VERSION ""

NS_ :

BS_:

BU_: HU

BO_ 642 HU_ADASSwch: 8 HU
 SG_ HU_ACCSet : 1|2@0+ (1,0) [0|3] "" CGW
 SG_ HU_FRMMsgErr : 11|1@0+ (1,0) [0|1] "" CGW
 SG_ HU_TJASet : 13|2@0+ (1,0) [0|3] "" CGW
 SG_ HU_PedestrianProtcSwch : 15|2@0+ (1,0) [0|3] "" CGW
 SG_ HU_HBASet : 17|2@0+ (1,0) [0|3] "" CGW
 SG_ HU_LKASet : 19|2@0+ (1,0) [0|3] "" CGW
 SG_ HU_ADASSnvtyReq : 21|2@0+ (1,0) [0|3] "" CGW
 SG_ HU_LDWSet : 23|2@0+ (1,0) [0|3] "" TBox,CGW
 SG_ HU_FCWRgReq : 3|2@0+ (1,0) [0|3] "" CGW
 SG_ HU_DispdVhclSpd : 30|13@0+ (0.05625,0) [0|300] "" CGW
 SG_ HU_UnitOfDispdVhclSpd : 31|1@0+ (1,0) [0|1] "" CGW
 SG_ HU_DispFltSts : 33|1@0+ (1,0) [0|1] "" CGW
 SG_ HU_BSD_LCASet : 41|2@0+ (1,0) [0|3] "" CGW
 SG_ HU_UPASet : 43|2@0+ (1,0) [0|3] "" PAS,CGW
 SG_ HU_APASlotTypSelt : 45|2@0+ (1,0) [0|3] "" CGW
 SG_ HU_APAEnable : 47|2@0+ (1,0) [0|3] "" CGW
 SG_ HU_FCWSet : 5|2@0+ (1,0) [0|3] "" CGW
 SG_ HU_RCTASet : 53|2@0+ (1,0) [0|3] "" CGW
 SG_ HU_DOWSet : 55|2@0+ (1,0) [0|3] "" CGW
 SG_ ALM_RRDoorLEDFltFb : 60|1@0+ (1,0) [0|1] "" CGW
 SG_ ALM_FRDoorLEDFltFb : 61|1@0+ (1,0) [0|1] "" CGW
 SG_ ALM_RLDoorLEDFltFb : 62|1@0+ (1,0) [0|1] "" CGW
 SG_ ALM_FLDoorLEDFltFb : 63|1@0+ (1,0) [0|1] "" CGW
 SG_ HU_AEBSet : 7|2@0+ (1,0) [0|3] "" CGW

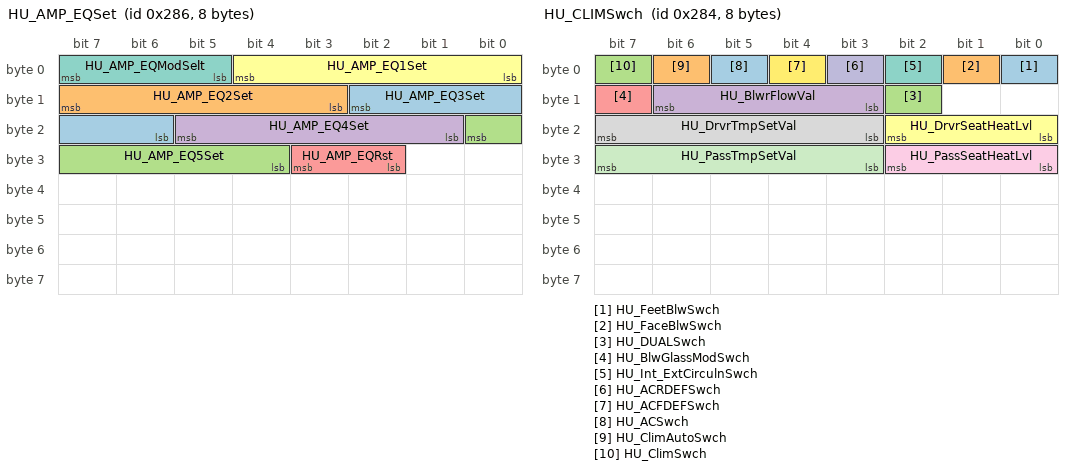
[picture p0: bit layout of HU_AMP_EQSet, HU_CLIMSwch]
BO_ 646 HU_AMP_EQSet: 8 HU
 SG_ HU_AMP_EQ3Set : 10|5@0+ (1,0) [0|31] "" AMP
 SG_ HU_AMP_EQ2Set : 15|5@0+ (1,0) [0|31] "" AMP
 SG_ HU_AMP_EQ5Set : 16|5@0+ (1,0) [0|31] "" AMP
 SG_ HU_AMP_EQ4Set : 21|5@0+ (1,0) [0|31] "" AMP
 SG_ HU_AMP_EQRst : 27|2@0+ (1,0) [0|3] "" AMP
 SG_ HU_AMP_EQ1Set : 4|5@0+ (1,0) [0|31] "" AMP
 SG_ HU_AMP_EQModSelt : 7|3@0+ (1,0) [0|7] "" AMP

BO_ 645 HU_AMP_Set: 8 HU
 SG_ HU_AMP_MuteSet : 1|2@0+ (1,0) [0|3] "" AMP
 SG_ HU_AMP_VhclAlrmVolStepSet : 11|3@0+ (1,0) [0|7] "" AMP
 SG_ HU_AMP_VSCModSeln : 13|2@0+ (1,0) [0|3] "" AMP
 SG_ HU_AMP_LondnessSwch : 15|2@0+ (1,0) [0|3] "" AMP
 SG_ HU_AMP_MainVolStepSet : 19|4@0+ (1,0) [0|15] "" AMP
 SG_ HU_AMP_AudSrcInform : 23|4@0+ (1,0) [0|15] "" AMP
 SG_ HU_AMP_NaviVolStepSet : 29|4@0+ (1,0) [0|15] "" AMP
 SG_ HU_AMP_ESSModSelt : 3|2@0+ (1,0) [0|3] "" AMP
 SG_ HU_AMP_Navi_VRModSet : 31|2@0+ (1,0) [0|3] "" AMP
 SG_ HU_AMP_IntConctVolStepSet : 35|4@0+ (1,0) [0|15] "" AMP
 SG_ HU_AMP_CallVolStepSet : 39|4@0+ (1,0) [0|15] "" AMP
 SG_ HU_AMP_OutputCH_RR : 41|2@0+ (1,0) [0|3] "" AMP
 SG_ HU_AMP_OutputCH_LR : 43|2@0+ (1,0) [0|3] "" AMP
 SG_ HU_AMP_OutputCH_RF : 45|2@0+ (1,0) [0|3] "" AMP
 SG_ HU_AMP_OutputCH_LF : 47|2@0+ (1,0) [0|3] "" AMP
 SG_ HU_AMP_ESSSwch : 5|2@0+ (1,0) [0|3] "" AMP
 SG_ HU_AMP_LeRiAudBalnSet : 55|5@0+ (1,0) [0|31] "" AMP
 SG_ HU_AMP_FrntReAudBalnSet : 63|5@0+ (1,0) [0|31] "" AMP

BO_ 644 HU_CLIMSwch: 8 HU
 SG_ HU_FeetBlwSwch : 0|1@0+ (1,0) [0|1] "" CGW
 SG_ HU_FaceBlwSwch : 1|1@0+ (1,0) [0|1] "" CGW
 SG_ HU_DUALSwch : 10|1@0+ (1,0) [0|1] "" CGW
 SG_ HU_BlwrFlowVal : 14|4@0+ (1,0) [0|15] "" CGW
 SG_ HU_BlwGlassModSwch : 15|1@0+ (1,0) [0|1] "" CGW
 SG_ HU_DrvrSeatHeatLvl : 18|3@0+ (1,0) [0|7] "" CGW
 SG_ HU_Int_ExtCirculnSwch : 2|1@0+ (1,0) [0|1] "" CGW
 SG_ HU_DrvrTmpSetVal : 23|5@0+ (1,0) [0|31] "" CGW
 SG_ HU_PassSeatHeatLvl : 26|3@0+ (1,0) [0|7] "" CGW
 SG_ HU_ACRDEFSwch : 3|1@0+ (1,0) [0|1] "" CGW
 SG_ HU_PassTmpSetVal : 31|5@0+ (1,0) [0|31] "" CGW
 SG_ HU_ACFDEFSwch : 4|1@0+ (1,0) [0|1] "" CGW
 SG_ HU_ACSwch : 5|1@0+ (1,0) [0|1] "" CGW
 SG_ HU_ClimAutoSwch : 6|1@0+ (1,0) [0|1] "" CGW
 SG_ HU_ClimSwch : 7|1@0+ (1,0) [0|1] "" CGW

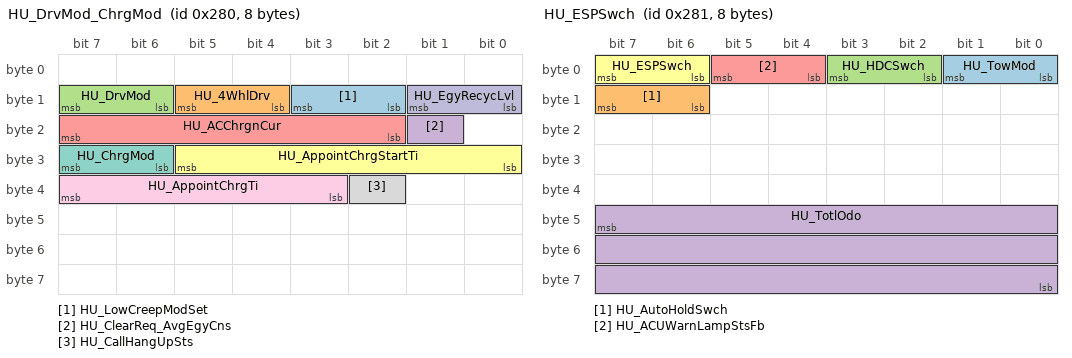
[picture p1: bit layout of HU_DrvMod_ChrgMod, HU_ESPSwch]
BO_ 640 HU_DrvMod_ChrgMod: 8 HU
 SG_ HU_LowCreepModSet : 11|2@0+ (1,0) [0|3] "" CGW
 SG_ HU_4WhlDrv : 13|2@0+ (1,0) [0|3] "" CGW
 SG_ HU_DrvMod : 15|2@0+ (1,0) [0|3] "" CGW
 SG_ HU_ClearReq_AvgEgyCns : 17|1@0+ (1,0) [0|1] "" CGW
 SG_ HU_ACChrgnCur : 23|6@0+ (1,0) [0|40] "A" CGW
 SG_ HU_AppointChrgStartTi : 29|6@0+ (1,0) [0|47] "" TBox
 SG_ HU_ChrgMod : 31|2@0+ (1,0) [0|3] "" TBox
 SG_ HU_CallHangUpSts : 34|1@0+ (1,0) [0|1] "" TBox
 SG_ HU_AppointChrgTi : 39|5@0+ (1,0) [0|23] "" TBox
 SG_ HU_EgyRecycLvl : 9|2@0+ (1,0) [0|3] "" CGW

BO_ 641 HU_ESPSwch: 8 HU
 SG_ HU_TowMod : 1|2@0+ (1,0) [0|3] "" CGW
 SG_ HU_AutoHoldSwch : 15|2@0+ (1,0) [0|3] "" CGW
 SG_ HU_HDCSwch : 3|2@0+ (1,0) [0|3] "" CGW
 SG_ HU_TotlOdo : 47|24@0+ (0.1,0) [0|999999.9] "km" TBox,CGW
 SG_ HU_ACUWarnLampStsFb : 5|2@0+ (1,0) [0|3] "" CGW
 SG_ HU_ESPSwch : 7|2@0+ (1,0) [0|3] "" CGW

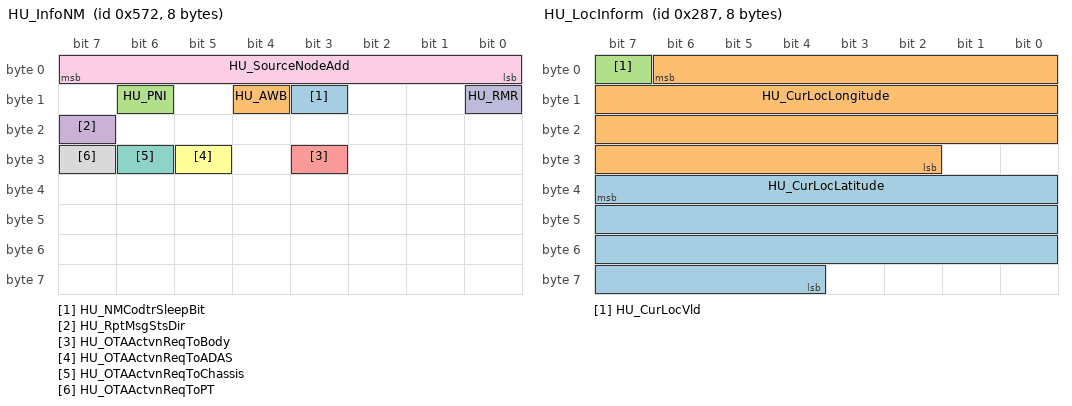
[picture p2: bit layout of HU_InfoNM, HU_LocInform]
BO_ 1394 HU_InfoNM: 8 HU
 SG_ HU_NMCodtrSleepBit : 11|1@0+ (1,0) [0|1] "" TBox,AMP,CGW
 SG_ HU_AWB : 12|1@0+ (1,0) [0|1] "" TBox,AMP,CGW
 SG_ HU_PNI : 14|1@0+ (1,0) [0|1] "" TBox,AMP,CGW
 SG_ HU_RptMsgStsDir : 23|1@0+ (1,0) [0|1] "" Vector__XXX
 SG_ HU_OTAActvnReqToBody : 27|1@0+ (1,0) [0|1] "" CGW
 SG_ HU_OTAActvnReqToADAS : 29|1@0+ (1,0) [0|1] "" CGW
 SG_ HU_OTAActvnReqToChassis : 30|1@0+ (1,0) [0|1] "" CGW
 SG_ HU_OTAActvnReqToPT : 31|1@0+ (1,0) [0|1] "" CGW
 SG_ HU_SourceNodeAdd : 7|8@0+ (1,0) [114|114] "" TBox,AMP,CGW
 SG_ HU_RMR : 8|1@0+ (1,0) [0|1] "" TBox,AMP,CGW

BO_ 647 HU_LocInform: 8 HU
 SG_ HU_CurLocLatitude : 39|28@0+ (0.000001,-90) [-90|90] "degree" TBox
 SG_ HU_CurLocLongitude : 6|29@0+ (0.000001,-180) [-180|180] "degree" TBox
 SG_ HU_CurLocVld : 7|1@0+ (1,0) [0|1] "" TBox

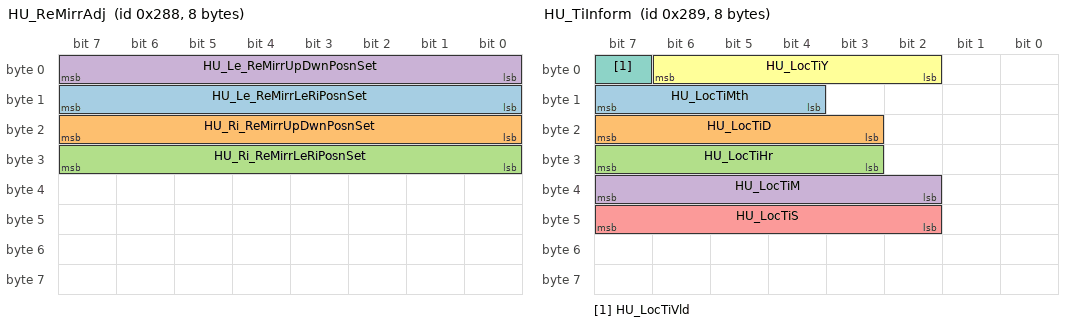
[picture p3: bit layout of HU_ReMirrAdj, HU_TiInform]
BO_ 648 HU_ReMirrAdj: 8 HU
 SG_ HU_Le_ReMirrLeRiPosnSet : 15|8@0+ (1,0) [0|255] "" CGW
 SG_ HU_Ri_ReMirrUpDwnPosnSet : 23|8@0+ (1,0) [0|255] "" CGW
 SG_ HU_Ri_ReMirrLeRiPosnSet : 31|8@0+ (1,0) [0|255] "" CGW
 SG_ HU_Le_ReMirrUpDwnPosnSet : 7|8@0+ (1,0) [0|255] "" CGW

BO_ 649 HU_TiInform: 8 HU
 SG_ HU_LocTiMth : 15|4@0+ (1,0) [1|12] "month" TBox,CGW
 SG_ HU_LocTiD : 23|5@0+ (1,0) [1|31] "day" TBox,CGW
 SG_ HU_LocTiHr : 31|5@0+ (1,0) [0|23] "hour" TBox,CGW
 SG_ HU_LocTiM : 39|6@0+ (1,0) [0|59] "minute" TBox,CGW
 SG_ HU_LocTiS : 47|6@0+ (1,0) [0|59] "second" TBox,CGW
 SG_ HU_LocTiY : 6|5@0+ (1,2019) [2019|2050] "year" TBox,CGW
 SG_ HU_LocTiVld : 7|1@0+ (1,0) [0|1] "" TBox,CGW

BO_ 643 HU_iBCMSwch: 8 HU
 SG_ HU_SwchBkGndLiAdj : 15|4@0+ (1,0) [0|15] "" CGW
 SG_ HU_ForcingPwrON : 16|1@0+ (1,0) [0|1] "" CGW
 SG_ HU_FolwHomeTiAdj : 19|3@0+ (1,0) [0|7] "" CGW
 SG_ HU_FolwHomeReq : 21|2@0+ (1,0) [0|3] "" CGW
 SG_ HU_MirrAutoFoldSet : 23|2@0+ (1,0) [0|3] "" CGW
 SG_ HU_PBDReq : 25|2@0+ (1,0) [0|3] "" CGW
 SG_ HU_LokgCarSet : 27|2@0+ (1,0) [0|3] "" AMP,CGW
 SG_ HU_VSG_PWSSwch : 29|2@0+ (1,0) [0|3] "" AMP,CGW
 SG_ HU_HeadlampHeiAdj : 3|3@0+ (1,0) [0|7] "" CGW
 SG_ HU_AutoSpdLockSet : 31|2@0+ (1,0) [0|3] "" CGW
 SG_ HU_SrSwchReq : 37|2@0+ (1,0) [0|3] "" CGW
 SG_ HU_WprMaintMod : 39|2@0+ (1,0) [0|3] "" CGW
 SG_ HU_SeatVertAdjMotTarPosn : 47|7@0+ (1,0) [0|100] "%" CGW
 SG_ HU_SeatHznAdjMotTarPosn : 55|7@0+ (1,0) [0|100] "%" CGW
 SG_ HU_LiReq : 6|3@0+ (1,0) [0|7] "" CGW
 SG_ HU_SeatTltgAdjMotTarPosn : 63|7@0+ (1,0) [0|100] "%" CGW
 SG_ HU_DeActvSt : 7|1@0+ (1,0) [0|1] "" CGW

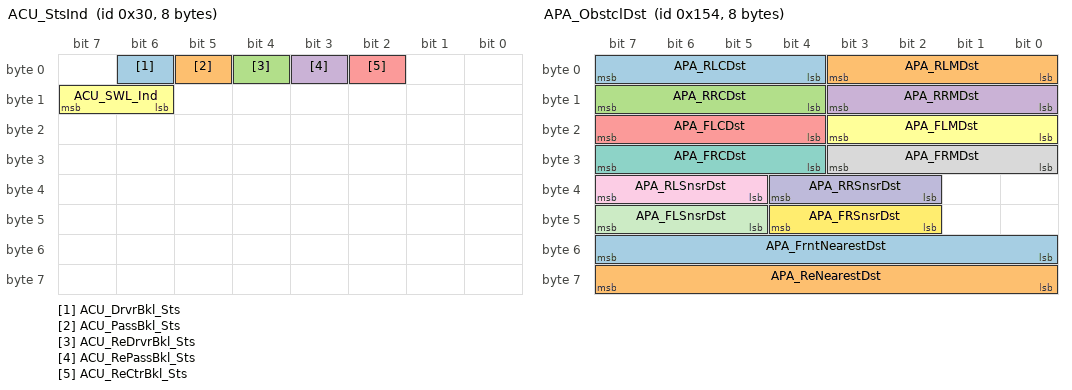
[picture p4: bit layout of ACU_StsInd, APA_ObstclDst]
BO_ 48 ACU_StsInd: 8 CGW
 SG_ ACU_DrvrBkl_Sts : 6|1@0+ (1,0) [0|1] "" TBox,HU
 SG_ ACU_PassBkl_Sts : 5|1@0+ (1,0) [0|1] "" HU
 SG_ ACU_ReDrvrBkl_Sts : 4|1@0+ (1,0) [0|1] "" HU
 SG_ ACU_RePassBkl_Sts : 3|1@0+ (1,0) [0|1] "" HU
 SG_ ACU_ReCtrBkl_Sts : 2|1@0+ (1,0) [0|1] "" HU
 SG_ ACU_SWL_Ind : 15|2@0+ (1,0) [0|3] "" HU

BO_ 896 AMP_Sts: 1 AMP
 SG_ AMP_HU_PwrSt : 7|2@0+ (1,0) [0|3] "" HU

BO_ 340 APA_ObstclDst: 8 CGW
 SG_ APA_RLCDst : 7|4@0+ (1,0) [0|2] "" HU
 SG_ APA_RLMDst : 3|4@0+ (1,0) [0|15] "" HU
 SG_ APA_RRCDst : 15|4@0+ (1,0) [0|2] "" HU
 SG_ APA_RRMDst : 11|4@0+ (1,0) [0|15] "" HU
 SG_ APA_FLCDst : 23|4@0+ (1,0) [0|2] "" HU
 SG_ APA_FLMDst : 19|4@0+ (1,0) [0|15] "" HU
 SG_ APA_FRCDst : 31|4@0+ (1,0) [0|2] "" HU
 SG_ APA_FRMDst : 27|4@0+ (1,0) [0|15] "" HU
 SG_ APA_RLSnsrDst : 39|3@0+ (1,0) [0|2] "" HU
 SG_ APA_RRSnsrDst : 36|3@0+ (1,0) [0|2] "" HU
 SG_ APA_FLSnsrDst : 47|3@0+ (1,0) [0|2] "" HU
 SG_ APA_FRSnsrDst : 44|3@0+ (1,0) [0|2] "" HU
 SG_ APA_FrntNearestDst : 55|8@0+ (1,0) [0|250] "cm" HU
 SG_ APA_ReNearestDst : 63|8@0+ (1,0) [0|250] "cm" HU

BO_ 535 BCU_ModlTmp: 8 CGW
 SG_ BCU_RemChrgTi : 33|10@0+ (1,0) [0|1023] "min" TBox,HU

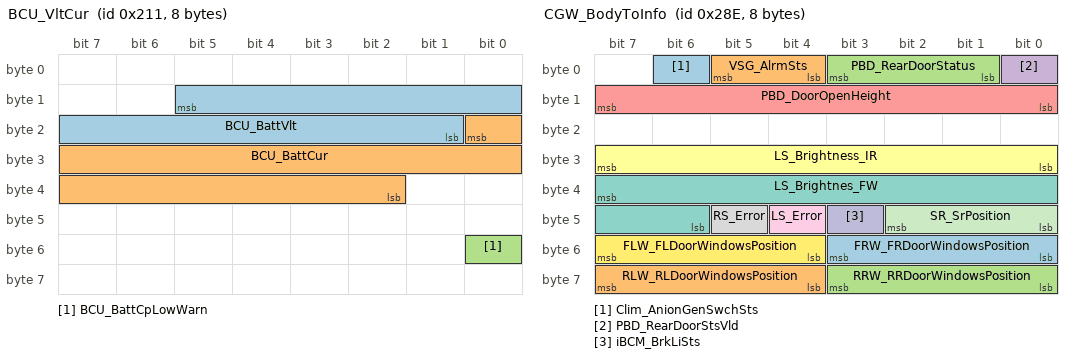
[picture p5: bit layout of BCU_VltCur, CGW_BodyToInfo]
BO_ 529 BCU_VltCur: 8 CGW
 SG_ BCU_BattVlt : 13|13@0+ (0.1,0) [0|500] "V" TBox,HU
 SG_ BCU_BattCur : 16|15@0+ (0.1,-1200) [-1200|1200] "A" TBox,HU
 SG_ BCU_BattCpLowWarn : 48|1@0+ (1,0) [0|1] "" TBox,HU

BO_ 536 BCU_WarnInfo: 8 CGW
 SG_ BCU_BattOverTmp : 15|1@0+ (1,0) [0|1] "" TBox,HU

BO_ 653 CGW_ADASToInfo: 8 CGW
 SG_ APA_SysFltFlg : 7|2@0+ (1,0) [0|3] "" HU
 SG_ APA_WarnIdn : 5|2@0+ (1,0) [0|3] "" HU
 SG_ APA_WarnTyp : 3|4@0+ (1,0) [0|15] "" HU
 SG_ APA_RecoverINTIndcn : 15|3@0+ (1,0) [0|7] "" HU
 SG_ APA_QuitIndcn : 12|5@0+ (1,0) [0|31] "" HU
 SG_ APA_FctIndcn : 23|3@0+ (1,0) [0|7] "" HU
 SG_ APA_St : 20|3@0+ (1,0) [0|7] "" HU
 SG_ APA_PrkSlotSt : 17|2@0+ (1,0) [0|3] "" HU
 SG_ APA_SeltSide : 31|2@0+ (1,0) [0|2] "" HU
 SG_ APA_PrkNotice : 28|5@0+ (1,0) [0|31] "" HU
 SG_ APA_Mod : 39|3@0+ (1,0) [0|7] "" HU
 SG_ APA_PAS_BtnPrs : 36|1@0+ (1,0) [0|1] "" HU
 SG_ APA_PrkgPerc : 47|7@0+ (1,0) [0|100] "%" HU
 SG_ RMR_L_RCTA_WarnReq : 55|2@0+ (1,0) [0|3] "" HU
 SG_ RMR_R_RCTA_WarnReq : 53|2@0+ (1,0) [0|3] "" HU
 SG_ RMR_RSDS_BliSts : 51|1@0+ (1,0) [0|1] "" HU
 SG_ RMR_RCTAResp : 50|1@0+ (1,0) [0|1] "" HU
 SG_ RMR_LCAResp : 49|1@0+ (1,0) [0|1] "" HU
 SG_ RMR_DOWResp : 48|1@0+ (1,0) [0|1] "" HU
 SG_ RMR_RSDS_LCA_RCTA_ErrSts : 40|1@0+ (1,0) [0|1] "" HU
 SG_ RMR_RSDS_DOW_ErrSts : 63|2@0+ (1,0) [0|3] "" HU
 SG_ RMR_L_DOW_WarnReq : 61|3@0+ (1,0) [0|7] "" HU
 SG_ RMR_R_DOW_WarnReq : 58|3@0+ (1,0) [0|7] "" HU
 SG_ RMR_L_BSD_LCA_WarnReq : 35|2@0+ (1,0) [0|3] "" HU
 SG_ RMR_R_BSD_LCA_WarnReq : 33|2@0+ (1,0) [0|3] "" HU

BO_ 654 CGW_BodyToInfo: 8 CGW
 SG_ Clim_AnionGenSwchSts : 6|1@0+ (1,0) [0|1] "" TBox,HU
 SG_ VSG_AlrmSts : 5|2@0+ (1,0) [0|3] "" HU
 SG_ PBD_RearDoorStatus : 3|3@0+ (1,0) [0|7] "" HU
 SG_ PBD_RearDoorStsVld : 0|1@0+ (1,0) [0|1] "" HU
 SG_ PBD_DoorOpenHeight : 15|8@0+ (1,0) [0|100] "%" HU
 SG_ LS_Brightness_IR : 31|8@0+ (400,0) [0|101200] "Lux" HU
 SG_ LS_Brightnes_FW : 39|10@0+ (6,0) [0|6126] "Lux" HU
 SG_ RS_Error : 45|1@0+ (1,0) [0|1] "" HU
 SG_ LS_Error : 44|1@0+ (1,0) [0|1] "" HU
 SG_ iBCM_BrkLiSts : 43|1@0+ (1,0) [0|1] "" HU
 SG_ SR_SrPosition : 42|3@0+ (1,0) [0|7] "" TBox,HU
 SG_ FLW_FLDoorWindowsPosition : 55|4@0+ (1,0) [0|15] "" TBox,HU
 SG_ FRW_FRDoorWindowsPosition : 51|4@0+ (1,0) [0|15] "" TBox,HU
 SG_ RLW_RLDoorWindowsPosition : 63|4@0+ (1,0) [0|15] "" TBox,HU
 SG_ RRW_RRDoorWindowsPosition : 59|4@0+ (1,0) [0|15] "" TBox,HU

BO_ 371 CGW_PTToInfo_2: 8 CGW
 SG_ CDU_OBCACVlt : 40|9@0+ (1,0) [0|500] "V" HU
 SG_ CDU_OBCACCur : 63|8@0+ (0.5,-63) [-63|63] "A" HU

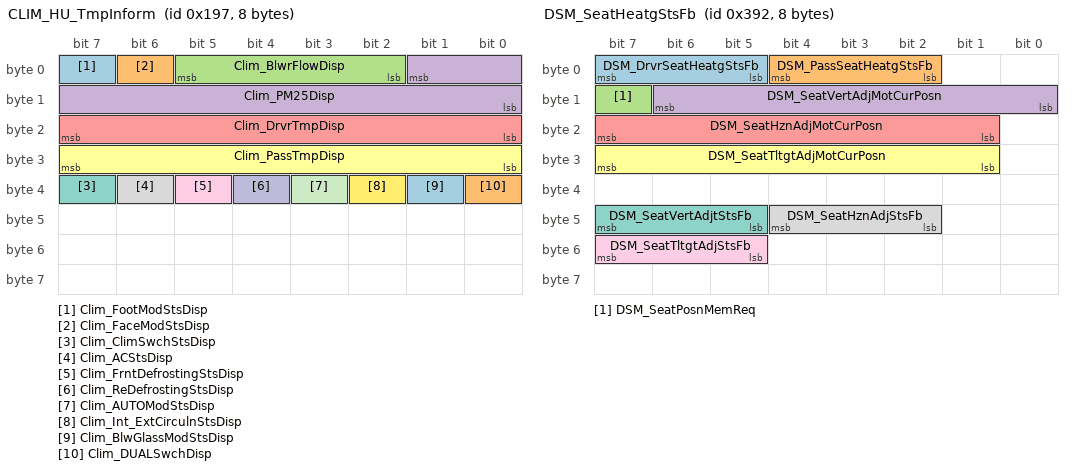
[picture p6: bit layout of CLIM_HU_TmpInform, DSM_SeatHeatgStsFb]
BO_ 407 CLIM_HU_TmpInform: 8 CGW
 SG_ Clim_FootModStsDisp : 7|1@0+ (1,0) [0|1] "" HU
 SG_ Clim_FaceModStsDisp : 6|1@0+ (1,0) [0|1] "" HU
 SG_ Clim_BlwrFlowDisp : 5|4@0+ (1,0) [0|15] "" TBox,HU
 SG_ Clim_PM25Disp : 1|10@0+ (1,0) [0|999] "ug/m3" TBox,HU
 SG_ Clim_DrvrTmpDisp : 23|8@0+ (1,0) [0|255] "" HU
 SG_ Clim_PassTmpDisp : 31|8@0+ (1,0) [0|255] "" HU
 SG_ Clim_ClimSwchStsDisp : 39|1@0+ (1,0) [0|1] "" HU
 SG_ Clim_ACStsDisp : 38|1@0+ (1,0) [0|1] "" HU
 SG_ Clim_FrntDefrostingStsDisp : 37|1@0+ (1,0) [0|1] "" HU
 SG_ Clim_ReDefrostingStsDisp : 36|1@0+ (1,0) [0|1] "" HU
 SG_ Clim_AUTOModStsDisp : 35|1@0+ (1,0) [0|1] "" HU
 SG_ Clim_Int_ExtCirculnStsDisp : 34|1@0+ (1,0) [0|1] "" HU
 SG_ Clim_BlwGlassModStsDisp : 33|1@0+ (1,0) [0|1] "" HU
 SG_ Clim_DUALSwchDisp : 32|1@0+ (1,0) [0|1] "" HU

BO_ 914 DSM_SeatHeatgStsFb: 8 CGW
 SG_ DSM_DrvrSeatHeatgStsFb : 7|3@0+ (1,0) [0|7] "" HU
 SG_ DSM_PassSeatHeatgStsFb : 4|3@0+ (1,0) [0|7] "" HU
 SG_ DSM_SeatPosnMemReq : 15|1@0+ (1,0) [0|1] "" HU
 SG_ DSM_SeatVertAdjMotCurPosn : 14|7@0+ (1,0) [0|100] "%" HU
 SG_ DSM_SeatHznAdjMotCurPosn : 23|7@0+ (1,0) [0|100] "%" HU
 SG_ DSM_SeatTltgtAdjMotCurPosn : 31|7@0+ (1,0) [0|100] "%" HU
 SG_ DSM_SeatVertAdjtStsFb : 47|3@0+ (1,0) [0|7] "" HU
 SG_ DSM_SeatHznAdjStsFb : 44|3@0+ (1,0) [0|7] "" HU
 SG_ DSM_SeatTltgtAdjStsFb : 55|3@0+ (1,0) [0|7] "" HU

BO_ 576 FRM_PEBSToESP: 8 CGW
 SG_ FRM_PEBS_AEBReq : 15|1@0+ (1,0) [0|1] "" HU
 SG_ FRM_ACCMod : 44|3@0+ (1,0) [0|7] "" HU
 SG_ FRM_DispVelocitySet : 16|9@0+ (0.5,0) [0|255.5] "km/h" HU
 SG_ FRM_TiGapSet : 39|2@0+ (1,0) [0|3] "" HU
 SG_ FRM_TextInform : 37|3@0+ (1,0) [0|7] "" HU
 SG_ FRM_FCWSetFb : 34|1@0+ (1,0) [0|1] "" HU
 SG_ FRM_AEBSetFb : 33|1@0+ (1,0) [0|1] "" HU
 SG_ FRM_PedestrianProtcSwchFb : 32|1@0+ (1,0) [0|1] "" HU
 SG_ FRM_DxTarObj : 47|2@0+ (1,0) [0|3] "" HU
 SG_ FRM_ObjVld : 45|1@0+ (1,0) [0|1] "" HU
 SG_ FRM_AEB_Flt : 20|1@0+ (1,0) [0|1] "" HU
 SG_ FRM_FCW_LatentWarn : 19|1@0+ (1,0) [0|1] "" HU
 SG_ FRM_FCW_Flt : 18|1@0+ (1,0) [0|1] "" HU
 SG_ FRM_FCW_PreWarn : 17|1@0+ (1,0) [0|1] "" HU
 SG_ FRM_TakeOverReq : 52|1@0+ (1,0) [0|1] "" HU
 SG_ FRM_TJATextInform : 41|2@0+ (1,0) [0|3] "" HU
 SG_ FRM_TJAMod : 55|3@0+ (1,0) [0|7] "" HU
 SG_ FRM_3_MsgRolgCntr : 51|4@0+ (1,0) [0|15] "" HU
 SG_ FRM_3_CRCChks : 63|8@0+ (1,0) [0|255] "" HU

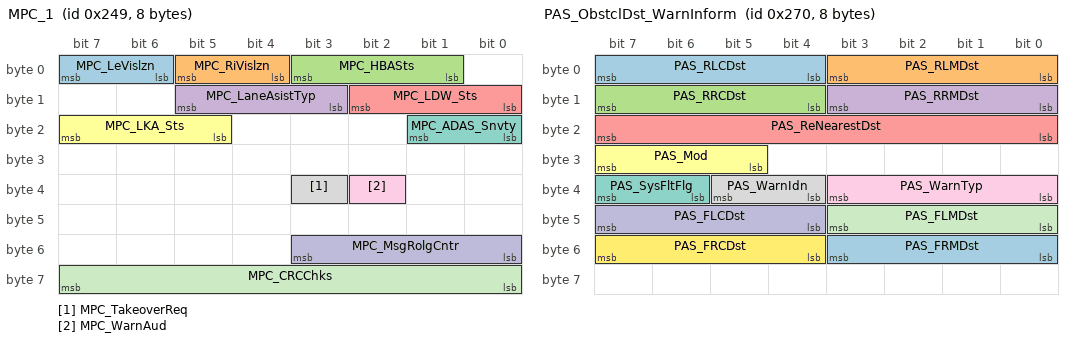
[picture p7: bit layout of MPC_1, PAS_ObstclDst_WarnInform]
BO_ 585 MPC_1: 8 CGW
 SG_ MPC_LeVislzn : 7|2@0+ (1,0) [0|3] "" TBox,HU
 SG_ MPC_RiVislzn : 5|2@0+ (1,0) [0|3] "" TBox,HU
 SG_ MPC_HBASts : 3|3@0+ (1,0) [0|7] "" HU
 SG_ MPC_LaneAsistTyp : 13|3@0+ (1,0) [0|7] "" HU
 SG_ MPC_LDW_Sts : 10|3@0+ (1,0) [0|7] "" TBox,HU
 SG_ MPC_LKA_Sts : 23|3@0+ (1,0) [0|7] "" HU
 SG_ MPC_ADAS_Snvty : 17|2@0+ (1,0) [0|3] "" HU
 SG_ MPC_TakeoverReq : 35|1@0+ (1,0) [0|1] "" HU
 SG_ MPC_WarnAud : 34|1@0+ (1,0) [0|1] "" HU
 SG_ MPC_MsgRolgCntr : 51|4@0+ (1,0) [0|15] "" HU
 SG_ MPC_CRCChks : 63|8@0+ (1,0) [0|255] "" HU

BO_ 624 PAS_ObstclDst_WarnInform: 8 PAS
 SG_ PAS_RLCDst : 7|4@0+ (1,0) [0|2] "" HU
 SG_ PAS_RLMDst : 3|4@0+ (1,0) [0|15] "" HU
 SG_ PAS_RRCDst : 15|4@0+ (1,0) [0|2] "" HU
 SG_ PAS_RRMDst : 11|4@0+ (1,0) [0|15] "" HU
 SG_ PAS_ReNearestDst : 23|8@0+ (1,0) [0|250] "cm" HU
 SG_ PAS_Mod : 31|3@0+ (1,0) [0|7] "" HU
 SG_ PAS_SysFltFlg : 39|2@0+ (1,0) [0|3] "" HU
 SG_ PAS_WarnIdn : 37|2@0+ (1,0) [0|3] "" HU
 SG_ PAS_WarnTyp : 35|4@0+ (1,0) [0|15] "" HU
 SG_ PAS_FLCDst : 47|4@0+ (1,0) [0|2] "" HU
 SG_ PAS_FLMDst : 43|4@0+ (1,0) [0|15] "" HU
 SG_ PAS_FRCDst : 55|4@0+ (1,0) [0|2] "" HU
 SG_ PAS_FRMDst : 51|4@0+ (1,0) [0|15] "" HU

BO_ 196 SAS_SteerAg: 8 CGW
 SG_ SAS_SteerAg : 7|16@0+ (0.0625,-2048) [-720|720] "Deg" TBox,HU
 SG_ SAS_SteerAgVld : 25|1@0+ (1,0) [0|1] "" TBox,HU

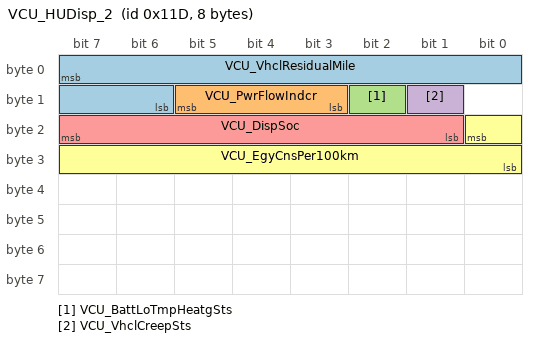
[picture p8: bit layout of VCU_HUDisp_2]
BO_ 285 VCU_HUDisp_2: 8 CGW
 SG_ VCU_VhclResidualMile : 7|10@0+ (1,0) [0|800] "km" TBox,HU
 SG_ VCU_PwrFlowIndcr : 13|3@0+ (1,0) [0|7] "" HU
 SG_ VCU_BattLoTmpHeatgSts : 10|1@0+ (1,0) [0|1] "" HU
 SG_ VCU_VhclCreepSts : 9|1@0+ (1,0) [0|1] "" HU
 SG_ VCU_DispSoc : 23|7@0+ (1,0) [0|100] "%" TBox,HU
 SG_ VCU_EgyCnsPer100km : 16|9@0+ (0.1,0) [0|30] "kwh/100km" TBox,HU

CM_ " ";

CM_ SG_ 640 HU_LowCreepModSet "HU_LowCreepModeSet
低速蠕动模式开关";
CM_ SG_ 640 HU_4WhlDrv "HU_4WheelDrive
4WD驱动模式";
CM_ SG_ 640 HU_DrvMod "HU_DriveMode
驾驶模式";
CM_ SG_ 640 HU_ClearReq_AvgEgyCns "HU_Average Energy Consum Clear Request
平均能耗清零请求信号";
CM_ SG_ 640 HU_ACChrgnCur "HU_ACChargingCurrent
交流充电电流";
CM_ SG_ 640 HU_AppointChrgStartTi "HU_AppointChargeStartTime
充电预约开始时间";
CM_ SG_ 640 HU_ChrgMod "HU_ChargeMode
充电模式";
CM_ SG_ 640 HU_CallHangUpSts "HU_CallHangUpStatus
电话挂断状态";
CM_ SG_ 640 HU_AppointChrgTi "HU_AppointChargeTime
预约充电时长";
CM_ SG_ 640 HU_EgyRecycLvl "HU_EnergyRecycleLevel
能量回收等级";
CM_ SG_ 643 HU_SwchBkGndLiAdj "HU_SwitchBackgroundLightAdjust
车内开关背景光亮度调节";
CM_ SG_ 643 HU_ForcingPwrON "Forcing Power ON
强制上电请求";
CM_ SG_ 643 HU_FolwHomeTiAdj "HU_FollowHomeTimeAdjust
跟随回家功能时间调节";
CM_ SG_ 643 HU_FolwHomeReq "HU_FollowHomeReq
跟随回家功能开关请求";
CM_ SG_ 643 HU_MirrAutoFoldSet "HU_MirrorAutoFoldSet
后视镜自动折叠";
CM_ SG_ 643 HU_PBDReq "HU_PBDRequest
电动尾门请求信号";
CM_ SG_ 643 HU_LokgCarSet "HU_LookingCarSet
寻车HORN鸣叫设置";
CM_ SG_ 643 HU_VSG_PWSSwch "PWS(PedestrianWarningSystem) Switch
行人警示系统开关（上电默认开）";
CM_ SG_ 643 HU_HeadlampHeiAdj "HU_HeadlampHeightAdjust
大灯高度调节";
CM_ SG_ 643 HU_AutoSpdLockSet "HU_AutoSpeedLockSet
自动落锁设置";
CM_ SG_ 643 HU_SrSwchReq "Sunroof Switch Request
天窗开关请求";
CM_ SG_ 643 HU_WprMaintMod "Wiper Maintenance Mode
雨刮维修模式";
CM_ SG_ 643 HU_SeatVertAdjMotTarPosn "Seat Vertical Adjust Motor Target Position
座椅垂直调节电机目标位置";
CM_ SG_ 643 HU_SeatHznAdjMotTarPosn "Seat Herizontal Adjust Motor Target Position
座椅上下调节电机目标位置";
CM_ SG_ 643 HU_LiReq "HU_LightRequest
灯光点亮请求";
CM_ SG_ 643 HU_SeatTltgAdjMotTarPosn "Seat Tiltling Adjust Motor Target Position
座椅靠背角度调节电机目标位置";
CM_ SG_ 643 HU_DeActvSt "HU_DeActiveState
主机非活跃状态";
CM_ SG_ 644 HU_FeetBlwSwch "HU_FeetBlowSwitch
吹脚按钮开关";
CM_ SG_ 644 HU_FaceBlwSwch "HU_FaceBlowSwitch
吹面按钮开关";
CM_ SG_ 644 HU_DUALSwch "HU_DUALSwitch
DUAL开关";
CM_ SG_ 644 HU_BlwrFlowVal "Blower Air volume value
鼓风机风量值";
CM_ SG_ 644 HU_BlwGlassModSwch "Glass Blowing Mode Switch
吹玻璃模式开关";
CM_ SG_ 644 HU_DrvrSeatHeatLvl "Driver Seat Heating Level
主驾座椅加热等级";
CM_ SG_ 644 HU_Int_ExtCirculnSwch "HU_Internal/externalCirculationSwitch
内外循环开关";
CM_ SG_ 644 HU_DrvrTmpSetVal "Driver Setting Temperature Value 
主驾设定温度值";
CM_ SG_ 644 HU_PassSeatHeatLvl "Passenger Seat Heating Level
副驾座椅加热等级";
CM_ SG_ 644 HU_ACRDEFSwch "HU_ACRDEFSwitch
后除霜开关";
CM_ SG_ 644 HU_PassTmpSetVal "Passenge Setting Temperature Value 
副驾设定温度值";
CM_ SG_ 644 HU_ACFDEFSwch "HU_ACFDEFSwitch
前除霜开关";
CM_ SG_ 644 HU_ACSwch "HU_ACSwitch
AC开关";
CM_ SG_ 644 HU_ClimAutoSwch "HU_ClimateAutoSwitch
Auto按键开关";
CM_ SG_ 644 HU_ClimSwch "HU_ClimateSwitch
Climate开关（电源开关）";
CM_ SG_ 641 HU_TowMod "HU_TowMode
拖车模式";
CM_ SG_ 641 HU_AutoHoldSwch "HU_AutoHoldSwitch
AutoHold开关";
CM_ SG_ 641 HU_HDCSwch "HU_HDCSwitch
HDC开关信号";
CM_ SG_ 641 HU_TotlOdo "HU_TotalOdometer
累计里程";
CM_ SG_ 641 HU_ACUWarnLampStsFb "HU_AirbagWarningLampStatusFeedback
ACU故障指示灯状态反馈";
CM_ SG_ 641 HU_ESPSwch "HU_ESPSwitch
ESP开关";
CM_ SG_ 647 HU_CurLocLatitude "HU_CurrentLocationLatitude
当前位置纬度";
CM_ SG_ 647 HU_CurLocLongitude "HU_CurrentLocationLongitude
当前位置经度";
CM_ SG_ 647 HU_CurLocVld "HU_CurrentLocationValid
当前位置信息有效";
CM_ SG_ 642 HU_ACCSet "HU_ACCSet
ACC开关";
CM_ SG_ 642 HU_FRMMsgErr "HU_FRMMessageError.
Error in the FRM message detected by the HMI, like timeout, checksum error or alivecounter error.";
CM_ SG_ 642 HU_TJASet "HU_TJASet
TJA/ICA开关";
CM_ SG_ 642 HU_PedestrianProtcSwch "HU_PedestrianProtectSwitch
行人保护开关";
CM_ SG_ 642 HU_HBASet "HU_HBASet
自动远光灯开关";
CM_ SG_ 642 HU_LKASet "HU_LKASet
LKA开关状态";
CM_ SG_ 642 HU_ADASSnvtyReq "HU_ADASSensitivityReq
ADAS车道偏离预警灵敏度";
CM_ SG_ 642 HU_LDWSet "HU_LDWSet
LDW车道偏离预警开关";
CM_ SG_ 642 HU_FCWRgReq "HU_FCWRangeReq
FCW距离信号";
CM_ SG_ 642 HU_DispdVhclSpd "Vehicle Speed displayed in HU
HU显示车速";
CM_ SG_ 642 HU_UnitOfDispdVhclSpd "The unit of Vehicle Speed displayed in HU
HU显示车速的单位";
CM_ SG_ 642 HU_DispFltSts "HU_DisplayFailureStatus
Error in the display or display control unit.
HU故障状态";
CM_ SG_ 642 HU_BSD_LCASet "HU_BSD_LCASet
BSD_LCA开关";
CM_ SG_ 642 HU_UPASet "HU_UPASet
UPA开关设置";
CM_ SG_ 642 HU_APASlotTypSelt "HU_APASlotTypeSelect 
水平垂直选择";
CM_ SG_ 642 HU_APAEnable "HU_APAEnable
APA使能信号";
CM_ SG_ 642 HU_FCWSet "HU_FCWSet
FCW前方碰撞预警开关";
CM_ SG_ 642 HU_RCTASet "HU_RCTASet
RCTA横向穿越报警开关";
CM_ SG_ 642 HU_DOWSet "HU_DOWSet
DOW门开警报开关";
CM_ SG_ 642 ALM_RRDoorLEDFltFb "右后门氛围灯LED故障反馈
ALM Fault Feedback for LED";
CM_ SG_ 642 ALM_FRDoorLEDFltFb "右前门氛围灯LED故障反馈
ALM Fault Feedback for LED";
CM_ SG_ 642 ALM_RLDoorLEDFltFb "左后门氛围灯LED故障反馈
ALM Fault Feedback for LED";
CM_ SG_ 642 ALM_FLDoorLEDFltFb "左前门氛围灯LED故障反馈
ALM Fault Feedback for LED";
CM_ SG_ 642 HU_AEBSet "HU_AEBSet
AEB自动紧急制动开关";
CM_ SG_ 645 HU_AMP_MuteSet "Mute/Unmute Set
静音设置";
CM_ SG_ 645 HU_AMP_VhclAlrmVolStepSet "VehicleAlarmVolumeStepSet 
车辆报警提示音量设置（车辆提示报警音）";
CM_ SG_ 645 HU_AMP_VSCModSeln "Vehicle Speed Compensation mode selection
声音车速补偿模式选择（上电默认Middle mode）";
CM_ SG_ 645 HU_AMP_LondnessSwch "Londness Switch
响度补偿开关（上电默认开）";
CM_ SG_ 645 HU_AMP_MainVolStepSet "Main Volume Step Set
多媒体音量设置(0~15step)";
CM_ SG_ 645 HU_AMP_AudSrcInform "Audio Source Information
音源模式设置";
CM_ SG_ 645 HU_AMP_NaviVolStepSet " Navigation volume step set
导航音量设置";
CM_ SG_ 645 HU_AMP_ESSModSelt "HU_AMP_ESSModSelect
车内发动机模拟声选择";
CM_ SG_ 645 HU_AMP_Navi_VRModSet "Navigation/VoiceRecognition(VR) mode set
导航/语音模式设置";
CM_ SG_ 645 HU_AMP_IntConctVolStepSet "Interconnection volume step
语音交互音量设置";
CM_ SG_ 645 HU_AMP_CallVolStepSet "Call volume step set
通话音量设置";
CM_ SG_ 645 HU_AMP_OutputCH_RR "Output Channel_RightRear
右后输出通道(车辆提示报警音）";
CM_ SG_ 645 HU_AMP_OutputCH_LR "Output Channel_LeftRear
左后输出通道(车辆提示报警音）";
CM_ SG_ 645 HU_AMP_OutputCH_RF "Output Channel_RigntFront
右前输出通道(车辆提示报警音）";
CM_ SG_ 645 HU_AMP_OutputCH_LF "Output Channel_LeftFront
左前输出通道(车辆提示报警音）";
CM_ SG_ 645 HU_AMP_ESSSwch "HU_AMP_ESSSwitch
车内发动机模拟声开关";
CM_ SG_ 645 HU_AMP_LeRiAudBalnSet "Left/Right Audio Balance setting(-9,+9)
左/右平衡设置";
CM_ SG_ 645 HU_AMP_FrntReAudBalnSet "Front/Rear audio Balance setting(-9,+9)
前/后平衡设置";
CM_ SG_ 646 HU_AMP_EQ3Set "EQ3设置EQ3 setting";
CM_ SG_ 646 HU_AMP_EQ2Set "EQ2设置EQ2 setting";
CM_ SG_ 646 HU_AMP_EQ5Set "EQ5设置EQ5 setting";
CM_ SG_ 646 HU_AMP_EQ4Set "EQ4 设置EQ4 setting";
CM_ SG_ 646 HU_AMP_EQRst "EQ复位 EQReset";
CM_ SG_ 646 HU_AMP_EQ1Set "EQ1 设置EQ1 setting";
CM_ SG_ 646 HU_AMP_EQModSelt "HU_AMP_EQ模式选择";
CM_ SG_ 649 HU_LocTiMth "HU_LocalTimeMonth
本地时间月";
CM_ SG_ 649 HU_LocTiD "HU_LocalTimeDay
本地时间日";
CM_ SG_ 649 HU_LocTiHr "HU_LocalTimeHour
本地时间时";
CM_ SG_ 649 HU_LocTiM "HU_LocalTimeMinute
本地时间分";
CM_ SG_ 649 HU_LocTiS "HU_LocalTimeSecond
本地时间秒";
CM_ SG_ 649 HU_LocTiY "HU_LocalTimeYear
本地时间年";
CM_ SG_ 649 HU_LocTiVld "HU_LocalTimeValid
本地时间有效位";
CM_ SG_ 1394 HU_NMCodtrSleepBit "NM Coordinator Sleep Bit
网络管理协调睡眠指示位";
CM_ SG_ 1394 HU_AWB "Active wakeup bit
主动唤醒指示位";
CM_ SG_ 1394 HU_PNI "Partial netwark information bit 
局部网络指示位";
CM_ SG_ 1394 HU_RptMsgStsDir "Repeat message State Direction
重复报文状态指示位";
CM_ SG_ 1394 HU_OTAActvnReqToBody "Body Subnet OTA Activation Request
Body网段OTA激活请求";
CM_ SG_ 1394 HU_OTAActvnReqToADAS "ADAS Subnet OTA Activation Request
ADAS网段OTA激活请求";
CM_ SG_ 1394 HU_OTAActvnReqToChassis "Chassis Subnet OTA Activation Request
Chassis网段OTA激活请求";
CM_ SG_ 1394 HU_OTAActvnReqToPT "PT Subnet OTA Activation Request
PT网段OTA激活请求";
CM_ SG_ 1394 HU_SourceNodeAdd "Source Node Address
原节点地址";
CM_ SG_ 1394 HU_RMR "Repeat message request
重复报文请求";
CM_ SG_ 648 HU_Le_ReMirrLeRiPosnSet "Left Rear Mirror Left Right Position Set
左后视镜左右位置调节指令
(0x0: Rightmost  0xFE: Leftmost  0xFF:Location detection failure or temporary unavailability of location information )";
CM_ SG_ 648 HU_Ri_ReMirrUpDwnPosnSet "Right Rear Mirror Up Down Position Set
右后视镜上下位置调节指令
(0x0: Bottommost  0xFE: Topmost  0xFF:Location detection failure or temporary unavailability of location information)";
CM_ SG_ 648 HU_Ri_ReMirrLeRiPosnSet "Right Rear Mirror Left Right Position Set
右后视镜左右位置调节指令
(0x0: Rightmost  0xFE: Leftmost  0xFF:Location detection failure or temporary unavailability of location information )";
CM_ SG_ 648 HU_Le_ReMirrUpDwnPosnSet "Left Rear Mirror Up Down Position Set
左后视镜上下位置调节指令
(0x0: Bottommost  0xFE: Topmost  0xFF:Location detection failure or temporary unavailability of location information)";
CM_ SG_ 896 AMP_HU_PwrSt "State of Power Feedback to HU
AMP向主机反馈Power的状态";
CM_ SG_ 624 PAS_RLCDst "RLCDistance
左后角sensor障碍物距离";
CM_ SG_ 624 PAS_RLMDst "RLMDistance
左后中sensor障碍物距离";
CM_ SG_ 624 PAS_RRCDst "RLMDistance
右后角sensor障碍物距离";
CM_ SG_ 624 PAS_RRMDst "RLMDistance
右后中sensor障碍物距离";
CM_ SG_ 624 PAS_ReNearestDst "RearNearestDistance
后系统最近障碍物距离";
CM_ SG_ 624 PAS_Mod "PAS_Radar Work MODE
倒车雷达的工作模式";
CM_ SG_ 624 PAS_SysFltFlg "PAS_SystemFailureFlag
系统故障";
CM_ SG_ 624 PAS_WarnIdn "PAS_WarningIdentification
报警（前后角位置）识别";
CM_ SG_ 624 PAS_WarnTyp "PAS_WarningType
报警方式识别";
CM_ SG_ 624 PAS_FLCDst "RLMDistance
左前角sensor障碍物距离";
CM_ SG_ 624 PAS_FLMDst "RLMDistance
左前中sensor障碍物距离";
CM_ SG_ 624 PAS_FRCDst "RLMDistance
右前角sensor障碍物距离";
CM_ SG_ 624 PAS_FRMDst "RLMDistance
右前中sensor障碍物距离";
CM_ SG_ 285 VCU_VhclResidualMile "Vehicle residual mileage
剩余续驶里程";
CM_ SG_ 285 VCU_PwrFlowIndcr "Power flow indicator
能量流";
CM_ SG_ 285 VCU_BattLoTmpHeatgSts "Battery low temperature heating status
电池低温加热状态";
CM_ SG_ 285 VCU_VhclCreepSts "Vehicle Creep Status
车辆低速蠕行状态";
CM_ SG_ 285 VCU_DispSoc "SOC used for display
动力电池剩余SOC";
CM_ SG_ 285 VCU_EgyCnsPer100km "Energy consume per 100km
平均百公里能耗";
CM_ SG_ 371 CDU_OBCACVlt "OBC input AC Voltage
OBC当前交流端电压";
CM_ SG_ 371 CDU_OBCACCur "OBC input AC Current
OBC当前交流端电流";
CM_ SG_ 529 BCU_BattVlt "Battery Voltage
电池总电压";
CM_ SG_ 529 BCU_BattCur "Battery current
电池总电流";
CM_ SG_ 529 BCU_BattCpLowWarn "Battery Capacity Low Warning
动力电池荷电量低报警";
CM_ SG_ 535 BCU_RemChrgTi "Remain Charging Time
剩余充电时间";
CM_ SG_ 536 BCU_BattOverTmp "Battery Over Tempeture Waring
动力电池过温报警";
CM_ SG_ 196 SAS_SteerAg "Steering Angle value
方向盘转向角";
CM_ SG_ 196 SAS_SteerAgVld "Steering Angle Valid Check
方向盘转向角有效位";
CM_ SG_ 48 ACU_DrvrBkl_Sts "Driver Buckle Status Information";
CM_ SG_ 48 ACU_PassBkl_Sts "Passenger Buckle Status Information";
CM_ SG_ 48 ACU_ReDrvrBkl_Sts "Rear Driver Buckle Status Information";
CM_ SG_ 48 ACU_RePassBkl_Sts "Rear Passenger Buckle Status Information";
CM_ SG_ 48 ACU_ReCtrBkl_Sts "Rear Center Buckle Status Information";
CM_ SG_ 48 ACU_SWL_Ind "System Warning Lamp(SWL) Indication";
CM_ SG_ 576 FRM_PEBS_AEBReq "Request of the AEB/EBA/AEB-VRU deceleration control.";
CM_ SG_ 576 FRM_ACCMod "The status of the ACC control unit.
The ACC mode should be contained in every message sent by ACC.";
CM_ SG_ 576 FRM_DispVelocitySet "The set speed from driver, should be available as long as ACC is active";
CM_ SG_ 576 FRM_TiGapSet "The set timeGap from driver, should be displayed to driver and if the set value changes";
CM_ SG_ 576 FRM_TextInform "Text Information for Driver which is displayed in Dashboard";
CM_ SG_ 576 FRM_FCWSetFb "Feedback of FCW Set status";
CM_ SG_ 576 FRM_AEBSetFb "Feedback of AEB Set status";
CM_ SG_ 576 FRM_PedestrianProtcSwchFb "Feedback of PedestrianProtectSwitch";
CM_ SG_ 576 FRM_DxTarObj "Distance to the ahead target object in case of Mid-end HMI.";
CM_ SG_ 576 FRM_ObjVld "An ahead target object detected by ACC, to inform the driver.";
CM_ SG_ 576 FRM_AEB_Flt "AEB/EBA fail";
CM_ SG_ 576 FRM_FCW_LatentWarn "FCW_Latet Warning(视觉报警)";
CM_ SG_ 576 FRM_FCW_Flt "FCW fail";
CM_ SG_ 576 FRM_FCW_PreWarn "Acoustic pre warning(声音报警)";
CM_ SG_ 576 FRM_TakeOverReq "The limits of the ACC control reaches, driver should take over.";
CM_ SG_ 576 FRM_TJATextInform "Text Information of TJA which is displayed in Dashboard";
CM_ SG_ 576 FRM_TJAMod "TJA Status";
CM_ SG_ 576 FRM_3_MsgRolgCntr "Alivecounter will be increased one by one from 0 to 15
aliveCounter for monitoring the actuality of the corresponding message
The alive counter should be contained in every message";
CM_ SG_ 576 FRM_3_CRCChks "Checksum for monitoring the actuality of the corresponding message.
The Checksum should be contained in every message sent by ACC.
采用SAE J1850  CRC8校验算法";
CM_ SG_ 585 MPC_LeVislzn "ADAS_LeftVisualization
Left line tracking status";
CM_ SG_ 585 MPC_RiVislzn "ADAS_RightVisualization
Right line tracking status";
CM_ SG_ 585 MPC_HBASts "HBA status";
CM_ SG_ 585 MPC_LaneAsistTyp "ADAS_LaneAssitType";
CM_ SG_ 585 MPC_LDW_Sts "LDW status";
CM_ SG_ 585 MPC_LKA_Sts "LKA status";
CM_ SG_ 585 MPC_ADAS_Snvty "ADAS sensitivity";
CM_ SG_ 585 MPC_TakeoverReq "Take over request to driver";
CM_ SG_ 585 MPC_WarnAud "Audio warning request";
CM_ SG_ 585 MPC_MsgRolgCntr "Alivecounter should be increased one by one from 0 to 15
AliveCounter for monitoring the actuality of the corresponding message. 
The alive counter should be contained in every message sent by ACC.";
CM_ SG_ 585 MPC_CRCChks "Checksum for monitoring the actuality of the corresponding message.
The Checksum should be contained in every message sent by ACC.
采用SAE J1850  CRC8校验算法";
CM_ SG_ 340 APA_RLCDst "RLCDistance
左后角sensor障碍物距离";
CM_ SG_ 340 APA_RLMDst "RLMDistance
左后中sensor障碍物距离";
CM_ SG_ 340 APA_RRCDst "RLMDistance
右后角sensor障碍物距离";
CM_ SG_ 340 APA_RRMDst "RLMDistance
右后中sensor障碍物距离";
CM_ SG_ 340 APA_FLCDst "RLMDistance
左前角sensor障碍物距离";
CM_ SG_ 340 APA_FLMDst "RLMDistance
左前中sensor障碍物距离";
CM_ SG_ 340 APA_FRCDst "RLMDistance
右前角sensor障碍物距离";
CM_ SG_ 340 APA_FRMDst "RLMDistance
右前中sensor障碍物距离";
CM_ SG_ 340 APA_RLSnsrDst "APA_RLSensorDistance
左后侧sensor障碍物距离";
CM_ SG_ 340 APA_RRSnsrDst "APA_RRSensorDistance
右后侧sensor障碍物距离";
CM_ SG_ 340 APA_FLSnsrDst "APA_FLSensorDistance
左前侧sensor障碍物距离";
CM_ SG_ 340 APA_FRSnsrDst "APA_FRSensorDistance
右前侧sensor障碍物距离";
CM_ SG_ 340 APA_FrntNearestDst "FrontNearestDistance
前系统最近障碍物距离";
CM_ SG_ 340 APA_ReNearestDst "RearNearestDistance
后系统最近障碍物距离";
CM_ SG_ 653 APA_SysFltFlg "APA_SystemFailureFlag
系统故障";
CM_ SG_ 653 APA_WarnIdn "APA_WarningIdentification
报警（前后角位置）识别";
CM_ SG_ 653 APA_WarnTyp "APA_WarningType
报警方式识别";
CM_ SG_ 653 APA_RecoverINTIndcn "APA recover interrupt indication
APA可恢复中断提示";
CM_ SG_ 653 APA_QuitIndcn "APA quit reason indication
APA完全退出提示（退出原因）";
CM_ SG_ 653 APA_FctIndcn "APA_FunctionIndication
APA功能指示";
CM_ SG_ 653 APA_St "APA_State 
APA的状态";
CM_ SG_ 653 APA_PrkSlotSt "APA_Park Slot State
停车位置查找状况";
CM_ SG_ 653 APA_SeltSide "APA_SelectedSide
指示当前选中的位置";
CM_ SG_ 653 APA_PrkNotice "APA_ParkNotice
自动泊车过程提示信号";
CM_ SG_ 653 APA_Mod "APA_MODE
倒车雷达的工作模式";
CM_ SG_ 653 APA_PAS_BtnPrs "APA_PAS_ButtonPress
倒车雷达开关状态";
CM_ SG_ 653 APA_PrkgPerc "APA_ParkingPercentage
泊车进度条显示";
CM_ SG_ 653 RMR_L_RCTA_WarnReq "Request RCTA left side warning element";
CM_ SG_ 653 RMR_R_RCTA_WarnReq "Request RCTA right side warning element";
CM_ SG_ 653 RMR_RSDS_BliSts "RSDS Blindness States";
CM_ SG_ 653 RMR_RCTAResp "Indicate RCTA  (Cross Traffic Assist ) ON/OFF status";
CM_ SG_ 653 RMR_LCAResp "Indicate LCA(Lane Change Assist?) ON/OFF status";
CM_ SG_ 653 RMR_DOWResp "Indicate DOW(door open warning) ON/OFF status";
CM_ SG_ 653 RMR_RSDS_LCA_RCTA_ErrSts "Show the LCA/CTA status of  failure";
CM_ SG_ 653 RMR_RSDS_DOW_ErrSts "Show the DOW status of  failure";
CM_ SG_ 653 RMR_L_DOW_WarnReq "Request DOW left side warning element";
CM_ SG_ 653 RMR_R_DOW_WarnReq "Request DOW Right side warning element";
CM_ SG_ 653 RMR_L_BSD_LCA_WarnReq "Request BSD/LCA left side warning element";
CM_ SG_ 653 RMR_R_BSD_LCA_WarnReq "Request BSD/LCA right side warning element";
CM_ SG_ 407 Clim_FootModStsDisp "Blow foot mode status display 
吹脚模式状态显示";
CM_ SG_ 407 Clim_FaceModStsDisp "Blow face mode status display 
吹面模式状态显示";
CM_ SG_ 407 Clim_BlwrFlowDisp "Blower Air Flow display
鼓风机风量显示";
CM_ SG_ 407 Clim_PM25Disp "PM2.5 display
PM2.5显示";
CM_ SG_ 407 Clim_DrvrTmpDisp "Driver Temputer display
主驾驶温度显示";
CM_ SG_ 407 Clim_PassTmpDisp "Passenger Temputer display
副驾驶温度显示";
CM_ SG_ 407 Clim_ClimSwchStsDisp "Climate switch status display
空调开关状态显示（CLIM ON/OFF开关）";
CM_ SG_ 407 Clim_ACStsDisp "AC status display
AC状态显示";
CM_ SG_ 407 Clim_FrntDefrostingStsDisp "Front Defrosting Status display
前除霜模式显示";
CM_ SG_ 407 Clim_ReDefrostingStsDisp "Rear Defrosting Status display
后除霜模式显示";
CM_ SG_ 407 Clim_AUTOModStsDisp "AUTO mode display 
AUTO模式显示";
CM_ SG_ 407 Clim_Int_ExtCirculnStsDisp "Internal/external circulation status display 

内外循环状态显示";
CM_ SG_ 407 Clim_BlwGlassModStsDisp "Blow glass mode status display 
吹玻璃状态显示";
CM_ SG_ 407 Clim_DUALSwchDisp "Clim_DUALSwitch Display
DUAL开关显示";
CM_ SG_ 654 Clim_AnionGenSwchSts "Negative Ion Generator Switch State Signal 
负离子发生器开关状态信号";
CM_ SG_ 654 VSG_AlrmSts "Pedestrian Alarm Status
行人报警器状态";
CM_ SG_ 654 PBD_RearDoorStatus "PBD_RearDoorStatus
电动尾门状态";
CM_ SG_ 654 PBD_RearDoorStsVld "PBD_RearDoorStatusValidity
电动尾门状态有效性";
CM_ SG_ 654 PBD_DoorOpenHeight "PBD_DoorOpenHeight
尾门开启高度";
CM_ SG_ 654 LS_Brightness_IR "上方光亮度值";
CM_ SG_ 654 LS_Brightnes_FW "前方光亮度值";
CM_ SG_ 654 RS_Error "雨量传感器故障标志位";
CM_ SG_ 654 LS_Error "光线传感器故障标志位";
CM_ SG_ 654 iBCM_BrkLiSts "Brake Light Status
刹车灯状态";
CM_ SG_ 654 SR_SrPosition "Sunroof position
天窗位置";
CM_ SG_ 654 FLW_FLDoorWindowsPosition "Left front window position 
左前车窗位置";
CM_ SG_ 654 FRW_FRDoorWindowsPosition "Right front window position 
右前车窗位置";
CM_ SG_ 654 RLW_RLDoorWindowsPosition "Left rear window position
左后车窗位置";
CM_ SG_ 654 RRW_RRDoorWindowsPosition "Rignt rear window position
右后车窗位置";
CM_ SG_ 914 DSM_DrvrSeatHeatgStsFb "Driver Seat Heating Status Feedback
主驾座椅加热状态反馈
";
CM_ SG_ 914 DSM_PassSeatHeatgStsFb "Passenger Seat Heating Status Feedback
副驾座椅加热状态反馈
";
CM_ SG_ 914 DSM_SeatPosnMemReq "Seat Position Memory Request
座椅位置记忆请求";
CM_ SG_ 914 DSM_SeatVertAdjMotCurPosn "Seat Vertical Adjust Motor Current Position
座椅垂直调节电机当前位置";
CM_ SG_ 914 DSM_SeatHznAdjMotCurPosn "Seat Herizontal Adjust Motor Current Position
座椅水平调节电机当前位置";
CM_ SG_ 914 DSM_SeatTltgtAdjMotCurPosn "Seat Tiltling Adjust Motor Current Position
座椅靠背角度调节电机当前位置";
CM_ SG_ 914 DSM_SeatVertAdjtStsFb "Seat Vertical Adjust Status Feedback
座椅垂直调节指令状态反馈";
CM_ SG_ 914 DSM_SeatHznAdjStsFb "Seat Herizontal Adjust Status Feedback
座椅水平调节指令状态反馈";
CM_ SG_ 914 DSM_SeatTltgtAdjStsFb "Seat Tiltling Adjust  Status Feedback
座椅靠背调节指令状态反馈";

BA_DEF_ BO_  "NmMessage" ENUM "No","Yes";
BA_DEF_ BO_  "GenMsgSendType" ENUM  "Cycle","CA","CE","Event","NotUsed","NotUsed","NotUsed","IfActive","NoMsgSendType","NotUsed";
BA_DEF_ BO_  "GenMsgCycleTime" INT 0 0;
BA_DEF_ SG_  "GenSigSendType" ENUM  "Cycle","OnChange","OnWrite","IfActive","OnChangeWithRepetition","OnWriteWithRepetition","IfActiveWithRepetition";
BA_DEF_ SG_  "GenSigStartValue" INT 0 0;
BA_DEF_ BO_  "GenMsgCycleTimeFast" INT 0 0;
BA_DEF_ BO_  "GenMsgNrOfRepetition" INT 0 0;
BA_DEF_  "DBName" STRING ;
BA_DEF_ BO_  "VFrameFormat" ENUM  "StandardCAN","ExtendedCAN","reserved","reserved","reserved","reserved","reserved","reserved","reserved","reserved","reserved","reserved","reserved","reserved","StandardCAN_FD","ExtendedCAN_FD";
BA_DEF_ BU_  "NodeLayerModules" STRING ;
BA_DEF_ BO_  "GenMsgCycleTimeActive" INT 0 500;
BA_DEF_ BU_  "NmNode" ENUM  "Not","Yes";
BA_DEF_  "NmBaseAddress" HEX 1280 1535;
BA_DEF_ BO_  "GenMsgStartDelayTime" INT 0 500;
BA_DEF_  "BusType" STRING ;

BA_DEF_DEF_  "NmMessage" "No";
BA_DEF_DEF_  "GenMsgSendType" "Cycle";
BA_DEF_DEF_  "GenMsgCycleTime" 0;
BA_DEF_DEF_  "GenSigSendType" "Cycle";
BA_DEF_DEF_  "GenSigStartValue" 0;
BA_DEF_DEF_  "GenMsgCycleTimeFast" 0;
BA_DEF_DEF_  "GenMsgNrOfRepetition" 0;
BA_DEF_DEF_  "DBName" "";
BA_DEF_DEF_  "VFrameFormat" "StandardCAN";
BA_DEF_DEF_  "NodeLayerModules" "oseknm01.dll,osek_tp.dll,CANoeILNLVector.dll";
BA_DEF_DEF_  "GenMsgCycleTimeActive" 100;
BA_DEF_DEF_  "NmNode" "Not";
BA_DEF_DEF_  "NmBaseAddress" 1280;
BA_DEF_DEF_  "GenMsgStartDelayTime" 200;
BA_DEF_DEF_  "BusType" "CAN";
BA_ "DBName" "Info";
BA_ "GenMsgCycleTime" BO_ 642 50;
BA_ "GenSigStartValue" SG_ 642 HU_ADASSnvtyReq 1;
BA_ "GenSigStartValue" SG_ 642 HU_FCWRgReq 1;
BA_ "GenMsgCycleTime" BO_ 646 100;
BA_ "GenSigStartValue" SG_ 646 HU_AMP_EQ3Set 9;
BA_ "GenSigStartValue" SG_ 646 HU_AMP_EQ2Set 9;
BA_ "GenSigStartValue" SG_ 646 HU_AMP_EQ5Set 9;
BA_ "GenSigStartValue" SG_ 646 HU_AMP_EQ4Set 9;
BA_ "GenSigStartValue" SG_ 646 HU_AMP_EQ1Set 9;
BA_ "GenMsgCycleTime" BO_ 645 100;
BA_ "GenSigStartValue" SG_ 645 HU_AMP_VhclAlrmVolStepSet 4;
BA_ "GenSigStartValue" SG_ 645 HU_AMP_VSCModSeln 2;
BA_ "GenSigStartValue" SG_ 645 HU_AMP_LondnessSwch 1;
BA_ "GenSigStartValue" SG_ 645 HU_AMP_MainVolStepSet 10;
BA_ "GenSigStartValue" SG_ 645 HU_AMP_AudSrcInform 1;
BA_ "GenSigStartValue" SG_ 645 HU_AMP_NaviVolStepSet 10;
BA_ "GenSigStartValue" SG_ 645 HU_AMP_IntConctVolStepSet 10;
BA_ "GenSigStartValue" SG_ 645 HU_AMP_CallVolStepSet 10;
BA_ "GenSigStartValue" SG_ 645 HU_AMP_LeRiAudBalnSet 9;
BA_ "GenSigStartValue" SG_ 645 HU_AMP_FrntReAudBalnSet 9;
BA_ "GenMsgCycleTime" BO_ 644 50;
BA_ "GenMsgCycleTime" BO_ 640 100;
BA_ "GenSigStartValue" SG_ 640 HU_ACChrgnCur 5;
BA_ "GenSigStartValue" SG_ 640 HU_EgyRecycLvl 1;
BA_ "GenMsgCycleTime" BO_ 641 50;
BA_ "NmMessage" BO_ 1394 1;
BA_ "GenMsgSendType" BO_ 1394 2;
BA_ "GenMsgCycleTime" BO_ 1394 500;
BA_ "GenMsgCycleTimeFast" BO_ 1394 10;
BA_ "GenMsgNrOfRepetition" BO_ 1394 5;
BA_ "GenSigSendType" SG_ 1394 HU_AWB 5;
BA_ "GenSigSendType" SG_ 1394 HU_OTAActvnReqToBody 5;
BA_ "GenSigSendType" SG_ 1394 HU_OTAActvnReqToADAS 5;
BA_ "GenSigSendType" SG_ 1394 HU_OTAActvnReqToChassis 5;
BA_ "GenSigSendType" SG_ 1394 HU_OTAActvnReqToPT 5;
BA_ "GenSigStartValue" SG_ 1394 HU_SourceNodeAdd 114;
BA_ "GenSigSendType" SG_ 1394 HU_RMR 5;
BA_ "GenMsgCycleTime" BO_ 647 1000;
BA_ "GenSigStartValue" SG_ 647 HU_CurLocVld 1;
BA_ "GenMsgCycleTime" BO_ 648 200;
BA_ "GenSigStartValue" SG_ 648 HU_Le_ReMirrLeRiPosnSet 255;
BA_ "GenSigStartValue" SG_ 648 HU_Ri_ReMirrUpDwnPosnSet 255;
BA_ "GenSigStartValue" SG_ 648 HU_Ri_ReMirrLeRiPosnSet 255;
BA_ "GenSigStartValue" SG_ 648 HU_Le_ReMirrUpDwnPosnSet 255;
BA_ "GenMsgCycleTime" BO_ 649 1000;
BA_ "GenSigStartValue" SG_ 649 HU_LocTiVld 1;
BA_ "GenMsgCycleTime" BO_ 643 100;
BA_ "GenSigStartValue" SG_ 643 HU_FolwHomeTiAdj 1;
BA_ "GenSigStartValue" SG_ 643 HU_SeatVertAdjMotTarPosn 127;
BA_ "GenSigStartValue" SG_ 643 HU_SeatHznAdjMotTarPosn 127;
BA_ "GenSigStartValue" SG_ 643 HU_LiReq 1;
BA_ "GenSigStartValue" SG_ 643 HU_SeatTltgAdjMotTarPosn 127;
BA_ "GenMsgCycleTime" BO_ 48 50;
BA_ "GenMsgCycleTime" BO_ 896 1000;
BA_ "GenMsgCycleTime" BO_ 340 100;
BA_ "GenSigStartValue" SG_ 340 APA_FrntNearestDst 255;
BA_ "GenSigStartValue" SG_ 340 APA_ReNearestDst 255;
BA_ "GenMsgCycleTime" BO_ 535 1000;
BA_ "GenMsgCycleTime" BO_ 529 10;
BA_ "GenSigStartValue" SG_ 529 BCU_BattCur 12000;
BA_ "GenMsgCycleTime" BO_ 536 1000;
BA_ "GenMsgCycleTime" BO_ 653 100;
BA_ "GenMsgCycleTime" BO_ 654 100;
BA_ "GenSigStartValue" SG_ 654 LS_Brightness_IR 254;
BA_ "GenSigStartValue" SG_ 654 LS_Brightnes_FW 1022;
BA_ "GenMsgCycleTime" BO_ 371 50;
BA_ "GenSigStartValue" SG_ 371 CDU_OBCACCur 126;
BA_ "GenMsgCycleTime" BO_ 407 50;
BA_ "GenSigStartValue" SG_ 407 Clim_PM25Disp 1000;
BA_ "GenMsgCycleTime" BO_ 914 100;
BA_ "GenMsgCycleTime" BO_ 576 20;
BA_ "GenMsgCycleTime" BO_ 585 20;
BA_ "GenMsgCycleTime" BO_ 624 100;
BA_ "GenSigStartValue" SG_ 624 PAS_ReNearestDst 255;
BA_ "GenMsgCycleTime" BO_ 196 10;
BA_ "GenSigStartValue" SG_ 196 SAS_SteerAg 65535;
BA_ "GenSigStartValue" SG_ 196 SAS_SteerAgVld 1;
BA_ "GenMsgCycleTime" BO_ 285 100;
VAL_ 640 HU_LowCreepModSet 3 "Not used" 2 "Reserved" 1 "Off" 0 "On" ;
VAL_ 640 HU_4WhlDrv 3 "Reserved" 2 "Reserved" 1 "4WheelDrive" 0 "2WheelDrive" ;
VAL_ 640 HU_DrvMod 3 "Invalid" 2 "Sport Mode" 1 "ECO Mode" 0 "Normal Mode" ;
VAL_ 640 HU_ClearReq_AvgEgyCns 1 "Request" 0 "No request" ;
VAL_ 640 HU_ACChrgnCur 63 "Invalid" 62 "Invalid" 61 "Invalid" 60 "Invalid" 59 "Invalid" 58 "Invalid" 57 "Invalid" 56 "Invalid" 55 "Invalid" 54 "Invalid" 53 "Invalid" 52 "Invalid" 51 "Invalid" 50 "Invalid" 49 "Invalid" 48 "Invalid" 47 "Invalid" 46 "Invalid" 45 "Invalid" 44 "Invalid" 43 "Invalid" 42 "Invalid" 41 "Invalid" ;
VAL_ 640 HU_AppointChrgStartTi 63 "Invalid" 62 "Invalid" 61 "Invalid" 60 "Invalid" 59 "Invalid" 58 "Invalid" 57 "Invalid" 56 "Invalid" 55 "Invalid" 54 "Invalid" 53 "Invalid" 52 "Invalid" 51 "Invalid" 50 "Invalid" 49 "Invalid" 48 "Invalid" 47 "23:30" 46 "23:00" 45 "22:30" 44 "22:00" 43 "21:30" 42 "21:00" 41 "20:30" 40 "20:00" 39 "19:30" 38 "19:00" 37 "18:30" 36 "18:00" 35 "17:30" 34 "17:00" 33 "16:30" 32 "16:00" 31 "15:30" 30 "15:00" 29 "14:30" 28 "14:00" 27 "13:30" 26 "13:00" 25 "12:30" 24 "12:00" 23 "11:30" 22 "11:00" 21 "10:30" 20 "10:00" 19 "09:30" 18 "09:00" 17 "08:30" 16 "08:00" 15 "07:30" 14 "07:00" 13 "06:30" 12 "06:00" 11 "05:30" 10 "05:00" 9 "04:30" 8 "04:00" 7 "03:30" 6 "03:00" 5 "02:30" 4 "02:00" 3 "01:30" 2 "01:00" 1 "00:30" 0 "00:00" ;
VAL_ 640 HU_ChrgMod 3 "Reserved" 2 "Reserved" 1 "Appoint Charging Mode" 0 "Normal Charging Mode" ;
VAL_ 640 HU_CallHangUpSts 1 "Hang up" 0 "Call connection" ;
VAL_ 640 HU_AppointChrgTi 31 "Invalid" 30 "Invalid" 29 "Invalid" 28 "Invalid" 27 "Invalid" 26 "Invalid" 25 "Invalid" 24 "Invalid" 23 "12 hour" 22 "11.5 hour" 21 "11 hour" 20 "10.5 hour" 19 "10 hour" 18 "9.5 hour" 17 "9 hour" 16 "8.5 hour" 15 "8 hour" 14 "7.5 hour" 13 "7 hour" 12 "6.5 hour" 11 "6 hour" 10 "5.5hour" 9 "5hour" 8 "4.5hour" 7 "4hour" 6 "3.5hour" 5 "3hour" 4 "2.5hour" 3 "2hour" 2 "1.5hour" 1 "1hour" 0 "0.5hour" ;
VAL_ 640 HU_EgyRecycLvl 3 "Reserved" 2 "High" 1 "Mid" 0 "Low" ;
VAL_ 643 HU_SwchBkGndLiAdj 15 "Reserved" 14 "Reserved" 13 "Reserved" 12 "Reserved" 11 "Reserved" 10 "Reserved" 9 "Reserved" 8 "Reserved" 7 "Reserved" 6 "Reserved" 5 "Reserved" 4 "Reserved" 3 "Level 3" 2 "Level 2(默认亮度等级)" 1 "Level 1" 0 "Off" ;
VAL_ 643 HU_ForcingPwrON 1 "Request" 0 "No Request" ;
VAL_ 643 HU_FolwHomeTiAdj 7 "Reserved" 6 "Reserved" 5 "Reserved" 4 "Reserved" 3 "120s" 2 "60s" 1 "30s" 0 "15s" ;
VAL_ 643 HU_FolwHomeReq 3 "Not used" 2 "Reserved" 1 "On" 0 "Off" ;
VAL_ 643 HU_MirrAutoFoldSet 3 "Not used" 2 "Reserved" 1 "Off" 0 "On" ;
VAL_ 643 HU_PBDReq 3 "Reserved" 2 "Open" 1 "Closed" 0 "No Request" ;
VAL_ 643 HU_LokgCarSet 3 "Not used" 2 "Reserved" 1 "Off" 0 "On" ;
VAL_ 643 HU_VSG_PWSSwch 3 "Not used" 2 "Reserved" 1 "Off" 0 "On" ;
VAL_ 643 HU_HeadlampHeiAdj 7 "Reserved" 6 "Reserved" 5 "5 Level" 4 "4 Level" 3 "3 Level" 2 "2 Level" 1 "1 Level" 0 "0 Level" ;
VAL_ 643 HU_AutoSpdLockSet 3 "Not used" 2 "Reserved" 1 "Off" 0 "On" ;
VAL_ 643 HU_SrSwchReq 3 "Reserved" 2 "Open" 1 "Closed" 0 "No Request" ;
VAL_ 643 HU_WprMaintMod 3 "Reserved" 2 "Active" 1 "Inactive" 0 "No Request" ;
VAL_ 643 HU_SeatVertAdjMotTarPosn 127 "Invalid" ;
VAL_ 643 HU_SeatHznAdjMotTarPosn 127 "Invalid" ;
VAL_ 643 HU_LiReq 7 "Reserved" 6 "Reserved" 5 "Reserved" 4 "Reserved" 3 "OFF" 2 "Low Beam" 1 "Position Lamp" 0 "AUTO" ;
VAL_ 643 HU_SeatTltgAdjMotTarPosn 127 "Invalid" ;
VAL_ 643 HU_DeActvSt 1 "Not Active" 0 "Active" ;
VAL_ 644 HU_FeetBlwSwch 1 "Pressed" 0 "Not Pressed" ;
VAL_ 644 HU_FaceBlwSwch 1 "Pressed" 0 "Not Pressed" ;
VAL_ 644 HU_DUALSwch 1 "Pressed" 0 "No Pressed" ;
VAL_ 644 HU_BlwrFlowVal 15 "Reserved" 14 "Reserved" 13 "Reserved" 12 "Reserved" 11 "Reserved" 10 "Reserved" 9 "Off" 8 "Level 8" 7 "Level 7" 6 "Level 6" 5 "Level 5" 4 "Level 4" 3 "Level 3" 2 "Level 2" 1 "Level 1" 0 "No Request" ;
VAL_ 644 HU_BlwGlassModSwch 1 "Pressed" 0 "Not Pressed" ;
VAL_ 644 HU_DrvrSeatHeatLvl 7 "Reserved" 6 "Reserved" 5 "Reserved" 4 "Off" 3 "Level 3" 2 "Level 2" 1 "Level 1" 0 "No request" ;
VAL_ 644 HU_Int_ExtCirculnSwch 1 "Pressed" 0 "Not Pressed" ;
VAL_ 644 HU_DrvrTmpSetVal 31 "Reserved" 30 "Reserved" 29 "Reserved" 28 "Reserved" 27 "Reserved" 26 "Reserved" 25 "Reserved" 24 "Reserved" 23 "Reserved" 22 "Reserved" 21 "Reserved" 20 "Reserved" 19 "Reserved" 18 "Reserved" 17 "HI" 16 "30℃" 15 "29℃" 14 "28℃" 13 "27℃" 12 "26℃" 11 "25℃" 10 "24℃" 9 "23℃" 8 "22℃" 7 "21℃" 6 "20℃" 5 "19℃" 4 "18℃" 3 "17℃" 2 "16℃" 1 "LO" 0 "No Request" ;
VAL_ 644 HU_PassSeatHeatLvl 7 "Reserved" 6 "Reserved" 5 "Reserved" 4 "Off" 3 "Level 3" 2 "Level 2" 1 "Level 1" 0 "No request" ;
VAL_ 644 HU_ACRDEFSwch 1 "Pressed" 0 "Not Pressed" ;
VAL_ 644 HU_PassTmpSetVal 31 "Reserved" 30 "Reserved" 29 "Reserved" 28 "Reserved" 27 "Reserved" 26 "Reserved" 25 "Reserved" 24 "Reserved" 23 "Reserved" 22 "Reserved" 21 "Reserved" 20 "Reserved" 19 "Reserved" 18 "Reserved" 17 "HI" 16 "30℃" 15 "29℃" 14 "28℃" 13 "27℃" 12 "26℃" 11 "25℃" 10 "24℃" 9 "23℃" 8 "22℃" 7 "21℃" 6 "20℃" 5 "19℃" 4 "18℃" 3 "17℃" 2 "16℃" 1 "LO" 0 "No Request" ;
VAL_ 644 HU_ACFDEFSwch 1 "Pressed" 0 "Not Pressed" ;
VAL_ 644 HU_ACSwch 1 "Pressed" 0 "Not Pressed" ;
VAL_ 644 HU_ClimAutoSwch 1 "Pressed" 0 "Not Pressed" ;
VAL_ 644 HU_ClimSwch 1 "Pressed" 0 "Not Pressed" ;
VAL_ 641 HU_TowMod 3 "Not used" 2 "Reserved" 1 "On" 0 "Off" ;
VAL_ 641 HU_AutoHoldSwch 3 "Not used" 2 "Reserved" 1 "Off" 0 "On" ;
VAL_ 641 HU_HDCSwch 3 "Not used" 2 "Reserved" 1 "On" 0 "Off" ;
VAL_ 641 HU_TotlOdo 16777215 "Invalid" ;
VAL_ 641 HU_ACUWarnLampStsFb 3 "Error(Lamp Failure)" 2 "ACU Warning Lamp Flashing" 1 "ACU Warning Lamp On" 0 "ACU Warning Lamp Off" ;
VAL_ 641 HU_ESPSwch 3 "Reserved" 2 "Sport" 1 "ESP Switch OFF" 0 "ESP Switch ON" ;
VAL_ 647 HU_CurLocVld 1 "Validity" 0 "Invalidity" ;
VAL_ 642 HU_ACCSet 3 "Not used" 2 "Reserved" 1 "Off" 0 "On" ;
VAL_ 642 HU_FRMMsgErr 1 "Error" 0 "No Error" ;
VAL_ 642 HU_TJASet 3 "Not used" 2 "Reserved" 1 "Off" 0 "On" ;
VAL_ 642 HU_PedestrianProtcSwch 3 "Not used" 2 "Reserved" 1 "Off" 0 "On" ;
VAL_ 642 HU_HBASet 3 "Not used" 2 "Reserved" 1 "Off" 0 "On" ;
VAL_ 642 HU_LKASet 3 "Not used" 2 "Reserved" 1 "Off" 0 "On" ;
VAL_ 642 HU_ADASSnvtyReq 3 "Reserved" 2 "High" 1 "Normal" 0 "Low" ;
VAL_ 642 HU_LDWSet 3 "Not used" 2 "Reserved" 1 "On" 0 "Off" ;
VAL_ 642 HU_FCWRgReq 3 "Reserved" 2 "Far" 1 "Middle" 0 "Near" ;
VAL_ 642 HU_DispdVhclSpd 8191 "Invalid" 8190 "Invalid" 8189 "Invalid" 8188 "Invalid" 8187 "Invalid" 8186 "Invalid" 8185 "Invalid" 8184 "Invalid" 8183 "Invalid" 8182 "Invalid" 8181 "Invalid" 8180 "Invalid" 8179 "Invalid" 8178 "Invalid" 8177 "Invalid" 8176 "Invalid" 8175 "Invalid" 8174 "Invalid" 8173 "Invalid" 8172 "Invalid" 8171 "Invalid" 8170 "Invalid" 8169 "Invalid" 8168 "Invalid" 8167 "Invalid" 8166 "Invalid" 8165 "Invalid" 8164 "Invalid" 8163 "Invalid" 8162 "Invalid" 8161 "Invalid" 8160 "Invalid" 8159 "Invalid" 8158 "Invalid" 8157 "Invalid" 8156 "Invalid" 8155 "Invalid" 8154 "Invalid" 8153 "Invalid" 8152 "Invalid" 8151 "Invalid" 8150 "Invalid" 8149 "Invalid" 8148 "Invalid" 8147 "Invalid" 8146 "Invalid" 8145 "Invalid" 8144 "Invalid" 8143 "Invalid" 8142 "Invalid" 8141 "Invalid" 8140 "Invalid" 8139 "Invalid" 8138 "Invalid" 8137 "Invalid" 8136 "Invalid" 8135 "Invalid" 8134 "Invalid" 8133 "Invalid" 8132 "Invalid" 8131 "Invalid" 8130 "Invalid" 8129 "Invalid" 8128 "Invalid" 8127 "Invalid" 8126 "Invalid" 8125 "Invalid" 8124 "Invalid" 8123 "Invalid" 8122 "Invalid" 8121 "Invalid" 8120 "Invalid" 8119 "Invalid" 8118 "Invalid" 8117 "Invalid" 8116 "Invalid" 8115 "Invalid" 8114 "Invalid" 8113 "Invalid" 8112 "Invalid" 8111 "Invalid" 8110 "Invalid" 8109 "Invalid" 8108 "Invalid" 8107 "Invalid" 8106 "Invalid" 8105 "Invalid" 8104 "Invalid" 8103 "Invalid" 8102 "Invalid" 8101 "Invalid" 8100 "Invalid" 8099 "Invalid" 8098 "Invalid" 8097 "Invalid" 8096 "Invalid" 8095 "Invalid" 8094 "Invalid" 8093 "Invalid" 8092 "Invalid" 8091 "Invalid" 8090 "Invalid" 8089 "Invalid" 8088 "Invalid" 8087 "Invalid" 8086 "Invalid" 8085 "Invalid" 8084 "Invalid" 8083 "Invalid" 8082 "Invalid" 8081 "Invalid" 8080 "Invalid" 8079 "Invalid" 8078 "Invalid" 8077 "Invalid" 8076 "Invalid" 8075 "Invalid" 8074 "Invalid" 8073 "Invalid" 8072 "Invalid" 8071 "Invalid" 8070 "Invalid" 8069 "Invalid" 8068 "Invalid" 8067 "Invalid" 8066 "Invalid" 8065 "Invalid" 8064 "Invalid" 8063 "Invalid" 8062 "Invalid" 8061 "Invalid" 8060 "Invalid" 8059 "Invalid" 8058 "Invalid" 8057 "Invalid" 8056 "Invalid" 8055 "Invalid" 8054 "Invalid" 8053 "Invalid" 8052 "Invalid" 8051 "Invalid" 8050 "Invalid" 8049 "Invalid" 8048 "Invalid" 8047 "Invalid" 8046 "Invalid" 8045 "Invalid" 8044 "Invalid" 8043 "Invalid" 8042 "Invalid" 8041 "Invalid" 8040 "Invalid" 8039 "Invalid" 8038 "Invalid" 8037 "Invalid" 8036 "Invalid" 8035 "Invalid" 8034 "Invalid" 8033 "Invalid" 8032 "Invalid" 8031 "Invalid" 8030 "Invalid" 8029 "Invalid" 8028 "Invalid" 8027 "Invalid" 8026 "Invalid" 8025 "Invalid" 8024 "Invalid" 8023 "Invalid" 8022 "Invalid" 8021 "Invalid" 8020 "Invalid" 8019 "Invalid" 8018 "Invalid" 8017 "Invalid" 8016 "Invalid" 8015 "Invalid" 8014 "Invalid" 8013 "Invalid" 8012 "Invalid" 8011 "Invalid" 8010 "Invalid" 8009 "Invalid" 8008 "Invalid" 8007 "Invalid" 8006 "Invalid" 8005 "Invalid" 8004 "Invalid" 8003 "Invalid" 8002 "Invalid" 8001 "Invalid" 8000 "Invalid" 7999 "Invalid" 7998 "Invalid" 7997 "Invalid" 7996 "Invalid" 7995 "Invalid" 7994 "Invalid" 7993 "Invalid" 7992 "Invalid" 7991 "Invalid" 7990 "Invalid" 7989 "Invalid" 7988 "Invalid" 7987 "Invalid" 7986 "Invalid" 7985 "Invalid" 7984 "Invalid" 7983 "Invalid" 7982 "Invalid" 7981 "Invalid" 7980 "Invalid" 7979 "Invalid" 7978 "Invalid" 7977 "Invalid" 7976 "Invalid" 7975 "Invalid" 7974 "Invalid" 7973 "Invalid" 7972 "Invalid" 7971 "Invalid" 7970 "Invalid" 7969 "Invalid" 7968 "Invalid" 7967 "Invalid" 7966 "Invalid" 7965 "Invalid" 7964 "Invalid" 7963 "Invalid" 7962 "Invalid" 7961 "Invalid" 7960 "Invalid" 7959 "Invalid" 7958 "Invalid" 7957 "Invalid" 7956 "Invalid" 7955 "Invalid" 7954 "Invalid" 7953 "Invalid" 7952 "Invalid" 7951 "Invalid" 7950 "Invalid" 7949 "Invalid" 7948 "Invalid" 7947 "Invalid" 7946 "Invalid" 7945 "Invalid" 7944 "Invalid" 7943 "Invalid" 7942 "Invalid" 7941 "Invalid" 7940 "Invalid" 7939 "Invalid" 7938 "Invalid" 7937 "Invalid" 7936 "Invalid" 7935 "Invalid" 7934 "Invalid" 7933 "Invalid" 7932 "Invalid" 7931 "Invalid" 7930 "Invalid" 7929 "Invalid" 7928 "Invalid" 7927 "Invalid" 7926 "Invalid" 7925 "Invalid" 7924 "Invalid" 7923 "Invalid" 7922 "Invalid" 7921 "Invalid" 7920 "Invalid" 7919 "Invalid" 7918 "Invalid" 7917 "Invalid" 7916 "Invalid" 7915 "Invalid" 7914 "Invalid" 7913 "Invalid" 7912 "Invalid" 7911 "Invalid" 7910 "Invalid" 7909 "Invalid" 7908 "Invalid" 7907 "Invalid" 7906 "Invalid" 7905 "Invalid" 7904 "Invalid" 7903 "Invalid" 7902 "Invalid" 7901 "Invalid" 7900 "Invalid" 7899 "Invalid" 7898 "Invalid" 7897 "Invalid" 7896 "Invalid" 7895 "Invalid" 7894 "Invalid" 7893 "Invalid" 7892 "Invalid" 7891 "Invalid" 7890 "Invalid" 7889 "Invalid" 7888 "Invalid" 7887 "Invalid" 7886 "Invalid" 7885 "Invalid" 7884 "Invalid" 7883 "Invalid" 7882 "Invalid" 7881 "Invalid" 7880 "Invalid" 7879 "Invalid" 7878 "Invalid" 7877 "Invalid" 7876 "Invalid" 7875 "Invalid" 7874 "Invalid" 7873 "Invalid" 7872 "Invalid" 7871 "Invalid" 7870 "Invalid" 7869 "Invalid" 7868 "Invalid" 7867 "Invalid" 7866 "Invalid" 7865 "Invalid" 7864 "Invalid" 7863 "Invalid" 7862 "Invalid" 7861 "Invalid" 7860 "Invalid" 7859 "Invalid" 7858 "Invalid" 7857 "Invalid" 7856 "Invalid" 7855 "Invalid" 7854 "Invalid" 7853 "Invalid" 7852 "Invalid" 7851 "Invalid" 7850 "Invalid" 7849 "Invalid" 7848 "Invalid" 7847 "Invalid" 7846 "Invalid" 7845 "Invalid" 7844 "Invalid" 7843 "Invalid" 7842 "Invalid" 7841 "Invalid" 7840 "Invalid" 7839 "Invalid" 7838 "Invalid" 7837 "Invalid" 7836 "Invalid" 7835 "Invalid" 7834 "Invalid" 7833 "Invalid" 7832 "Invalid" 7831 "Invalid" 7830 "Invalid" 7829 "Invalid" 7828 "Invalid" 7827 "Invalid" 7826 "Invalid" 7825 "Invalid" 7824 "Invalid" 7823 "Invalid" 7822 "Invalid" 7821 "Invalid" 7820 "Invalid" 7819 "Invalid" 7818 "Invalid" 7817 "Invalid" 7816 "Invalid" 7815 "Invalid" 7814 "Invalid" 7813 "Invalid" 7812 "Invalid" 7811 "Invalid" 7810 "Invalid" 7809 "Invalid" 7808 "Invalid" 7807 "Invalid" 7806 "Invalid" 7805 "Invalid" 7804 "Invalid" 7803 "Invalid" 7802 "Invalid" 7801 "Invalid" 7800 "Invalid" 7799 "Invalid" 7798 "Invalid" 7797 "Invalid" 7796 "Invalid" 7795 "Invalid" 7794 "Invalid" 7793 "Invalid" 7792 "Invalid" 7791 "Invalid" 7790 "Invalid" 7789 "Invalid" 7788 "Invalid" 7787 "Invalid" 7786 "Invalid" 7785 "Invalid" 7784 "Invalid" 7783 "Invalid" 7782 "Invalid" 7781 "Invalid" 7780 "Invalid" 7779 "Invalid" 7778 "Invalid" 7777 "Invalid" 7776 "Invalid" 7775 "Invalid" 7774 "Invalid" 7773 "Invalid" 7772 "Invalid" 7771 "Invalid" 7770 "Invalid" 7769 "Invalid" 7768 "Invalid" 7767 "Invalid" 7766 "Invalid" 7765 "Invalid" 7764 "Invalid" 7763 "Invalid" 7762 "Invalid" 7761 "Invalid" 7760 "Invalid" 7759 "Invalid" 7758 "Invalid" 7757 "Invalid" 7756 "Invalid" 7755 "Invalid" 7754 "Invalid" 7753 "Invalid" 7752 "Invalid" 7751 "Invalid" 7750 "Invalid" 7749 "Invalid" 7748 "Invalid" 7747 "Invalid" 7746 "Invalid" 7745 "Invalid" 7744 "Invalid" 7743 "Invalid" 7742 "Invalid" 7741 "Invalid" 7740 "Invalid" 7739 "Invalid" 7738 "Invalid" 7737 "Invalid" 7736 "Invalid" 7735 "Invalid" 7734 "Invalid" 7733 "Invalid" 7732 "Invalid" 7731 "Invalid" 7730 "Invalid" 7729 "Invalid" 7728 "Invalid" 7727 "Invalid" 7726 "Invalid" 7725 "Invalid" 7724 "Invalid" 7723 "Invalid" 7722 "Invalid" 7721 "Invalid" 7720 "Invalid" 7719 "Invalid" 7718 "Invalid" 7717 "Invalid" 7716 "Invalid" 7715 "Invalid" 7714 "Invalid" 7713 "Invalid" 7712 "Invalid" 7711 "Invalid" 7710 "Invalid" 7709 "Invalid" 7708 "Invalid" 7707 "Invalid" 7706 "Invalid" 7705 "Invalid" 7704 "Invalid" 7703 "Invalid" 7702 "Invalid" 7701 "Invalid" 7700 "Invalid" 7699 "Invalid" 7698 "Invalid" 7697 "Invalid" 7696 "Invalid" 7695 "Invalid" 7694 "Invalid" 7693 "Invalid" 7692 "Invalid" 7691 "Invalid" 7690 "Invalid" 7689 "Invalid" 7688 "Invalid" 7687 "Invalid" 7686 "Invalid" 7685 "Invalid" 7684 "Invalid" 7683 "Invalid" 7682 "Invalid" 7681 "Invalid" 7680 "Invalid" 7679 "Invalid" 7678 "Invalid" 7677 "Invalid" 7676 "Invalid" 7675 "Invalid" 7674 "Invalid" 7673 "Invalid" 7672 "Invalid" 7671 "Invalid" 7670 "Invalid" 7669 "Invalid" 7668 "Invalid" 7667 "Invalid" 7666 "Invalid" 7665 "Invalid" 7664 "Invalid" 7663 "Invalid" 7662 "Invalid" 7661 "Invalid" 7660 "Invalid" 7659 "Invalid" 7658 "Invalid" 7657 "Invalid" 7656 "Invalid" 7655 "Invalid" 7654 "Invalid" 7653 "Invalid" 7652 "Invalid" 7651 "Invalid" 7650 "Invalid" 7649 "Invalid" 7648 "Invalid" 7647 "Invalid" 7646 "Invalid" 7645 "Invalid" 7644 "Invalid" 7643 "Invalid" 7642 "Invalid" 7641 "Invalid" 7640 "Invalid" 7639 "Invalid" 7638 "Invalid" 7637 "Invalid" 7636 "Invalid" 7635 "Invalid" 7634 "Invalid" 7633 "Invalid" 7632 "Invalid" 7631 "Invalid" 7630 "Invalid" 7629 "Invalid" 7628 "Invalid" 7627 "Invalid" 7626 "Invalid" 7625 "Invalid" 7624 "Invalid" 7623 "Invalid" 7622 "Invalid" 7621 "Invalid" 7620 "Invalid" 7619 "Invalid" 7618 "Invalid" 7617 "Invalid" 7616 "Invalid" 7615 "Invalid" 7614 "Invalid" 7613 "Invalid" 7612 "Invalid" 7611 "Invalid" 7610 "Invalid" 7609 "Invalid" 7608 "Invalid" 7607 "Invalid" 7606 "Invalid" 7605 "Invalid" 7604 "Invalid" 7603 "Invalid" 7602 "Invalid" 7601 "Invalid" 7600 "Invalid" 7599 "Invalid" 7598 "Invalid" 7597 "Invalid" 7596 "Invalid" 7595 "Invalid" 7594 "Invalid" 7593 "Invalid" 7592 "Invalid" 7591 "Invalid" 7590 "Invalid" 7589 "Invalid" 7588 "Invalid" 7587 "Invalid" 7586 "Invalid" 7585 "Invalid" 7584 "Invalid" 7583 "Invalid" 7582 "Invalid" 7581 "Invalid" 7580 "Invalid" 7579 "Invalid" 7578 "Invalid" 7577 "Invalid" 7576 "Invalid" 7575 "Invalid" 7574 "Invalid" 7573 "Invalid" 7572 "Invalid" 7571 "Invalid" 7570 "Invalid" 7569 "Invalid" 7568 "Invalid" 7567 "Invalid" 7566 "Invalid" 7565 "Invalid" 7564 "Invalid" 7563 "Invalid" 7562 "Invalid" 7561 "Invalid" 7560 "Invalid" 7559 "Invalid" 7558 "Invalid" 7557 "Invalid" 7556 "Invalid" 7555 "Invalid" 7554 "Invalid" 7553 "Invalid" 7552 "Invalid" 7551 "Invalid" 7550 "Invalid" 7549 "Invalid" 7548 "Invalid" 7547 "Invalid" 7546 "Invalid" 7545 "Invalid" 7544 "Invalid" 7543 "Invalid" 7542 "Invalid" 7541 "Invalid" 7540 "Invalid" 7539 "Invalid" 7538 "Invalid" 7537 "Invalid" 7536 "Invalid" 7535 "Invalid" 7534 "Invalid" 7533 "Invalid" 7532 "Invalid" 7531 "Invalid" 7530 "Invalid" 7529 "Invalid" 7528 "Invalid" 7527 "Invalid" 7526 "Invalid" 7525 "Invalid" 7524 "Invalid" 7523 "Invalid" 7522 "Invalid" 7521 "Invalid" 7520 "Invalid" 7519 "Invalid" 7518 "Invalid" 7517 "Invalid" 7516 "Invalid" 7515 "Invalid" 7514 "Invalid" 7513 "Invalid" 7512 "Invalid" 7511 "Invalid" 7510 "Invalid" 7509 "Invalid" 7508 "Invalid" 7507 "Invalid" 7506 "Invalid" 7505 "Invalid" 7504 "Invalid" 7503 "Invalid" 7502 "Invalid" 7501 "Invalid" 7500 "Invalid" 7499 "Invalid" 7498 "Invalid" 7497 "Invalid" 7496 "Invalid" 7495 "Invalid" 7494 "Invalid" 7493 "Invalid" 7492 "Invalid" 7491 "Invalid" 7490 "Invalid" 7489 "Invalid" 7488 "Invalid" 7487 "Invalid" 7486 "Invalid" 7485 "Invalid" 7484 "Invalid" 7483 "Invalid" 7482 "Invalid" 7481 "Invalid" 7480 "Invalid" 7479 "Invalid" 7478 "Invalid" 7477 "Invalid" 7476 "Invalid" 7475 "Invalid" 7474 "Invalid" 7473 "Invalid" 7472 "Invalid" 7471 "Invalid" 7470 "Invalid" 7469 "Invalid" 7468 "Invalid" 7467 "Invalid" 7466 "Invalid" 7465 "Invalid" 7464 "Invalid" 7463 "Invalid" 7462 "Invalid" 7461 "Invalid" 7460 "Invalid" 7459 "Invalid" 7458 "Invalid" 7457 "Invalid" 7456 "Invalid" 7455 "Invalid" 7454 "Invalid" 7453 "Invalid" 7452 "Invalid" 7451 "Invalid" 7450 "Invalid" 7449 "Invalid" 7448 "Invalid" 7447 "Invalid" 7446 "Invalid" 7445 "Invalid" 7444 "Invalid" 7443 "Invalid" 7442 "Invalid" 7441 "Invalid" 7440 "Invalid" 7439 "Invalid" 7438 "Invalid" 7437 "Invalid" 7436 "Invalid" 7435 "Invalid" 7434 "Invalid" 7433 "Invalid" 7432 "Invalid" 7431 "Invalid" 7430 "Invalid" 7429 "Invalid" 7428 "Invalid" 7427 "Invalid" 7426 "Invalid" 7425 "Invalid" 7424 "Invalid" 7423 "Invalid" 7422 "Invalid" 7421 "Invalid" 7420 "Invalid" 7419 "Invalid" 7418 "Invalid" 7417 "Invalid" 7416 "Invalid" 7415 "Invalid" 7414 "Invalid" 7413 "Invalid" 7412 "Invalid" 7411 "Invalid" 7410 "Invalid" 7409 "Invalid" 7408 "Invalid" 7407 "Invalid" 7406 "Invalid" 7405 "Invalid" 7404 "Invalid" 7403 "Invalid" 7402 "Invalid" 7401 "Invalid" 7400 "Invalid" 7399 "Invalid" 7398 "Invalid" 7397 "Invalid" 7396 "Invalid" 7395 "Invalid" 7394 "Invalid" 7393 "Invalid" 7392 "Invalid" 7391 "Invalid" 7390 "Invalid" 7389 "Invalid" 7388 "Invalid" 7387 "Invalid" 7386 "Invalid" 7385 "Invalid" 7384 "Invalid" 7383 "Invalid" 7382 "Invalid" 7381 "Invalid" 7380 "Invalid" 7379 "Invalid" 7378 "Invalid" 7377 "Invalid" 7376 "Invalid" 7375 "Invalid" 7374 "Invalid" 7373 "Invalid" 7372 "Invalid" 7371 "Invalid" 7370 "Invalid" 7369 "Invalid" 7368 "Invalid" 7367 "Invalid" 7366 "Invalid" 7365 "Invalid" 7364 "Invalid" 7363 "Invalid" 7362 "Invalid" 7361 "Invalid" 7360 "Invalid" 7359 "Invalid" 7358 "Invalid" 7357 "Invalid" 7356 "Invalid" 7355 "Invalid" 7354 "Invalid" 7353 "Invalid" 7352 "Invalid" 7351 "Invalid" 7350 "Invalid" 7349 "Invalid" 7348 "Invalid" 7347 "Invalid" 7346 "Invalid" 7345 "Invalid" 7344 "Invalid" 7343 "Invalid" 7342 "Invalid" 7341 "Invalid" 7340 "Invalid" 7339 "Invalid" 7338 "Invalid" 7337 "Invalid" 7336 "Invalid" 7335 "Invalid" 7334 "Invalid" 7333 "Invalid" 7332 "Invalid" 7331 "Invalid" 7330 "Invalid" 7329 "Invalid" 7328 "Invalid" 7327 "Invalid" 7326 "Invalid" 7325 "Invalid" 7324 "Invalid" 7323 "Invalid" 7322 "Invalid" 7321 "Invalid" 7320 "Invalid" 7319 "Invalid" 7318 "Invalid" 7317 "Invalid" 7316 "Invalid" 7315 "Invalid" 7314 "Invalid" 7313 "Invalid" 7312 "Invalid" 7311 "Invalid" 7310 "Invalid" 7309 "Invalid" 7308 "Invalid" 7307 "Invalid" 7306 "Invalid" 7305 "Invalid" 7304 "Invalid" 7303 "Invalid" 7302 "Invalid" 7301 "Invalid" 7300 "Invalid" 7299 "Invalid" 7298 "Invalid" 7297 "Invalid" 7296 "Invalid" 7295 "Invalid" 7294 "Invalid" 7293 "Invalid" 7292 "Invalid" 7291 "Invalid" 7290 "Invalid" 7289 "Invalid" 7288 "Invalid" 7287 "Invalid" 7286 "Invalid" 7285 "Invalid" 7284 "Invalid" 7283 "Invalid" 7282 "Invalid" 7281 "Invalid" 7280 "Invalid" 7279 "Invalid" 7278 "Invalid" 7277 "Invalid" 7276 "Invalid" 7275 "Invalid" 7274 "Invalid" 7273 "Invalid" 7272 "Invalid" 7271 "Invalid" 7270 "Invalid" 7269 "Invalid" 7268 "Invalid" 7267 "Invalid" 7266 "Invalid" 7265 "Invalid" 7264 "Invalid" 7263 "Invalid" 7262 "Invalid" 7261 "Invalid" 7260 "Invalid" 7259 "Invalid" 7258 "Invalid" 7257 "Invalid" 7256 "Invalid" 7255 "Invalid" 7254 "Invalid" 7253 "Invalid" 7252 "Invalid" 7251 "Invalid" 7250 "Invalid" 7249 "Invalid" 7248 "Invalid" 7247 "Invalid" 7246 "Invalid" 7245 "Invalid" 7244 "Invalid" 7243 "Invalid" 7242 "Invalid" 7241 "Invalid" 7240 "Invalid" 7239 "Invalid" 7238 "Invalid" 7237 "Invalid" 7236 "Invalid" 7235 "Invalid" 7234 "Invalid" 7233 "Invalid" 7232 "Invalid" 7231 "Invalid" 7230 "Invalid" 7229 "Invalid" 7228 "Invalid" 7227 "Invalid" 7226 "Invalid" 7225 "Invalid" 7224 "Invalid" 7223 "Invalid" 7222 "Invalid" 7221 "Invalid" 7220 "Invalid" 7219 "Invalid" 7218 "Invalid" 7217 "Invalid" 7216 "Invalid" 7215 "Invalid" 7214 "Invalid" 7213 "Invalid" 7212 "Invalid" 7211 "Invalid" 7210 "Invalid" 7209 "Invalid" 7208 "Invalid" 7207 "Invalid" 7206 "Invalid" 7205 "Invalid" 7204 "Invalid" 7203 "Invalid" 7202 "Invalid" 7201 "Invalid" 7200 "Invalid" 7199 "Invalid" 7198 "Invalid" 7197 "Invalid" 7196 "Invalid" 7195 "Invalid" 7194 "Invalid" 7193 "Invalid" 7192 "Invalid" 7191 "Invalid" 7190 "Invalid" 7189 "Invalid" 7188 "Invalid" 7187 "Invalid" 7186 "Invalid" 7185 "Invalid" 7184 "Invalid" 7183 "Invalid" 7182 "Invalid" 7181 "Invalid" 7180 "Invalid" 7179 "Invalid" 7178 "Invalid" 7177 "Invalid" 7176 "Invalid" 7175 "Invalid" 7174 "Invalid" 7173 "Invalid" 7172 "Invalid" 7171 "Invalid" 7170 "Invalid" 7169 "Invalid" 7168 "Invalid" 7167 "Invalid" 7166 "Invalid" 7165 "Invalid" 7164 "Invalid" 7163 "Invalid" 7162 "Invalid" 7161 "Invalid" 7160 "Invalid" 7159 "Invalid" 7158 "Invalid" 7157 "Invalid" 7156 "Invalid" 7155 "Invalid" 7154 "Invalid" 7153 "Invalid" 7152 "Invalid" 7151 "Invalid" 7150 "Invalid" 7149 "Invalid" 7148 "Invalid" 7147 "Invalid" 7146 "Invalid" 7145 "Invalid" 7144 "Invalid" 7143 "Invalid" 7142 "Invalid" 7141 "Invalid" 7140 "Invalid" 7139 "Invalid" 7138 "Invalid" 7137 "Invalid" 7136 "Invalid" 7135 "Invalid" 7134 "Invalid" 7133 "Invalid" 7132 "Invalid" 7131 "Invalid" 7130 "Invalid" 7129 "Invalid" 7128 "Invalid" 7127 "Invalid" 7126 "Invalid" 7125 "Invalid" 7124 "Invalid" 7123 "Invalid" 7122 "Invalid" 7121 "Invalid" 7120 "Invalid" 7119 "Invalid" 7118 "Invalid" 7117 "Invalid" 7116 "Invalid" 7115 "Invalid" 7114 "Invalid" 7113 "Invalid" 7112 "Invalid" 7111 "Invalid" 7110 "Invalid" 7109 "Invalid" 7108 "Invalid" 7107 "Invalid" 7106 "Invalid" 7105 "Invalid" 7104 "Invalid" 7103 "Invalid" 7102 "Invalid" 7101 "Invalid" 7100 "Invalid" 7099 "Invalid" 7098 "Invalid" 7097 "Invalid" 7096 "Invalid" 7095 "Invalid" 7094 "Invalid" 7093 "Invalid" 7092 "Invalid" 7091 "Invalid" 7090 "Invalid" 7089 "Invalid" 7088 "Invalid" 7087 "Invalid" 7086 "Invalid" 7085 "Invalid" 7084 "Invalid" 7083 "Invalid" 7082 "Invalid" 7081 "Invalid" 7080 "Invalid" 7079 "Invalid" 7078 "Invalid" 7077 "Invalid" 7076 "Invalid" 7075 "Invalid" 7074 "Invalid" 7073 "Invalid" 7072 "Invalid" 7071 "Invalid" 7070 "Invalid" 7069 "Invalid" 7068 "Invalid" 7067 "Invalid" 7066 "Invalid" 7065 "Invalid" 7064 "Invalid" 7063 "Invalid" 7062 "Invalid" 7061 "Invalid" 7060 "Invalid" 7059 "Invalid" 7058 "Invalid" 7057 "Invalid" 7056 "Invalid" 7055 "Invalid" 7054 "Invalid" 7053 "Invalid" 7052 "Invalid" 7051 "Invalid" 7050 "Invalid" 7049 "Invalid" 7048 "Invalid" 7047 "Invalid" 7046 "Invalid" 7045 "Invalid" 7044 "Invalid" 7043 "Invalid" 7042 "Invalid" 7041 "Invalid" 7040 "Invalid" 7039 "Invalid" 7038 "Invalid" 7037 "Invalid" 7036 "Invalid" 7035 "Invalid" 7034 "Invalid" 7033 "Invalid" 7032 "Invalid" 7031 "Invalid" 7030 "Invalid" 7029 "Invalid" 7028 "Invalid" 7027 "Invalid" 7026 "Invalid" 7025 "Invalid" 7024 "Invalid" 7023 "Invalid" 7022 "Invalid" 7021 "Invalid" 7020 "Invalid" 7019 "Invalid" 7018 "Invalid" 7017 "Invalid" 7016 "Invalid" 7015 "Invalid" 7014 "Invalid" 7013 "Invalid" 7012 "Invalid" 7011 "Invalid" 7010 "Invalid" 7009 "Invalid" 7008 "Invalid" 7007 "Invalid" 7006 "Invalid" 7005 "Invalid" 7004 "Invalid" 7003 "Invalid" 7002 "Invalid" 7001 "Invalid" 7000 "Invalid" 6999 "Invalid" 6998 "Invalid" 6997 "Invalid" 6996 "Invalid" 6995 "Invalid" 6994 "Invalid" 6993 "Invalid" 6992 "Invalid" 6991 "Invalid" 6990 "Invalid" 6989 "Invalid" 6988 "Invalid" 6987 "Invalid" 6986 "Invalid" 6985 "Invalid" 6984 "Invalid" 6983 "Invalid" 6982 "Invalid" 6981 "Invalid" 6980 "Invalid" 6979 "Invalid" 6978 "Invalid" 6977 "Invalid" 6976 "Invalid" 6975 "Invalid" 6974 "Invalid" 6973 "Invalid" 6972 "Invalid" 6971 "Invalid" 6970 "Invalid" 6969 "Invalid" 6968 "Invalid" 6967 "Invalid" 6966 "Invalid" 6965 "Invalid" 6964 "Invalid" 6963 "Invalid" 6962 "Invalid" 6961 "Invalid" 6960 "Invalid" 6959 "Invalid" 6958 "Invalid" 6957 "Invalid" 6956 "Invalid" 6955 "Invalid" 6954 "Invalid" 6953 "Invalid" 6952 "Invalid" 6951 "Invalid" 6950 "Invalid" 6949 "Invalid" 6948 "Invalid" 6947 "Invalid" 6946 "Invalid" 6945 "Invalid" 6944 "Invalid" 6943 "Invalid" 6942 "Invalid" 6941 "Invalid" 6940 "Invalid" 6939 "Invalid" 6938 "Invalid" 6937 "Invalid" 6936 "Invalid" 6935 "Invalid" 6934 "Invalid" 6933 "Invalid" 6932 "Invalid" 6931 "Invalid" 6930 "Invalid" 6929 "Invalid" 6928 "Invalid" 6927 "Invalid" 6926 "Invalid" 6925 "Invalid" 6924 "Invalid" 6923 "Invalid" 6922 "Invalid" 6921 "Invalid" 6920 "Invalid" 6919 "Invalid" 6918 "Invalid" 6917 "Invalid" 6916 "Invalid" 6915 "Invalid" 6914 "Invalid" 6913 "Invalid" 6912 "Invalid" 6911 "Invalid" 6910 "Invalid" 6909 "Invalid" 6908 "Invalid" 6907 "Invalid" 6906 "Invalid" 6905 "Invalid" 6904 "Invalid" 6903 "Invalid" 6902 "Invalid" 6901 "Invalid" 6900 "Invalid" 6899 "Invalid" 6898 "Invalid" 6897 "Invalid" 6896 "Invalid" 6895 "Invalid" 6894 "Invalid" 6893 "Invalid" 6892 "Invalid" 6891 "Invalid" 6890 "Invalid" 6889 "Invalid" 6888 "Invalid" 6887 "Invalid" 6886 "Invalid" 6885 "Invalid" 6884 "Invalid" 6883 "Invalid" 6882 "Invalid" 6881 "Invalid" 6880 "Invalid" 6879 "Invalid" 6878 "Invalid" 6877 "Invalid" 6876 "Invalid" 6875 "Invalid" 6874 "Invalid" 6873 "Invalid" 6872 "Invalid" 6871 "Invalid" 6870 "Invalid" 6869 "Invalid" 6868 "Invalid" 6867 "Invalid" 6866 "Invalid" 6865 "Invalid" 6864 "Invalid" 6863 "Invalid" 6862 "Invalid" 6861 "Invalid" 6860 "Invalid" 6859 "Invalid" 6858 "Invalid" 6857 "Invalid" 6856 "Invalid" 6855 "Invalid" 6854 "Invalid" 6853 "Invalid" 6852 "Invalid" 6851 "Invalid" 6850 "Invalid" 6849 "Invalid" 6848 "Invalid" 6847 "Invalid" 6846 "Invalid" 6845 "Invalid" 6844 "Invalid" 6843 "Invalid" 6842 "Invalid" 6841 "Invalid" 6840 "Invalid" 6839 "Invalid" 6838 "Invalid" 6837 "Invalid" 6836 "Invalid" 6835 "Invalid" 6834 "Invalid" 6833 "Invalid" 6832 "Invalid" 6831 "Invalid" 6830 "Invalid" 6829 "Invalid" 6828 "Invalid" 6827 "Invalid" 6826 "Invalid" 6825 "Invalid" 6824 "Invalid" 6823 "Invalid" 6822 "Invalid" 6821 "Invalid" 6820 "Invalid" 6819 "Invalid" 6818 "Invalid" 6817 "Invalid" 6816 "Invalid" 6815 "Invalid" 6814 "Invalid" 6813 "Invalid" 6812 "Invalid" 6811 "Invalid" 6810 "Invalid" 6809 "Invalid" 6808 "Invalid" 6807 "Invalid" 6806 "Invalid" 6805 "Invalid" 6804 "Invalid" 6803 "Invalid" 6802 "Invalid" 6801 "Invalid" 6800 "Invalid" 6799 "Invalid" 6798 "Invalid" 6797 "Invalid" 6796 "Invalid" 6795 "Invalid" 6794 "Invalid" 6793 "Invalid" 6792 "Invalid" 6791 "Invalid" 6790 "Invalid" 6789 "Invalid" 6788 "Invalid" 6787 "Invalid" 6786 "Invalid" 6785 "Invalid" 6784 "Invalid" 6783 "Invalid" 6782 "Invalid" 6781 "Invalid" 6780 "Invalid" 6779 "Invalid" 6778 "Invalid" 6777 "Invalid" 6776 "Invalid" 6775 "Invalid" 6774 "Invalid" 6773 "Invalid" 6772 "Invalid" 6771 "Invalid" 6770 "Invalid" 6769 "Invalid" 6768 "Invalid" 6767 "Invalid" 6766 "Invalid" 6765 "Invalid" 6764 "Invalid" 6763 "Invalid" 6762 "Invalid" 6761 "Invalid" 6760 "Invalid" 6759 "Invalid" 6758 "Invalid" 6757 "Invalid" 6756 "Invalid" 6755 "Invalid" 6754 "Invalid" 6753 "Invalid" 6752 "Invalid" 6751 "Invalid" 6750 "Invalid" 6749 "Invalid" 6748 "Invalid" 6747 "Invalid" 6746 "Invalid" 6745 "Invalid" 6744 "Invalid" 6743 "Invalid" 6742 "Invalid" 6741 "Invalid" 6740 "Invalid" 6739 "Invalid" 6738 "Invalid" 6737 "Invalid" 6736 "Invalid" 6735 "Invalid" 6734 "Invalid" 6733 "Invalid" 6732 "Invalid" 6731 "Invalid" 6730 "Invalid" 6729 "Invalid" 6728 "Invalid" 6727 "Invalid" 6726 "Invalid" 6725 "Invalid" 6724 "Invalid" 6723 "Invalid" 6722 "Invalid" 6721 "Invalid" 6720 "Invalid" 6719 "Invalid" 6718 "Invalid" 6717 "Invalid" 6716 "Invalid" 6715 "Invalid" 6714 "Invalid" 6713 "Invalid" 6712 "Invalid" 6711 "Invalid" 6710 "Invalid" 6709 "Invalid" 6708 "Invalid" 6707 "Invalid" 6706 "Invalid" 6705 "Invalid" 6704 "Invalid" 6703 "Invalid" 6702 "Invalid" 6701 "Invalid" 6700 "Invalid" 6699 "Invalid" 6698 "Invalid" 6697 "Invalid" 6696 "Invalid" 6695 "Invalid" 6694 "Invalid" 6693 "Invalid" 6692 "Invalid" 6691 "Invalid" 6690 "Invalid" 6689 "Invalid" 6688 "Invalid" 6687 "Invalid" 6686 "Invalid" 6685 "Invalid" 6684 "Invalid" 6683 "Invalid" 6682 "Invalid" 6681 "Invalid" 6680 "Invalid" 6679 "Invalid" 6678 "Invalid" 6677 "Invalid" 6676 "Invalid" 6675 "Invalid" 6674 "Invalid" 6673 "Invalid" 6672 "Invalid" 6671 "Invalid" 6670 "Invalid" 6669 "Invalid" 6668 "Invalid" 6667 "Invalid" 6666 "Invalid" 6665 "Invalid" 6664 "Invalid" 6663 "Invalid" 6662 "Invalid" 6661 "Invalid" 6660 "Invalid" 6659 "Invalid" 6658 "Invalid" 6657 "Invalid" 6656 "Invalid" 6655 "Invalid" 6654 "Invalid" 6653 "Invalid" 6652 "Invalid" 6651 "Invalid" 6650 "Invalid" 6649 "Invalid" 6648 "Invalid" 6647 "Invalid" 6646 "Invalid" 6645 "Invalid" 6644 "Invalid" 6643 "Invalid" 6642 "Invalid" 6641 "Invalid" 6640 "Invalid" 6639 "Invalid" 6638 "Invalid" 6637 "Invalid" 6636 "Invalid" 6635 "Invalid" 6634 "Invalid" 6633 "Invalid" 6632 "Invalid" 6631 "Invalid" 6630 "Invalid" 6629 "Invalid" 6628 "Invalid" 6627 "Invalid" 6626 "Invalid" 6625 "Invalid" 6624 "Invalid" 6623 "Invalid" 6622 "Invalid" 6621 "Invalid" 6620 "Invalid" 6619 "Invalid" 6618 "Invalid" 6617 "Invalid" 6616 "Invalid" 6615 "Invalid" 6614 "Invalid" 6613 "Invalid" 6612 "Invalid" 6611 "Invalid" 6610 "Invalid" 6609 "Invalid" 6608 "Invalid" 6607 "Invalid" 6606 "Invalid" 6605 "Invalid" 6604 "Invalid" 6603 "Invalid" 6602 "Invalid" 6601 "Invalid" 6600 "Invalid" 6599 "Invalid" 6598 "Invalid" 6597 "Invalid" 6596 "Invalid" 6595 "Invalid" 6594 "Invalid" 6593 "Invalid" 6592 "Invalid" 6591 "Invalid" 6590 "Invalid" 6589 "Invalid" 6588 "Invalid" 6587 "Invalid" 6586 "Invalid" 6585 "Invalid" 6584 "Invalid" 6583 "Invalid" 6582 "Invalid" 6581 "Invalid" 6580 "Invalid" 6579 "Invalid" 6578 "Invalid" 6577 "Invalid" 6576 "Invalid" 6575 "Invalid" 6574 "Invalid" 6573 "Invalid" 6572 "Invalid" 6571 "Invalid" 6570 "Invalid" 6569 "Invalid" 6568 "Invalid" 6567 "Invalid" 6566 "Invalid" 6565 "Invalid" 6564 "Invalid" 6563 "Invalid" 6562 "Invalid" 6561 "Invalid" 6560 "Invalid" 6559 "Invalid" 6558 "Invalid" 6557 "Invalid" 6556 "Invalid" 6555 "Invalid" 6554 "Invalid" 6553 "Invalid" 6552 "Invalid" 6551 "Invalid" 6550 "Invalid" 6549 "Invalid" 6548 "Invalid" 6547 "Invalid" 6546 "Invalid" 6545 "Invalid" 6544 "Invalid" 6543 "Invalid" 6542 "Invalid" 6541 "Invalid" 6540 "Invalid" 6539 "Invalid" 6538 "Invalid" 6537 "Invalid" 6536 "Invalid" 6535 "Invalid" 6534 "Invalid" 6533 "Invalid" 6532 "Invalid" 6531 "Invalid" 6530 "Invalid" 6529 "Invalid" 6528 "Invalid" 6527 "Invalid" 6526 "Invalid" 6525 "Invalid" 6524 "Invalid" 6523 "Invalid" 6522 "Invalid" 6521 "Invalid" 6520 "Invalid" 6519 "Invalid" 6518 "Invalid" 6517 "Invalid" 6516 "Invalid" 6515 "Invalid" 6514 "Invalid" 6513 "Invalid" 6512 "Invalid" 6511 "Invalid" 6510 "Invalid" 6509 "Invalid" 6508 "Invalid" 6507 "Invalid" 6506 "Invalid" 6505 "Invalid" 6504 "Invalid" 6503 "Invalid" 6502 "Invalid" 6501 "Invalid" 6500 "Invalid" 6499 "Invalid" 6498 "Invalid" 6497 "Invalid" 6496 "Invalid" 6495 "Invalid" 6494 "Invalid" 6493 "Invalid" 6492 "Invalid" 6491 "Invalid" 6490 "Invalid" 6489 "Invalid" 6488 "Invalid" 6487 "Invalid" 6486 "Invalid" 6485 "Invalid" 6484 "Invalid" 6483 "Invalid" 6482 "Invalid" 6481 "Invalid" 6480 "Invalid" 6479 "Invalid" 6478 "Invalid" 6477 "Invalid" 6476 "Invalid" 6475 "Invalid" 6474 "Invalid" 6473 "Invalid" 6472 "Invalid" 6471 "Invalid" 6470 "Invalid" 6469 "Invalid" 6468 "Invalid" 6467 "Invalid" 6466 "Invalid" 6465 "Invalid" 6464 "Invalid" 6463 "Invalid" 6462 "Invalid" 6461 "Invalid" 6460 "Invalid" 6459 "Invalid" 6458 "Invalid" 6457 "Invalid" 6456 "Invalid" 6455 "Invalid" 6454 "Invalid" 6453 "Invalid" 6452 "Invalid" 6451 "Invalid" 6450 "Invalid" 6449 "Invalid" 6448 "Invalid" 6447 "Invalid" 6446 "Invalid" 6445 "Invalid" 6444 "Invalid" 6443 "Invalid" 6442 "Invalid" 6441 "Invalid" 6440 "Invalid" 6439 "Invalid" 6438 "Invalid" 6437 "Invalid" 6436 "Invalid" 6435 "Invalid" 6434 "Invalid" 6433 "Invalid" 6432 "Invalid" 6431 "Invalid" 6430 "Invalid" 6429 "Invalid" 6428 "Invalid" 6427 "Invalid" 6426 "Invalid" 6425 "Invalid" 6424 "Invalid" 6423 "Invalid" 6422 "Invalid" 6421 "Invalid" 6420 "Invalid" 6419 "Invalid" 6418 "Invalid" 6417 "Invalid" 6416 "Invalid" 6415 "Invalid" 6414 "Invalid" 6413 "Invalid" 6412 "Invalid" 6411 "Invalid" 6410 "Invalid" 6409 "Invalid" 6408 "Invalid" 6407 "Invalid" 6406 "Invalid" 6405 "Invalid" 6404 "Invalid" 6403 "Invalid" 6402 "Invalid" 6401 "Invalid" 6400 "Invalid" 6399 "Invalid" 6398 "Invalid" 6397 "Invalid" 6396 "Invalid" 6395 "Invalid" 6394 "Invalid" 6393 "Invalid" 6392 "Invalid" 6391 "Invalid" 6390 "Invalid" 6389 "Invalid" 6388 "Invalid" 6387 "Invalid" 6386 "Invalid" 6385 "Invalid" 6384 "Invalid" 6383 "Invalid" 6382 "Invalid" 6381 "Invalid" 6380 "Invalid" 6379 "Invalid" 6378 "Invalid" 6377 "Invalid" 6376 "Invalid" 6375 "Invalid" 6374 "Invalid" 6373 "Invalid" 6372 "Invalid" 6371 "Invalid" 6370 "Invalid" 6369 "Invalid" 6368 "Invalid" 6367 "Invalid" 6366 "Invalid" 6365 "Invalid" 6364 "Invalid" 6363 "Invalid" 6362 "Invalid" 6361 "Invalid" 6360 "Invalid" 6359 "Invalid" 6358 "Invalid" 6357 "Invalid" 6356 "Invalid" 6355 "Invalid" 6354 "Invalid" 6353 "Invalid" 6352 "Invalid" 6351 "Invalid" 6350 "Invalid" 6349 "Invalid" 6348 "Invalid" 6347 "Invalid" 6346 "Invalid" 6345 "Invalid" 6344 "Invalid" 6343 "Invalid" 6342 "Invalid" 6341 "Invalid" 6340 "Invalid" 6339 "Invalid" 6338 "Invalid" 6337 "Invalid" 6336 "Invalid" 6335 "Invalid" 6334 "Invalid" 6333 "Invalid" 6332 "Invalid" 6331 "Invalid" 6330 "Invalid" 6329 "Invalid" 6328 "Invalid" 6327 "Invalid" 6326 "Invalid" 6325 "Invalid" 6324 "Invalid" 6323 "Invalid" 6322 "Invalid" 6321 "Invalid" 6320 "Invalid" 6319 "Invalid" 6318 "Invalid" 6317 "Invalid" 6316 "Invalid" 6315 "Invalid" 6314 "Invalid" 6313 "Invalid" 6312 "Invalid" 6311 "Invalid" 6310 "Invalid" 6309 "Invalid" 6308 "Invalid" 6307 "Invalid" 6306 "Invalid" 6305 "Invalid" 6304 "Invalid" 6303 "Invalid" 6302 "Invalid" 6301 "Invalid" 6300 "Invalid" 6299 "Invalid" 6298 "Invalid" 6297 "Invalid" 6296 "Invalid" 6295 "Invalid" 6294 "Invalid" 6293 "Invalid" 6292 "Invalid" 6291 "Invalid" 6290 "Invalid" 6289 "Invalid" 6288 "Invalid" 6287 "Invalid" 6286 "Invalid" 6285 "Invalid" 6284 "Invalid" 6283 "Invalid" 6282 "Invalid" 6281 "Invalid" 6280 "Invalid" 6279 "Invalid" 6278 "Invalid" 6277 "Invalid" 6276 "Invalid" 6275 "Invalid" 6274 "Invalid" 6273 "Invalid" 6272 "Invalid" 6271 "Invalid" 6270 "Invalid" 6269 "Invalid" 6268 "Invalid" 6267 "Invalid" 6266 "Invalid" 6265 "Invalid" 6264 "Invalid" 6263 "Invalid" 6262 "Invalid" 6261 "Invalid" 6260 "Invalid" 6259 "Invalid" 6258 "Invalid" 6257 "Invalid" 6256 "Invalid" 6255 "Invalid" 6254 "Invalid" 6253 "Invalid" 6252 "Invalid" 6251 "Invalid" 6250 "Invalid" 6249 "Invalid" 6248 "Invalid" 6247 "Invalid" 6246 "Invalid" 6245 "Invalid" 6244 "Invalid" 6243 "Invalid" 6242 "Invalid" 6241 "Invalid" 6240 "Invalid" 6239 "Invalid" 6238 "Invalid" 6237 "Invalid" 6236 "Invalid" 6235 "Invalid" 6234 "Invalid" 6233 "Invalid" 6232 "Invalid" 6231 "Invalid" 6230 "Invalid" 6229 "Invalid" 6228 "Invalid" 6227 "Invalid" 6226 "Invalid" 6225 "Invalid" 6224 "Invalid" 6223 "Invalid" 6222 "Invalid" 6221 "Invalid" 6220 "Invalid" 6219 "Invalid" 6218 "Invalid" 6217 "Invalid" 6216 "Invalid" 6215 "Invalid" 6214 "Invalid" 6213 "Invalid" 6212 "Invalid" 6211 "Invalid" 6210 "Invalid" 6209 "Invalid" 6208 "Invalid" 6207 "Invalid" 6206 "Invalid" 6205 "Invalid" 6204 "Invalid" 6203 "Invalid" 6202 "Invalid" 6201 "Invalid" 6200 "Invalid" 6199 "Invalid" 6198 "Invalid" 6197 "Invalid" 6196 "Invalid" 6195 "Invalid" 6194 "Invalid" 6193 "Invalid" 6192 "Invalid" 6191 "Invalid" 6190 "Invalid" 6189 "Invalid" 6188 "Invalid" 6187 "Invalid" 6186 "Invalid" 6185 "Invalid" 6184 "Invalid" 6183 "Invalid" 6182 "Invalid" 6181 "Invalid" 6180 "Invalid" 6179 "Invalid" 6178 "Invalid" 6177 "Invalid" 6176 "Invalid" 6175 "Invalid" 6174 "Invalid" 6173 "Invalid" 6172 "Invalid" 6171 "Invalid" 6170 "Invalid" 6169 "Invalid" 6168 "Invalid" 6167 "Invalid" 6166 "Invalid" 6165 "Invalid" 6164 "Invalid" 6163 "Invalid" 6162 "Invalid" 6161 "Invalid" 6160 "Invalid" 6159 "Invalid" 6158 "Invalid" 6157 "Invalid" 6156 "Invalid" 6155 "Invalid" 6154 "Invalid" 6153 "Invalid" 6152 "Invalid" 6151 "Invalid" 6150 "Invalid" 6149 "Invalid" 6148 "Invalid" 6147 "Invalid" 6146 "Invalid" 6145 "Invalid" 6144 "Invalid" 6143 "Invalid" 6142 "Invalid" 6141 "Invalid" 6140 "Invalid" 6139 "Invalid" 6138 "Invalid" 6137 "Invalid" 6136 "Invalid" 6135 "Invalid" 6134 "Invalid" 6133 "Invalid" 6132 "Invalid" 6131 "Invalid" 6130 "Invalid" 6129 "Invalid" 6128 "Invalid" 6127 "Invalid" 6126 "Invalid" 6125 "Invalid" 6124 "Invalid" 6123 "Invalid" 6122 "Invalid" 6121 "Invalid" 6120 "Invalid" 6119 "Invalid" 6118 "Invalid" 6117 "Invalid" 6116 "Invalid" 6115 "Invalid" 6114 "Invalid" 6113 "Invalid" 6112 "Invalid" 6111 "Invalid" 6110 "Invalid" 6109 "Invalid" 6108 "Invalid" 6107 "Invalid" 6106 "Invalid" 6105 "Invalid" 6104 "Invalid" 6103 "Invalid" 6102 "Invalid" 6101 "Invalid" 6100 "Invalid" 6099 "Invalid" 6098 "Invalid" 6097 "Invalid" 6096 "Invalid" 6095 "Invalid" 6094 "Invalid" 6093 "Invalid" 6092 "Invalid" 6091 "Invalid" 6090 "Invalid" 6089 "Invalid" 6088 "Invalid" 6087 "Invalid" 6086 "Invalid" 6085 "Invalid" 6084 "Invalid" 6083 "Invalid" 6082 "Invalid" 6081 "Invalid" 6080 "Invalid" 6079 "Invalid" 6078 "Invalid" 6077 "Invalid" 6076 "Invalid" 6075 "Invalid" 6074 "Invalid" 6073 "Invalid" 6072 "Invalid" 6071 "Invalid" 6070 "Invalid" 6069 "Invalid" 6068 "Invalid" 6067 "Invalid" 6066 "Invalid" 6065 "Invalid" 6064 "Invalid" 6063 "Invalid" 6062 "Invalid" 6061 "Invalid" 6060 "Invalid" 6059 "Invalid" 6058 "Invalid" 6057 "Invalid" 6056 "Invalid" 6055 "Invalid" 6054 "Invalid" 6053 "Invalid" 6052 "Invalid" 6051 "Invalid" 6050 "Invalid" 6049 "Invalid" 6048 "Invalid" 6047 "Invalid" 6046 "Invalid" 6045 "Invalid" 6044 "Invalid" 6043 "Invalid" 6042 "Invalid" 6041 "Invalid" 6040 "Invalid" 6039 "Invalid" 6038 "Invalid" 6037 "Invalid" 6036 "Invalid" 6035 "Invalid" 6034 "Invalid" 6033 "Invalid" 6032 "Invalid" 6031 "Invalid" 6030 "Invalid" 6029 "Invalid" 6028 "Invalid" 6027 "Invalid" 6026 "Invalid" 6025 "Invalid" 6024 "Invalid" 6023 "Invalid" 6022 "Invalid" 6021 "Invalid" 6020 "Invalid" 6019 "Invalid" 6018 "Invalid" 6017 "Invalid" 6016 "Invalid" 6015 "Invalid" 6014 "Invalid" 6013 "Invalid" 6012 "Invalid" 6011 "Invalid" 6010 "Invalid" 6009 "Invalid" 6008 "Invalid" 6007 "Invalid" 6006 "Invalid" 6005 "Invalid" 6004 "Invalid" 6003 "Invalid" 6002 "Invalid" 6001 "Invalid" 6000 "Invalid" 5999 "Invalid" 5998 "Invalid" 5997 "Invalid" 5996 "Invalid" 5995 "Invalid" 5994 "Invalid" 5993 "Invalid" 5992 "Invalid" 5991 "Invalid" 5990 "Invalid" 5989 "Invalid" 5988 "Invalid" 5987 "Invalid" 5986 "Invalid" 5985 "Invalid" 5984 "Invalid" 5983 "Invalid" 5982 "Invalid" 5981 "Invalid" 5980 "Invalid" 5979 "Invalid" 5978 "Invalid" 5977 "Invalid" 5976 "Invalid" 5975 "Invalid" 5974 "Invalid" 5973 "Invalid" 5972 "Invalid" 5971 "Invalid" 5970 "Invalid" 5969 "Invalid" 5968 "Invalid" 5967 "Invalid" 5966 "Invalid" 5965 "Invalid" 5964 "Invalid" 5963 "Invalid" 5962 "Invalid" 5961 "Invalid" 5960 "Invalid" 5959 "Invalid" 5958 "Invalid" 5957 "Invalid" 5956 "Invalid" 5955 "Invalid" 5954 "Invalid" 5953 "Invalid" 5952 "Invalid" 5951 "Invalid" 5950 "Invalid" 5949 "Invalid" 5948 "Invalid" 5947 "Invalid" 5946 "Invalid" 5945 "Invalid" 5944 "Invalid" 5943 "Invalid" 5942 "Invalid" 5941 "Invalid" 5940 "Invalid" 5939 "Invalid" 5938 "Invalid" 5937 "Invalid" 5936 "Invalid" 5935 "Invalid" 5934 "Invalid" 5933 "Invalid" 5932 "Invalid" 5931 "Invalid" 5930 "Invalid" 5929 "Invalid" 5928 "Invalid" 5927 "Invalid" 5926 "Invalid" 5925 "Invalid" 5924 "Invalid" 5923 "Invalid" 5922 "Invalid" 5921 "Invalid" 5920 "Invalid" 5919 "Invalid" 5918 "Invalid" 5917 "Invalid" 5916 "Invalid" 5915 "Invalid" 5914 "Invalid" 5913 "Invalid" 5912 "Invalid" 5911 "Invalid" 5910 "Invalid" 5909 "Invalid" 5908 "Invalid" 5907 "Invalid" 5906 "Invalid" 5905 "Invalid" 5904 "Invalid" 5903 "Invalid" 5902 "Invalid" 5901 "Invalid" 5900 "Invalid" 5899 "Invalid" 5898 "Invalid" 5897 "Invalid" 5896 "Invalid" 5895 "Invalid" 5894 "Invalid" 5893 "Invalid" 5892 "Invalid" 5891 "Invalid" 5890 "Invalid" 5889 "Invalid" 5888 "Invalid" 5887 "Invalid" 5886 "Invalid" 5885 "Invalid" 5884 "Invalid" 5883 "Invalid" 5882 "Invalid" 5881 "Invalid" 5880 "Invalid" 5879 "Invalid" 5878 "Invalid" 5877 "Invalid" 5876 "Invalid" 5875 "Invalid" 5874 "Invalid" 5873 "Invalid" 5872 "Invalid" 5871 "Invalid" 5870 "Invalid" 5869 "Invalid" 5868 "Invalid" 5867 "Invalid" 5866 "Invalid" 5865 "Invalid" 5864 "Invalid" 5863 "Invalid" 5862 "Invalid" 5861 "Invalid" 5860 "Invalid" 5859 "Invalid" 5858 "Invalid" 5857 "Invalid" 5856 "Invalid" 5855 "Invalid" 5854 "Invalid" 5853 "Invalid" 5852 "Invalid" 5851 "Invalid" 5850 "Invalid" 5849 "Invalid" 5848 "Invalid" 5847 "Invalid" 5846 "Invalid" 5845 "Invalid" 5844 "Invalid" 5843 "Invalid" 5842 "Invalid" 5841 "Invalid" 5840 "Invalid" 5839 "Invalid" 5838 "Invalid" 5837 "Invalid" 5836 "Invalid" 5835 "Invalid" 5834 "Invalid" 5833 "Invalid" 5832 "Invalid" 5831 "Invalid" 5830 "Invalid" 5829 "Invalid" 5828 "Invalid" 5827 "Invalid" 5826 "Invalid" 5825 "Invalid" 5824 "Invalid" 5823 "Invalid" 5822 "Invalid" 5821 "Invalid" 5820 "Invalid" 5819 "Invalid" 5818 "Invalid" 5817 "Invalid" 5816 "Invalid" 5815 "Invalid" 5814 "Invalid" 5813 "Invalid" 5812 "Invalid" 5811 "Invalid" 5810 "Invalid" 5809 "Invalid" 5808 "Invalid" 5807 "Invalid" 5806 "Invalid" 5805 "Invalid" 5804 "Invalid" 5803 "Invalid" 5802 "Invalid" 5801 "Invalid" 5800 "Invalid" 5799 "Invalid" 5798 "Invalid" 5797 "Invalid" 5796 "Invalid" 5795 "Invalid" 5794 "Invalid" 5793 "Invalid" 5792 "Invalid" 5791 "Invalid" 5790 "Invalid" 5789 "Invalid" 5788 "Invalid" 5787 "Invalid" 5786 "Invalid" 5785 "Invalid" 5784 "Invalid" 5783 "Invalid" 5782 "Invalid" 5781 "Invalid" 5780 "Invalid" 5779 "Invalid" 5778 "Invalid" 5777 "Invalid" 5776 "Invalid" 5775 "Invalid" 5774 "Invalid" 5773 "Invalid" 5772 "Invalid" 5771 "Invalid" 5770 "Invalid" 5769 "Invalid" 5768 "Invalid" 5767 "Invalid" 5766 "Invalid" 5765 "Invalid" 5764 "Invalid" 5763 "Invalid" 5762 "Invalid" 5761 "Invalid" 5760 "Invalid" 5759 "Invalid" 5758 "Invalid" 5757 "Invalid" 5756 "Invalid" 5755 "Invalid" 5754 "Invalid" 5753 "Invalid" 5752 "Invalid" 5751 "Invalid" 5750 "Invalid" 5749 "Invalid" 5748 "Invalid" 5747 "Invalid" 5746 "Invalid" 5745 "Invalid" 5744 "Invalid" 5743 "Invalid" 5742 "Invalid" 5741 "Invalid" 5740 "Invalid" 5739 "Invalid" 5738 "Invalid" 5737 "Invalid" 5736 "Invalid" 5735 "Invalid" 5734 "Invalid" 5733 "Invalid" 5732 "Invalid" 5731 "Invalid" 5730 "Invalid" 5729 "Invalid" 5728 "Invalid" 5727 "Invalid" 5726 "Invalid" 5725 "Invalid" 5724 "Invalid" 5723 "Invalid" 5722 "Invalid" 5721 "Invalid" 5720 "Invalid" 5719 "Invalid" 5718 "Invalid" 5717 "Invalid" 5716 "Invalid" 5715 "Invalid" 5714 "Invalid" 5713 "Invalid" 5712 "Invalid" 5711 "Invalid" 5710 "Invalid" 5709 "Invalid" 5708 "Invalid" 5707 "Invalid" 5706 "Invalid" 5705 "Invalid" 5704 "Invalid" 5703 "Invalid" 5702 "Invalid" 5701 "Invalid" 5700 "Invalid" 5699 "Invalid" 5698 "Invalid" 5697 "Invalid" 5696 "Invalid" 5695 "Invalid" 5694 "Invalid" 5693 "Invalid" 5692 "Invalid" 5691 "Invalid" 5690 "Invalid" 5689 "Invalid" 5688 "Invalid" 5687 "Invalid" 5686 "Invalid" 5685 "Invalid" 5684 "Invalid" 5683 "Invalid" 5682 "Invalid" 5681 "Invalid" 5680 "Invalid" 5679 "Invalid" 5678 "Invalid" 5677 "Invalid" 5676 "Invalid" 5675 "Invalid" 5674 "Invalid" 5673 "Invalid" 5672 "Invalid" 5671 "Invalid" 5670 "Invalid" 5669 "Invalid" 5668 "Invalid" 5667 "Invalid" 5666 "Invalid" 5665 "Invalid" 5664 "Invalid" 5663 "Invalid" 5662 "Invalid" 5661 "Invalid" 5660 "Invalid" 5659 "Invalid" 5658 "Invalid" 5657 "Invalid" 5656 "Invalid" 5655 "Invalid" 5654 "Invalid" 5653 "Invalid" 5652 "Invalid" 5651 "Invalid" 5650 "Invalid" 5649 "Invalid" 5648 "Invalid" 5647 "Invalid" 5646 "Invalid" 5645 "Invalid" 5644 "Invalid" 5643 "Invalid" 5642 "Invalid" 5641 "Invalid" 5640 "Invalid" 5639 "Invalid" 5638 "Invalid" 5637 "Invalid" 5636 "Invalid" 5635 "Invalid" 5634 "Invalid" 5633 "Invalid" 5632 "Invalid" 5631 "Invalid" 5630 "Invalid" 5629 "Invalid" 5628 "Invalid" 5627 "Invalid" 5626 "Invalid" 5625 "Invalid" 5624 "Invalid" 5623 "Invalid" 5622 "Invalid" 5621 "Invalid" 5620 "Invalid" 5619 "Invalid" 5618 "Invalid" 5617 "Invalid" 5616 "Invalid" 5615 "Invalid" 5614 "Invalid" 5613 "Invalid" 5612 "Invalid" 5611 "Invalid" 5610 "Invalid" 5609 "Invalid" 5608 "Invalid" 5607 "Invalid" 5606 "Invalid" 5605 "Invalid" 5604 "Invalid" 5603 "Invalid" 5602 "Invalid" 5601 "Invalid" 5600 "Invalid" 5599 "Invalid" 5598 "Invalid" 5597 "Invalid" 5596 "Invalid" 5595 "Invalid" 5594 "Invalid" 5593 "Invalid" 5592 "Invalid" 5591 "Invalid" 5590 "Invalid" 5589 "Invalid" 5588 "Invalid" 5587 "Invalid" 5586 "Invalid" 5585 "Invalid" 5584 "Invalid" 5583 "Invalid" 5582 "Invalid" 5581 "Invalid" 5580 "Invalid" 5579 "Invalid" 5578 "Invalid" 5577 "Invalid" 5576 "Invalid" 5575 "Invalid" 5574 "Invalid" 5573 "Invalid" 5572 "Invalid" 5571 "Invalid" 5570 "Invalid" 5569 "Invalid" 5568 "Invalid" 5567 "Invalid" 5566 "Invalid" 5565 "Invalid" 5564 "Invalid" 5563 "Invalid" 5562 "Invalid" 5561 "Invalid" 5560 "Invalid" 5559 "Invalid" 5558 "Invalid" 5557 "Invalid" 5556 "Invalid" 5555 "Invalid" 5554 "Invalid" 5553 "Invalid" 5552 "Invalid" 5551 "Invalid" 5550 "Invalid" 5549 "Invalid" 5548 "Invalid" 5547 "Invalid" 5546 "Invalid" 5545 "Invalid" 5544 "Invalid" 5543 "Invalid" 5542 "Invalid" 5541 "Invalid" 5540 "Invalid" 5539 "Invalid" 5538 "Invalid" 5537 "Invalid" 5536 "Invalid" 5535 "Invalid" 5534 "Invalid" 5533 "Invalid" 5532 "Invalid" 5531 "Invalid" 5530 "Invalid" 5529 "Invalid" 5528 "Invalid" 5527 "Invalid" 5526 "Invalid" 5525 "Invalid" 5524 "Invalid" 5523 "Invalid" 5522 "Invalid" 5521 "Invalid" 5520 "Invalid" 5519 "Invalid" 5518 "Invalid" 5517 "Invalid" 5516 "Invalid" 5515 "Invalid" 5514 "Invalid" 5513 "Invalid" 5512 "Invalid" 5511 "Invalid" 5510 "Invalid" 5509 "Invalid" 5508 "Invalid" 5507 "Invalid" 5506 "Invalid" 5505 "Invalid" 5504 "Invalid" 5503 "Invalid" 5502 "Invalid" 5501 "Invalid" 5500 "Invalid" 5499 "Invalid" 5498 "Invalid" 5497 "Invalid" 5496 "Invalid" 5495 "Invalid" 5494 "Invalid" 5493 "Invalid" 5492 "Invalid" 5491 "Invalid" 5490 "Invalid" 5489 "Invalid" 5488 "Invalid" 5487 "Invalid" 5486 "Invalid" 5485 "Invalid" 5484 "Invalid" 5483 "Invalid" 5482 "Invalid" 5481 "Invalid" 5480 "Invalid" 5479 "Invalid" 5478 "Invalid" 5477 "Invalid" 5476 "Invalid" 5475 "Invalid" 5474 "Invalid" 5473 "Invalid" 5472 "Invalid" 5471 "Invalid" 5470 "Invalid" 5469 "Invalid" 5468 "Invalid" 5467 "Invalid" 5466 "Invalid" 5465 "Invalid" 5464 "Invalid" 5463 "Invalid" 5462 "Invalid" 5461 "Invalid" 5460 "Invalid" 5459 "Invalid" 5458 "Invalid" 5457 "Invalid" 5456 "Invalid" 5455 "Invalid" 5454 "Invalid" 5453 "Invalid" 5452 "Invalid" 5451 "Invalid" 5450 "Invalid" 5449 "Invalid" 5448 "Invalid" 5447 "Invalid" 5446 "Invalid" 5445 "Invalid" 5444 "Invalid" 5443 "Invalid" 5442 "Invalid" 5441 "Invalid" 5440 "Invalid" 5439 "Invalid" 5438 "Invalid" 5437 "Invalid" 5436 "Invalid" 5435 "Invalid" 5434 "Invalid" 5433 "Invalid" 5432 "Invalid" 5431 "Invalid" 5430 "Invalid" 5429 "Invalid" 5428 "Invalid" 5427 "Invalid" 5426 "Invalid" 5425 "Invalid" 5424 "Invalid" 5423 "Invalid" 5422 "Invalid" 5421 "Invalid" 5420 "Invalid" 5419 "Invalid" 5418 "Invalid" 5417 "Invalid" 5416 "Invalid" 5415 "Invalid" 5414 "Invalid" 5413 "Invalid" 5412 "Invalid" 5411 "Invalid" 5410 "Invalid" 5409 "Invalid" 5408 "Invalid" 5407 "Invalid" 5406 "Invalid" 5405 "Invalid" 5404 "Invalid" 5403 "Invalid" 5402 "Invalid" 5401 "Invalid" 5400 "Invalid" 5399 "Invalid" 5398 "Invalid" 5397 "Invalid" 5396 "Invalid" 5395 "Invalid" 5394 "Invalid" 5393 "Invalid" 5392 "Invalid" 5391 "Invalid" 5390 "Invalid" 5389 "Invalid" 5388 "Invalid" 5387 "Invalid" 5386 "Invalid" 5385 "Invalid" 5384 "Invalid" 5383 "Invalid" 5382 "Invalid" 5381 "Invalid" 5380 "Invalid" 5379 "Invalid" 5378 "Invalid" 5377 "Invalid" 5376 "Invalid" 5375 "Invalid" 5374 "Invalid" 5373 "Invalid" 5372 "Invalid" 5371 "Invalid" 5370 "Invalid" 5369 "Invalid" 5368 "Invalid" 5367 "Invalid" 5366 "Invalid" 5365 "Invalid" 5364 "Invalid" 5363 "Invalid" 5362 "Invalid" 5361 "Invalid" 5360 "Invalid" 5359 "Invalid" 5358 "Invalid" 5357 "Invalid" 5356 "Invalid" 5355 "Invalid" 5354 "Invalid" 5353 "Invalid" 5352 "Invalid" 5351 "Invalid" 5350 "Invalid" 5349 "Invalid" 5348 "Invalid" 5347 "Invalid" 5346 "Invalid" 5345 "Invalid" 5344 "Invalid" 5343 "Invalid" 5342 "Invalid" 5341 "Invalid" 5340 "Invalid" 5339 "Invalid" 5338 "Invalid" 5337 "Invalid" 5336 "Invalid" 5335 "Invalid" ;
VAL_ 642 HU_UnitOfDispdVhclSpd 1 "M/h" 0 "km/h" ;
VAL_ 642 HU_DispFltSts 1 "Error" 0 "No Error" ;
VAL_ 642 HU_BSD_LCASet 3 "Not used" 2 "Reserved" 1 "Off" 0 "On" ;
VAL_ 642 HU_UPASet 3 "Not used" 2 "Reserved" 1 "Off" 0 "On" ;
VAL_ 642 HU_APASlotTypSelt 3 "Reserved" 2 "Cross Button Press" 1 "Parallel Button Press" 0 "No Button Press" ;
VAL_ 642 HU_APAEnable 3 "Not used" 2 "Reserved" 1 "Enabled" 0 "Disenabled" ;
VAL_ 642 HU_FCWSet 3 "Not used" 2 "Reserved" 1 "Off" 0 "On" ;
VAL_ 642 HU_RCTASet 3 "Not used" 2 "Reserved" 1 "Off" 0 "On" ;
VAL_ 642 HU_DOWSet 3 "Not used" 2 "Reserved" 1 "Off" 0 "On" ;
VAL_ 642 ALM_RRDoorLEDFltFb 1 "Fault" 0 "Not Fault" ;
VAL_ 642 ALM_FRDoorLEDFltFb 1 "Fault" 0 "Not Fault" ;
VAL_ 642 ALM_RLDoorLEDFltFb 1 "Fault" 0 "Not Fault" ;
VAL_ 642 ALM_FLDoorLEDFltFb 1 "Fault" 0 "Not Fault" ;
VAL_ 642 HU_AEBSet 3 "Not used" 2 "Reserved" 1 "Off" 0 "On" ;
VAL_ 645 HU_AMP_MuteSet 3 "Not used" 2 "Reserved" 1 "All speakers unmute" 0 "All speakers mute" ;
VAL_ 645 HU_AMP_VhclAlrmVolStepSet 7 "Invalid" 6 "Invalid" 5 "Invalid" 4 "Level 5" 3 "Level 4" 2 "Level 3" 1 "Level 2" 0 "Level 1" ;
VAL_ 645 HU_AMP_VSCModSeln 3 "Speed gain high mode" 2 "Speed gain middle mode" 1 "Speed gain low mode" 0 "Speed gain mode Off" ;
VAL_ 645 HU_AMP_LondnessSwch 3 "Not used" 2 "Reserved" 1 "Londness on" 0 "Londness off" ;
VAL_ 645 HU_AMP_MainVolStepSet 15 "15" 14 "14" 13 "13" 12 "12" 11 "11" 10 "10" 9 "9" 8 "8" 7 "7" 6 "6" 5 "5" 4 "4" 3 "3" 2 "2" 1 "1" 0 "0" ;
VAL_ 645 HU_AMP_AudSrcInform 15 "Reserved" 14 "Reserved" 13 "Reserved" 12 "Reserved" 11 "Reserved" 10 "Reserved" 9 "Reserved" 8 "Reserved" 7 "Reserved" 6 "Reserved" 5 "Reserved" 4 "Reserved" 3 "VR" 2 "Call(BT Call, E-Call, Ring)" 1 "Multi Media(left)" 0 "Off" ;
VAL_ 645 HU_AMP_NaviVolStepSet 15 "15" 14 "14" 13 "13" 12 "12" 11 "11" 10 "10" 9 "9" 8 "8" 7 "7" 6 "6" 5 "5" 4 "4" 3 "3" 2 "2" 1 "1" 0 "0" ;
VAL_ 645 HU_AMP_ESSModSelt 3 "Reserved" 2 "ESS mode3" 1 "ESS mode2" 0 "ESS mode1" ;
VAL_ 645 HU_AMP_Navi_VRModSet 3 "Reserved" 2 "System Sound" 1 "NAVI ON" 0 "Off" ;
VAL_ 645 HU_AMP_IntConctVolStepSet 15 "15" 14 "14" 13 "13" 12 "12" 11 "11" 10 "10" 9 "9" 8 "8" 7 "7" 6 "6" 5 "5" 4 "4" 3 "3" 2 "2" 1 "1" 0 "0" ;
VAL_ 645 HU_AMP_CallVolStepSet 15 "15" 14 "14" 13 "13" 12 "12" 11 "11" 10 "10" 9 "9" 8 "8" 7 "7" 6 "6" 5 "5" 4 "4" 3 "3" 2 "2" 1 "1" 0 "0" ;
VAL_ 645 HU_AMP_OutputCH_RR 3 "Not used" 2 "Reserved" 1 "On" 0 "Off" ;
VAL_ 645 HU_AMP_OutputCH_LR 3 "Not used" 2 "Reserved" 1 "On" 0 "Off" ;
VAL_ 645 HU_AMP_OutputCH_RF 3 "Not used" 2 "Reserved" 1 "On" 0 "Off" ;
VAL_ 645 HU_AMP_OutputCH_LF 3 "Not used" 2 "Reserved" 1 "On" 0 "Off" ;
VAL_ 645 HU_AMP_ESSSwch 3 "Not used" 2 "Reserved" 1 "Off" 0 "On" ;
VAL_ 645 HU_AMP_LeRiAudBalnSet 31 "Invalid" 30 "Invalid" 29 "Invalid" 28 "Invalid" 27 "Invalid" 26 "Invalid" 25 "Invalid" 24 "Invalid" 23 "Invalid" 22 "Invalid" 21 "Invalid" 20 "Invalid" 19 "Invalid" 18 "9" 17 "8" 16 "7" 15 "6" 14 "5" 13 "4" 12 "3" 11 "2" 10 "1" 9 "0" 8 "-1" 7 "-2" 6 "-3" 5 "-4" 4 "-5" 3 "-6" 2 "-7" 1 "-8" 0 "-9" ;
VAL_ 645 HU_AMP_FrntReAudBalnSet 31 "Invalid" 30 "Invalid" 29 "Invalid" 28 "Invalid" 27 "Invalid" 26 "Invalid" 25 "Invalid" 24 "Invalid" 23 "Invalid" 22 "Invalid" 21 "Invalid" 20 "Invalid" 19 "Invalid" 18 "9" 17 "8" 16 "7" 15 "6" 14 "5" 13 "4" 12 "3" 11 "2" 10 "1" 9 "0" 8 "-1" 7 "-2" 6 "-3" 5 "-4" 4 "-5" 3 "-6" 2 "-7" 1 "-8" 0 "-9" ;
VAL_ 646 HU_AMP_EQ3Set 31 "Invalid" 30 "Invalid" 29 "Invalid" 28 "Invalid" 27 "Invalid" 26 "Invalid" 25 "Invalid" 24 "Invalid" 23 "Invalid" 22 "Invalid" 21 "Invalid" 20 "Invalid" 19 "Invalid" 18 "9" 17 "8" 16 "7" 15 "6" 14 "5" 13 "4" 12 "3" 11 "2" 10 "1" 9 "0" 8 "-1" 7 "-2" 6 "-3" 5 "-4" 4 "-5" 3 "-6" 2 "-7" 1 "-8" 0 "-9" ;
VAL_ 646 HU_AMP_EQ2Set 31 "Invalid" 30 "Invalid" 29 "Invalid" 28 "Invalid" 27 "Invalid" 26 "Invalid" 25 "Invalid" 24 "Invalid" 23 "Invalid" 22 "Invalid" 21 "Invalid" 20 "Invalid" 19 "Invalid" 18 "9" 17 "8" 16 "7" 15 "6" 14 "5" 13 "4" 12 "3" 11 "2" 10 "1" 9 "0" 8 "-1" 7 "-2" 6 "-3" 5 "-4" 4 "-5" 3 "-6" 2 "-7" 1 "-8" 0 "-9" ;
VAL_ 646 HU_AMP_EQ5Set 31 "Invalid" 30 "Invalid" 29 "Invalid" 28 "Invalid" 27 "Invalid" 26 "Invalid" 25 "Invalid" 24 "Invalid" 23 "Invalid" 22 "Invalid" 21 "Invalid" 20 "Invalid" 19 "Invalid" 18 "9" 17 "8" 16 "7" 15 "6" 14 "5" 13 "4" 12 "3" 11 "2" 10 "1" 9 "0" 8 "-1" 7 "-2" 6 "-3" 5 "-4" 4 "-5" 3 "-6" 2 "-7" 1 "-8" 0 "-9" ;
VAL_ 646 HU_AMP_EQ4Set 31 "Invalid" 30 "Invalid" 29 "Invalid" 28 "Invalid" 27 "Invalid" 26 "Invalid" 25 "Invalid" 24 "Invalid" 23 "Invalid" 22 "Invalid" 21 "Invalid" 20 "Invalid" 19 "Invalid" 18 "9" 17 "8" 16 "7" 15 "6" 14 "5" 13 "4" 12 "3" 11 "2" 10 "1" 9 "0" 8 "-1" 7 "-2" 6 "-3" 5 "-4" 4 "-5" 3 "-6" 2 "-7" 1 "-8" 0 "-9" ;
VAL_ 646 HU_AMP_EQRst 3 "Not used" 2 "Reserved" 1 "Reset" 0 "No Request" ;
VAL_ 646 HU_AMP_EQ1Set 31 "Invalid" 30 "Invalid" 29 "Invalid" 28 "Invalid" 27 "Invalid" 26 "Invalid" 25 "Invalid" 24 "Invalid" 23 "Invalid" 22 "Invalid" 21 "Invalid" 20 "Invalid" 19 "Invalid" 18 "9" 17 "8" 16 "7" 15 "6" 14 "5" 13 "4" 12 "3" 11 "2" 10 "1" 9 "0" 8 "-1" 7 "-2" 6 "-3" 5 "-4" 4 "-5" 3 "-6" 2 "-7" 1 "-8" 0 "-9" ;
VAL_ 646 HU_AMP_EQModSelt 7 "Invalid" 6 "自定义" 5 "打击" 4 "爵士" 3 "流行" 2 "古典" 1 "摇滚" 0 "标准" ;
VAL_ 649 HU_LocTiMth 15 "Invalid" 14 "Invalid" 13 "Invalid" 0 "Invalid" ;
VAL_ 649 HU_LocTiD 0 "Invalid" ;
VAL_ 649 HU_LocTiHr 31 "Invalid" 30 "Invalid" 29 "Invalid" 28 "Invalid" 27 "Invalid" 26 "Invalid" 25 "Invalid" 24 "Invalid" ;
VAL_ 649 HU_LocTiM 63 "Invalid" 62 "Invalid" 61 "Invalid" ;
VAL_ 649 HU_LocTiS 63 "Invalid" 62 "Invalid" 61 "Invalid" ;
VAL_ 649 HU_LocTiVld 1 "Validity" 0 "Invalidity" ;
VAL_ 1394 HU_NMCodtrSleepBit 1 "Synch Shutdwn Req by codtr" 0 "Synch Shutdwn NotReq by codtr" ;
VAL_ 1394 HU_AWB 1 "Active wakeup" 0 "Passive wakeup" ;
VAL_ 1394 HU_PNI 1 "Contain PNI" 0 "Contain no PNI" ;
VAL_ 1394 HU_RptMsgStsDir 1 "On Repeat message State" 0 "Not on Repeat message State" ;
VAL_ 1394 HU_OTAActvnReqToBody 1 "Request" 0 "No Request" ;
VAL_ 1394 HU_OTAActvnReqToADAS 1 "Request" 0 "No Request" ;
VAL_ 1394 HU_OTAActvnReqToChassis 1 "Request" 0 "No Request" ;
VAL_ 1394 HU_OTAActvnReqToPT 1 "Request" 0 "No Request" ;
VAL_ 1394 HU_RMR 1 "Rpt Msg state req" 0 "Rpt Msg state not req" ;
VAL_ 896 AMP_HU_PwrSt 3 "Not used" 2 "Reserved" 1 "On" 0 "Off" ;
VAL_ 624 PAS_RLCDst 15 "Invalid" 14 "Invalid" 13 "Invalid" 12 "Invalid" 11 "Invalid" 10 "Invalid" 9 "Invalid" 8 "Invalid" 7 "Invalid" 6 "Invalid" 5 "Invalid" 4 "Invalid" 3 "Invalid" 2 "Dst range of RLC is from 30cm to 60cm" 1 "Dst of RLC is less than 30cm" 0 "No Obstcl Detected" ;
VAL_ 624 PAS_RLMDst 15 "Reserved" 14 "Reserved" 13 "Reserved" 12 "Reserved" 11 "Reserved" 10 "Reserved" 9 "Reserved" 8 "Reserved" 7 "Reserved" 6 "Reserved" 5 "Reserved" 4 "Reserved" 3 "Dst range of RLM is from 80cm to 150cm" 2 "Dst range of RLM is from 30cm to 80cm" 1 "Dst of RLM is less than 30cm" 0 "No Obstcl Detected" ;
VAL_ 624 PAS_RRCDst 15 "Invalid" 14 "Invalid" 13 "Invalid" 12 "Invalid" 11 "Invalid" 10 "Invalid" 9 "Invalid" 8 "Invalid" 7 "Invalid" 6 "Invalid" 5 "Invalid" 4 "Invalid" 3 "Invalid" 2 "Dst range of RRC is from 30cm to 60cm" 1 "Dst of RRC is less than 30cm" 0 "No Obstcl Detected" ;
VAL_ 624 PAS_RRMDst 15 "Reserved" 14 "Reserved" 13 "Reserved" 12 "Reserved" 11 "Reserved" 10 "Reserved" 9 "Reserved" 8 "Reserved" 7 "Reserved" 6 "Reserved" 5 "Reserved" 4 "Reserved" 3 "Dst range of RRM is from 80cm to 150cm" 2 "Dst range of RRM is from 30cm to 80cm" 1 "Dst of RRM is less than 30cm" 0 "No Obstcl Detected" ;
VAL_ 624 PAS_ReNearestDst 255 "Invalid" 254 "Invalid" 253 "Invalid" 252 "Invalid" 251 "Invalid" ;
VAL_ 624 PAS_Mod 7 "Reserved" 6 "Reserved" 5 "System Failure" 4 "Rear Active" 3 "Front Active" 2 "Front Rear Active" 1 "Standby" 0 "Off" ;
VAL_ 624 PAS_SysFltFlg 3 "System Failure" 2 "Rear Failure" 1 "Front Failure" 0 "No Failure" ;
VAL_ 624 PAS_WarnIdn 3 "Error Warning(1500Hz)" 2 "Rear Corner(750Hz)" 1 "Front Corner(940Hz)" 0 "No Waring" ;
VAL_ 624 PAS_WarnTyp 15 "Reserved" 14 "Reserved" 13 "Reserved" 12 "Reserved" 11 "Reserved" 10 "Reserved" 9 "Reserved" 8 "Reserved" 7 "系统无错误提示(鸣叫0.5s)(预留)" 6 "错误3s报警(长鸣3s)" 5 "长鸣区前后同时报警（前角报警0.5s，后角报警0.5s）" 4 "间歇音3报警（预留）" 3 "间歇音2报警（报警75ms，不报警425ms）" 2 "间歇音1报警（报警75ms，不报警175ms）" 1 "长鸣区报警" 0 "不报警" ;
VAL_ 624 PAS_FLCDst 15 "Invalid" 14 "Invalid" 13 "Invalid" 12 "Invalid" 11 "Invalid" 10 "Invalid" 9 "Invalid" 8 "Invalid" 7 "Invalid" 6 "Invalid" 5 "Invalid" 4 "Invalid" 3 "Invalid" 2 "Dst range of FLC is from 30cm to 60cm" 1 "Dst of FLC is less than 30cm" 0 "No Obstcl Detected" ;
VAL_ 624 PAS_FLMDst 15 "Reserved" 14 "Reserved" 13 "Reserved" 12 "Reserved" 11 "Reserved" 10 "Reserved" 9 "Reserved" 8 "Reserved" 7 "Reserved" 6 "Reserved" 5 "Reserved" 4 "Reserved" 3 "Dst range of FLM is from 80cm to 100cm" 2 "Dst range of FLM is from 30cm to 80cm" 1 "Dst of FLM is less than 30cm" 0 "No Obstcl Detected" ;
VAL_ 624 PAS_FRCDst 15 "Invalid" 14 "Invalid" 13 "Invalid" 12 "Invalid" 11 "Invalid" 10 "Invalid" 9 "Invalid" 8 "Invalid" 7 "Invalid" 6 "Invalid" 5 "Invalid" 4 "Invalid" 3 "Invalid" 2 "Dst range of FRC is from 30cm to60cm" 1 "Dst of FRC is less than 30cm" 0 "No Obstcl Detected" ;
VAL_ 624 PAS_FRMDst 15 "Reserved" 14 "Reserved" 13 "Reserved" 12 "Reserved" 11 "Reserved" 10 "Reserved" 9 "Reserved" 8 "Reserved" 7 "Reserved" 6 "Reserved" 5 "Reserved" 4 "Reserved" 3 "Dst range of FRM is from 80cm to 100cm" 2 "Dst range of FRM is from 30cm to 80cm" 1 "Dst of FRM is less than 30cm" 0 "No Obstcl Detected" ;
VAL_ 285 VCU_VhclResidualMile 1023 "Invalid" 1022 "Invalid" 1021 "Invalid" 1020 "Invalid" 1019 "Invalid" 1018 "Invalid" 1017 "Invalid" 1016 "Invalid" 1015 "Invalid" 1014 "Invalid" 1013 "Invalid" 1012 "Invalid" 1011 "Invalid" 1010 "Invalid" 1009 "Invalid" 1008 "Invalid" 1007 "Invalid" 1006 "Invalid" 1005 "Invalid" 1004 "Invalid" 1003 "Invalid" 1002 "Invalid" 1001 "Invalid" 1000 "Invalid" 999 "Invalid" 998 "Invalid" 997 "Invalid" 996 "Invalid" 995 "Invalid" 994 "Invalid" 993 "Invalid" 992 "Invalid" 991 "Invalid" 990 "Invalid" 989 "Invalid" 988 "Invalid" 987 "Invalid" 986 "Invalid" 985 "Invalid" 984 "Invalid" 983 "Invalid" 982 "Invalid" 981 "Invalid" 980 "Invalid" 979 "Invalid" 978 "Invalid" 977 "Invalid" 976 "Invalid" 975 "Invalid" 974 "Invalid" 973 "Invalid" 972 "Invalid" 971 "Invalid" 970 "Invalid" 969 "Invalid" 968 "Invalid" 967 "Invalid" 966 "Invalid" 965 "Invalid" 964 "Invalid" 963 "Invalid" 962 "Invalid" 961 "Invalid" 960 "Invalid" 959 "Invalid" 958 "Invalid" 957 "Invalid" 956 "Invalid" 955 "Invalid" 954 "Invalid" 953 "Invalid" 952 "Invalid" 951 "Invalid" 950 "Invalid" 949 "Invalid" 948 "Invalid" 947 "Invalid" 946 "Invalid" 945 "Invalid" 944 "Invalid" 943 "Invalid" 942 "Invalid" 941 "Invalid" 940 "Invalid" 939 "Invalid" 938 "Invalid" 937 "Invalid" 936 "Invalid" 935 "Invalid" 934 "Invalid" 933 "Invalid" 932 "Invalid" 931 "Invalid" 930 "Invalid" 929 "Invalid" 928 "Invalid" 927 "Invalid" 926 "Invalid" 925 "Invalid" 924 "Invalid" 923 "Invalid" 922 "Invalid" 921 "Invalid" 920 "Invalid" 919 "Invalid" 918 "Invalid" 917 "Invalid" 916 "Invalid" 915 "Invalid" 914 "Invalid" 913 "Invalid" 912 "Invalid" 911 "Invalid" 910 "Invalid" 909 "Invalid" 908 "Invalid" 907 "Invalid" 906 "Invalid" 905 "Invalid" 904 "Invalid" 903 "Invalid" 902 "Invalid" 901 "Invalid" 900 "Invalid" 899 "Invalid" 898 "Invalid" 897 "Invalid" 896 "Invalid" 895 "Invalid" 894 "Invalid" 893 "Invalid" 892 "Invalid" 891 "Invalid" 890 "Invalid" 889 "Invalid" 888 "Invalid" 887 "Invalid" 886 "Invalid" 885 "Invalid" 884 "Invalid" 883 "Invalid" 882 "Invalid" 881 "Invalid" 880 "Invalid" 879 "Invalid" 878 "Invalid" 877 "Invalid" 876 "Invalid" 875 "Invalid" 874 "Invalid" 873 "Invalid" 872 "Invalid" 871 "Invalid" 870 "Invalid" 869 "Invalid" 868 "Invalid" 867 "Invalid" 866 "Invalid" 865 "Invalid" 864 "Invalid" 863 "Invalid" 862 "Invalid" 861 "Invalid" 860 "Invalid" 859 "Invalid" 858 "Invalid" 857 "Invalid" 856 "Invalid" 855 "Invalid" 854 "Invalid" 853 "Invalid" 852 "Invalid" 851 "Invalid" 850 "Invalid" 849 "Invalid" 848 "Invalid" 847 "Invalid" 846 "Invalid" 845 "Invalid" 844 "Invalid" 843 "Invalid" 842 "Invalid" 841 "Invalid" 840 "Invalid" 839 "Invalid" 838 "Invalid" 837 "Invalid" 836 "Invalid" 835 "Invalid" 834 "Invalid" 833 "Invalid" 832 "Invalid" 831 "Invalid" 830 "Invalid" 829 "Invalid" 828 "Invalid" 827 "Invalid" 826 "Invalid" 825 "Invalid" 824 "Invalid" 823 "Invalid" 822 "Invalid" 821 "Invalid" 820 "Invalid" 819 "Invalid" 818 "Invalid" 817 "Invalid" 816 "Invalid" 815 "Invalid" 814 "Invalid" 813 "Invalid" 812 "Invalid" 811 "Invalid" 810 "Invalid" 809 "Invalid" 808 "Invalid" 807 "Invalid" 806 "Invalid" 805 "Invalid" 804 "Invalid" 803 "Invalid" 802 "Invalid" 801 "Invalid" ;
VAL_ 285 VCU_PwrFlowIndcr 7 "Reserved" 6 "Reserved" 5 "Reserved" 4 "Regener Power Flow" 3 "Driving Power Flow" 2 "Chrge Finished Power Flow" 1 "Charging Power Flow" 0 "No Power Flow" ;
VAL_ 285 VCU_BattLoTmpHeatgSts 1 "True" 0 "False" ;
VAL_ 285 VCU_VhclCreepSts 1 "Creep Off" 0 "Creep On" ;
VAL_ 285 VCU_DispSoc 127 "Invalid" 126 "Invalid" 125 "Invalid" 124 "Invalid" 123 "Invalid" 122 "Invalid" 121 "Invalid" 120 "Invalid" 119 "Invalid" 118 "Invalid" 117 "Invalid" 116 "Invalid" 115 "Invalid" 114 "Invalid" 113 "Invalid" 112 "Invalid" 111 "Invalid" 110 "Invalid" 109 "Invalid" 108 "Invalid" 107 "Invalid" 106 "Invalid" 105 "Invalid" 104 "Invalid" 103 "Invalid" 102 "Invalid" 101 "Invalid" ;
VAL_ 285 VCU_EgyCnsPer100km 511 "Invalid" 510 "Invalid" 509 "Invalid" 508 "Invalid" 507 "Invalid" 506 "Invalid" 505 "Invalid" 504 "Invalid" 503 "Invalid" 502 "Invalid" 501 "Invalid" 500 "Invalid" 499 "Invalid" 498 "Invalid" 497 "Invalid" 496 "Invalid" 495 "Invalid" 494 "Invalid" 493 "Invalid" 492 "Invalid" 491 "Invalid" 490 "Invalid" 489 "Invalid" 488 "Invalid" 487 "Invalid" 486 "Invalid" 485 "Invalid" 484 "Invalid" 483 "Invalid" 482 "Invalid" 481 "Invalid" 480 "Invalid" 479 "Invalid" 478 "Invalid" 477 "Invalid" 476 "Invalid" 475 "Invalid" 474 "Invalid" 473 "Invalid" 472 "Invalid" 471 "Invalid" 470 "Invalid" 469 "Invalid" 468 "Invalid" 467 "Invalid" 466 "Invalid" 465 "Invalid" 464 "Invalid" 463 "Invalid" 462 "Invalid" 461 "Invalid" 460 "Invalid" 459 "Invalid" 458 "Invalid" 457 "Invalid" 456 "Invalid" 455 "Invalid" 454 "Invalid" 453 "Invalid" 452 "Invalid" 451 "Invalid" 450 "Invalid" 449 "Invalid" 448 "Invalid" 447 "Invalid" 446 "Invalid" 445 "Invalid" 444 "Invalid" 443 "Invalid" 442 "Invalid" 441 "Invalid" 440 "Invalid" 439 "Invalid" 438 "Invalid" 437 "Invalid" 436 "Invalid" 435 "Invalid" 434 "Invalid" 433 "Invalid" 432 "Invalid" 431 "Invalid" 430 "Invalid" 429 "Invalid" 428 "Invalid" 427 "Invalid" 426 "Invalid" 425 "Invalid" 424 "Invalid" 423 "Invalid" 422 "Invalid" 421 "Invalid" 420 "Invalid" 419 "Invalid" 418 "Invalid" 417 "Invalid" 416 "Invalid" 415 "Invalid" 414 "Invalid" 413 "Invalid" 412 "Invalid" 411 "Invalid" 410 "Invalid" 409 "Invalid" 408 "Invalid" 407 "Invalid" 406 "Invalid" 405 "Invalid" 404 "Invalid" 403 "Invalid" 402 "Invalid" 401 "Invalid" 400 "Invalid" 399 "Invalid" 398 "Invalid" 397 "Invalid" 396 "Invalid" 395 "Invalid" 394 "Invalid" 393 "Invalid" 392 "Invalid" 391 "Invalid" 390 "Invalid" 389 "Invalid" 388 "Invalid" 387 "Invalid" 386 "Invalid" 385 "Invalid" 384 "Invalid" 383 "Invalid" 382 "Invalid" 381 "Invalid" 380 "Invalid" 379 "Invalid" 378 "Invalid" 377 "Invalid" 376 "Invalid" 375 "Invalid" 374 "Invalid" 373 "Invalid" 372 "Invalid" 371 "Invalid" 370 "Invalid" 369 "Invalid" 368 "Invalid" 367 "Invalid" 366 "Invalid" 365 "Invalid" 364 "Invalid" 363 "Invalid" 362 "Invalid" 361 "Invalid" 360 "Invalid" 359 "Invalid" 358 "Invalid" 357 "Invalid" 356 "Invalid" 355 "Invalid" 354 "Invalid" 353 "Invalid" 352 "Invalid" 351 "Invalid" 350 "Invalid" 349 "Invalid" 348 "Invalid" 347 "Invalid" 346 "Invalid" 345 "Invalid" 344 "Invalid" 343 "Invalid" 342 "Invalid" 341 "Invalid" 340 "Invalid" 339 "Invalid" 338 "Invalid" 337 "Invalid" 336 "Invalid" 335 "Invalid" 334 "Invalid" 333 "Invalid" 332 "Invalid" 331 "Invalid" 330 "Invalid" 329 "Invalid" 328 "Invalid" 327 "Invalid" 326 "Invalid" 325 "Invalid" 324 "Invalid" 323 "Invalid" 322 "Invalid" 321 "Invalid" 320 "Invalid" 319 "Invalid" 318 "Invalid" 317 "Invalid" 316 "Invalid" 315 "Invalid" 314 "Invalid" 313 "Invalid" 312 "Invalid" 311 "Invalid" 310 "Invalid" 309 "Invalid" 308 "Invalid" 307 "Invalid" 306 "Invalid" 305 "Invalid" 304 "Invalid" 303 "Invalid" 302 "Invalid" 301 "Invalid" ;
VAL_ 371 CDU_OBCACVlt 511 "Invalid" 510 "Invalid" 509 "Invalid" 508 "Invalid" 507 "Invalid" 506 "Invalid" 505 "Invalid" 504 "Invalid" 503 "Invalid" 502 "Invalid" 501 "Invalid" ;
VAL_ 371 CDU_OBCACCur 255 "Invalid" 254 "Invalid" 253 "Invalid" ;
VAL_ 529 BCU_BattVlt 8191 "Invalid" 8190 "Invalid" 8189 "Invalid" 8188 "Invalid" 8187 "Invalid" 8186 "Invalid" 8185 "Invalid" 8184 "Invalid" 8183 "Invalid" 8182 "Invalid" 8181 "Invalid" 8180 "Invalid" 8179 "Invalid" 8178 "Invalid" 8177 "Invalid" 8176 "Invalid" 8175 "Invalid" 8174 "Invalid" 8173 "Invalid" 8172 "Invalid" 8171 "Invalid" 8170 "Invalid" 8169 "Invalid" 8168 "Invalid" 8167 "Invalid" 8166 "Invalid" 8165 "Invalid" 8164 "Invalid" 8163 "Invalid" 8162 "Invalid" 8161 "Invalid" 8160 "Invalid" 8159 "Invalid" 8158 "Invalid" 8157 "Invalid" 8156 "Invalid" 8155 "Invalid" 8154 "Invalid" 8153 "Invalid" 8152 "Invalid" 8151 "Invalid" 8150 "Invalid" 8149 "Invalid" 8148 "Invalid" 8147 "Invalid" 8146 "Invalid" 8145 "Invalid" 8144 "Invalid" 8143 "Invalid" 8142 "Invalid" 8141 "Invalid" 8140 "Invalid" 8139 "Invalid" 8138 "Invalid" 8137 "Invalid" 8136 "Invalid" 8135 "Invalid" 8134 "Invalid" 8133 "Invalid" 8132 "Invalid" 8131 "Invalid" 8130 "Invalid" 8129 "Invalid" 8128 "Invalid" 8127 "Invalid" 8126 "Invalid" 8125 "Invalid" 8124 "Invalid" 8123 "Invalid" 8122 "Invalid" 8121 "Invalid" 8120 "Invalid" 8119 "Invalid" 8118 "Invalid" 8117 "Invalid" 8116 "Invalid" 8115 "Invalid" 8114 "Invalid" 8113 "Invalid" 8112 "Invalid" 8111 "Invalid" 8110 "Invalid" 8109 "Invalid" 8108 "Invalid" 8107 "Invalid" 8106 "Invalid" 8105 "Invalid" 8104 "Invalid" 8103 "Invalid" 8102 "Invalid" 8101 "Invalid" 8100 "Invalid" 8099 "Invalid" 8098 "Invalid" 8097 "Invalid" 8096 "Invalid" 8095 "Invalid" 8094 "Invalid" 8093 "Invalid" 8092 "Invalid" 8091 "Invalid" 8090 "Invalid" 8089 "Invalid" 8088 "Invalid" 8087 "Invalid" 8086 "Invalid" 8085 "Invalid" 8084 "Invalid" 8083 "Invalid" 8082 "Invalid" 8081 "Invalid" 8080 "Invalid" 8079 "Invalid" 8078 "Invalid" 8077 "Invalid" 8076 "Invalid" 8075 "Invalid" 8074 "Invalid" 8073 "Invalid" 8072 "Invalid" 8071 "Invalid" 8070 "Invalid" 8069 "Invalid" 8068 "Invalid" 8067 "Invalid" 8066 "Invalid" 8065 "Invalid" 8064 "Invalid" 8063 "Invalid" 8062 "Invalid" 8061 "Invalid" 8060 "Invalid" 8059 "Invalid" 8058 "Invalid" 8057 "Invalid" 8056 "Invalid" 8055 "Invalid" 8054 "Invalid" 8053 "Invalid" 8052 "Invalid" 8051 "Invalid" 8050 "Invalid" 8049 "Invalid" 8048 "Invalid" 8047 "Invalid" 8046 "Invalid" 8045 "Invalid" 8044 "Invalid" 8043 "Invalid" 8042 "Invalid" 8041 "Invalid" 8040 "Invalid" 8039 "Invalid" 8038 "Invalid" 8037 "Invalid" 8036 "Invalid" 8035 "Invalid" 8034 "Invalid" 8033 "Invalid" 8032 "Invalid" 8031 "Invalid" 8030 "Invalid" 8029 "Invalid" 8028 "Invalid" 8027 "Invalid" 8026 "Invalid" 8025 "Invalid" 8024 "Invalid" 8023 "Invalid" 8022 "Invalid" 8021 "Invalid" 8020 "Invalid" 8019 "Invalid" 8018 "Invalid" 8017 "Invalid" 8016 "Invalid" 8015 "Invalid" 8014 "Invalid" 8013 "Invalid" 8012 "Invalid" 8011 "Invalid" 8010 "Invalid" 8009 "Invalid" 8008 "Invalid" 8007 "Invalid" 8006 "Invalid" 8005 "Invalid" 8004 "Invalid" 8003 "Invalid" 8002 "Invalid" 8001 "Invalid" 8000 "Invalid" 7999 "Invalid" 7998 "Invalid" 7997 "Invalid" 7996 "Invalid" 7995 "Invalid" 7994 "Invalid" 7993 "Invalid" 7992 "Invalid" 7991 "Invalid" 7990 "Invalid" 7989 "Invalid" 7988 "Invalid" 7987 "Invalid" 7986 "Invalid" 7985 "Invalid" 7984 "Invalid" 7983 "Invalid" 7982 "Invalid" 7981 "Invalid" 7980 "Invalid" 7979 "Invalid" 7978 "Invalid" 7977 "Invalid" 7976 "Invalid" 7975 "Invalid" 7974 "Invalid" 7973 "Invalid" 7972 "Invalid" 7971 "Invalid" 7970 "Invalid" 7969 "Invalid" 7968 "Invalid" 7967 "Invalid" 7966 "Invalid" 7965 "Invalid" 7964 "Invalid" 7963 "Invalid" 7962 "Invalid" 7961 "Invalid" 7960 "Invalid" 7959 "Invalid" 7958 "Invalid" 7957 "Invalid" 7956 "Invalid" 7955 "Invalid" 7954 "Invalid" 7953 "Invalid" 7952 "Invalid" 7951 "Invalid" 7950 "Invalid" 7949 "Invalid" 7948 "Invalid" 7947 "Invalid" 7946 "Invalid" 7945 "Invalid" 7944 "Invalid" 7943 "Invalid" 7942 "Invalid" 7941 "Invalid" 7940 "Invalid" 7939 "Invalid" 7938 "Invalid" 7937 "Invalid" 7936 "Invalid" 7935 "Invalid" 7934 "Invalid" 7933 "Invalid" 7932 "Invalid" 7931 "Invalid" 7930 "Invalid" 7929 "Invalid" 7928 "Invalid" 7927 "Invalid" 7926 "Invalid" 7925 "Invalid" 7924 "Invalid" 7923 "Invalid" 7922 "Invalid" 7921 "Invalid" 7920 "Invalid" 7919 "Invalid" 7918 "Invalid" 7917 "Invalid" 7916 "Invalid" 7915 "Invalid" 7914 "Invalid" 7913 "Invalid" 7912 "Invalid" 7911 "Invalid" 7910 "Invalid" 7909 "Invalid" 7908 "Invalid" 7907 "Invalid" 7906 "Invalid" 7905 "Invalid" 7904 "Invalid" 7903 "Invalid" 7902 "Invalid" 7901 "Invalid" 7900 "Invalid" 7899 "Invalid" 7898 "Invalid" 7897 "Invalid" 7896 "Invalid" 7895 "Invalid" 7894 "Invalid" 7893 "Invalid" 7892 "Invalid" 7891 "Invalid" 7890 "Invalid" 7889 "Invalid" 7888 "Invalid" 7887 "Invalid" 7886 "Invalid" 7885 "Invalid" 7884 "Invalid" 7883 "Invalid" 7882 "Invalid" 7881 "Invalid" 7880 "Invalid" 7879 "Invalid" 7878 "Invalid" 7877 "Invalid" 7876 "Invalid" 7875 "Invalid" 7874 "Invalid" 7873 "Invalid" 7872 "Invalid" 7871 "Invalid" 7870 "Invalid" 7869 "Invalid" 7868 "Invalid" 7867 "Invalid" 7866 "Invalid" 7865 "Invalid" 7864 "Invalid" 7863 "Invalid" 7862 "Invalid" 7861 "Invalid" 7860 "Invalid" 7859 "Invalid" 7858 "Invalid" 7857 "Invalid" 7856 "Invalid" 7855 "Invalid" 7854 "Invalid" 7853 "Invalid" 7852 "Invalid" 7851 "Invalid" 7850 "Invalid" 7849 "Invalid" 7848 "Invalid" 7847 "Invalid" 7846 "Invalid" 7845 "Invalid" 7844 "Invalid" 7843 "Invalid" 7842 "Invalid" 7841 "Invalid" 7840 "Invalid" 7839 "Invalid" 7838 "Invalid" 7837 "Invalid" 7836 "Invalid" 7835 "Invalid" 7834 "Invalid" 7833 "Invalid" 7832 "Invalid" 7831 "Invalid" 7830 "Invalid" 7829 "Invalid" 7828 "Invalid" 7827 "Invalid" 7826 "Invalid" 7825 "Invalid" 7824 "Invalid" 7823 "Invalid" 7822 "Invalid" 7821 "Invalid" 7820 "Invalid" 7819 "Invalid" 7818 "Invalid" 7817 "Invalid" 7816 "Invalid" 7815 "Invalid" 7814 "Invalid" 7813 "Invalid" 7812 "Invalid" 7811 "Invalid" 7810 "Invalid" 7809 "Invalid" 7808 "Invalid" 7807 "Invalid" 7806 "Invalid" 7805 "Invalid" 7804 "Invalid" 7803 "Invalid" 7802 "Invalid" 7801 "Invalid" 7800 "Invalid" 7799 "Invalid" 7798 "Invalid" 7797 "Invalid" 7796 "Invalid" 7795 "Invalid" 7794 "Invalid" 7793 "Invalid" 7792 "Invalid" 7791 "Invalid" 7790 "Invalid" 7789 "Invalid" 7788 "Invalid" 7787 "Invalid" 7786 "Invalid" 7785 "Invalid" 7784 "Invalid" 7783 "Invalid" 7782 "Invalid" 7781 "Invalid" 7780 "Invalid" 7779 "Invalid" 7778 "Invalid" 7777 "Invalid" 7776 "Invalid" 7775 "Invalid" 7774 "Invalid" 7773 "Invalid" 7772 "Invalid" 7771 "Invalid" 7770 "Invalid" 7769 "Invalid" 7768 "Invalid" 7767 "Invalid" 7766 "Invalid" 7765 "Invalid" 7764 "Invalid" 7763 "Invalid" 7762 "Invalid" 7761 "Invalid" 7760 "Invalid" 7759 "Invalid" 7758 "Invalid" 7757 "Invalid" 7756 "Invalid" 7755 "Invalid" 7754 "Invalid" 7753 "Invalid" 7752 "Invalid" 7751 "Invalid" 7750 "Invalid" 7749 "Invalid" 7748 "Invalid" 7747 "Invalid" 7746 "Invalid" 7745 "Invalid" 7744 "Invalid" 7743 "Invalid" 7742 "Invalid" 7741 "Invalid" 7740 "Invalid" 7739 "Invalid" 7738 "Invalid" 7737 "Invalid" 7736 "Invalid" 7735 "Invalid" 7734 "Invalid" 7733 "Invalid" 7732 "Invalid" 7731 "Invalid" 7730 "Invalid" 7729 "Invalid" 7728 "Invalid" 7727 "Invalid" 7726 "Invalid" 7725 "Invalid" 7724 "Invalid" 7723 "Invalid" 7722 "Invalid" 7721 "Invalid" 7720 "Invalid" 7719 "Invalid" 7718 "Invalid" 7717 "Invalid" 7716 "Invalid" 7715 "Invalid" 7714 "Invalid" 7713 "Invalid" 7712 "Invalid" 7711 "Invalid" 7710 "Invalid" 7709 "Invalid" 7708 "Invalid" 7707 "Invalid" 7706 "Invalid" 7705 "Invalid" 7704 "Invalid" 7703 "Invalid" 7702 "Invalid" 7701 "Invalid" 7700 "Invalid" 7699 "Invalid" 7698 "Invalid" 7697 "Invalid" 7696 "Invalid" 7695 "Invalid" 7694 "Invalid" 7693 "Invalid" 7692 "Invalid" 7691 "Invalid" 7690 "Invalid" 7689 "Invalid" 7688 "Invalid" 7687 "Invalid" 7686 "Invalid" 7685 "Invalid" 7684 "Invalid" 7683 "Invalid" 7682 "Invalid" 7681 "Invalid" 7680 "Invalid" 7679 "Invalid" 7678 "Invalid" 7677 "Invalid" 7676 "Invalid" 7675 "Invalid" 7674 "Invalid" 7673 "Invalid" 7672 "Invalid" 7671 "Invalid" 7670 "Invalid" 7669 "Invalid" 7668 "Invalid" 7667 "Invalid" 7666 "Invalid" 7665 "Invalid" 7664 "Invalid" 7663 "Invalid" 7662 "Invalid" 7661 "Invalid" 7660 "Invalid" 7659 "Invalid" 7658 "Invalid" 7657 "Invalid" 7656 "Invalid" 7655 "Invalid" 7654 "Invalid" 7653 "Invalid" 7652 "Invalid" 7651 "Invalid" 7650 "Invalid" 7649 "Invalid" 7648 "Invalid" 7647 "Invalid" 7646 "Invalid" 7645 "Invalid" 7644 "Invalid" 7643 "Invalid" 7642 "Invalid" 7641 "Invalid" 7640 "Invalid" 7639 "Invalid" 7638 "Invalid" 7637 "Invalid" 7636 "Invalid" 7635 "Invalid" 7634 "Invalid" 7633 "Invalid" 7632 "Invalid" 7631 "Invalid" 7630 "Invalid" 7629 "Invalid" 7628 "Invalid" 7627 "Invalid" 7626 "Invalid" 7625 "Invalid" 7624 "Invalid" 7623 "Invalid" 7622 "Invalid" 7621 "Invalid" 7620 "Invalid" 7619 "Invalid" 7618 "Invalid" 7617 "Invalid" 7616 "Invalid" 7615 "Invalid" 7614 "Invalid" 7613 "Invalid" 7612 "Invalid" 7611 "Invalid" 7610 "Invalid" 7609 "Invalid" 7608 "Invalid" 7607 "Invalid" 7606 "Invalid" 7605 "Invalid" 7604 "Invalid" 7603 "Invalid" 7602 "Invalid" 7601 "Invalid" 7600 "Invalid" 7599 "Invalid" 7598 "Invalid" 7597 "Invalid" 7596 "Invalid" 7595 "Invalid" 7594 "Invalid" 7593 "Invalid" 7592 "Invalid" 7591 "Invalid" 7590 "Invalid" 7589 "Invalid" 7588 "Invalid" 7587 "Invalid" 7586 "Invalid" 7585 "Invalid" 7584 "Invalid" 7583 "Invalid" 7582 "Invalid" 7581 "Invalid" 7580 "Invalid" 7579 "Invalid" 7578 "Invalid" 7577 "Invalid" 7576 "Invalid" 7575 "Invalid" 7574 "Invalid" 7573 "Invalid" 7572 "Invalid" 7571 "Invalid" 7570 "Invalid" 7569 "Invalid" 7568 "Invalid" 7567 "Invalid" 7566 "Invalid" 7565 "Invalid" 7564 "Invalid" 7563 "Invalid" 7562 "Invalid" 7561 "Invalid" 7560 "Invalid" 7559 "Invalid" 7558 "Invalid" 7557 "Invalid" 7556 "Invalid" 7555 "Invalid" 7554 "Invalid" 7553 "Invalid" 7552 "Invalid" 7551 "Invalid" 7550 "Invalid" 7549 "Invalid" 7548 "Invalid" 7547 "Invalid" 7546 "Invalid" 7545 "Invalid" 7544 "Invalid" 7543 "Invalid" 7542 "Invalid" 7541 "Invalid" 7540 "Invalid" 7539 "Invalid" 7538 "Invalid" 7537 "Invalid" 7536 "Invalid" 7535 "Invalid" 7534 "Invalid" 7533 "Invalid" 7532 "Invalid" 7531 "Invalid" 7530 "Invalid" 7529 "Invalid" 7528 "Invalid" 7527 "Invalid" 7526 "Invalid" 7525 "Invalid" 7524 "Invalid" 7523 "Invalid" 7522 "Invalid" 7521 "Invalid" 7520 "Invalid" 7519 "Invalid" 7518 "Invalid" 7517 "Invalid" 7516 "Invalid" 7515 "Invalid" 7514 "Invalid" 7513 "Invalid" 7512 "Invalid" 7511 "Invalid" 7510 "Invalid" 7509 "Invalid" 7508 "Invalid" 7507 "Invalid" 7506 "Invalid" 7505 "Invalid" 7504 "Invalid" 7503 "Invalid" 7502 "Invalid" 7501 "Invalid" 7500 "Invalid" 7499 "Invalid" 7498 "Invalid" 7497 "Invalid" 7496 "Invalid" 7495 "Invalid" 7494 "Invalid" 7493 "Invalid" 7492 "Invalid" 7491 "Invalid" 7490 "Invalid" 7489 "Invalid" 7488 "Invalid" 7487 "Invalid" 7486 "Invalid" 7485 "Invalid" 7484 "Invalid" 7483 "Invalid" 7482 "Invalid" 7481 "Invalid" 7480 "Invalid" 7479 "Invalid" 7478 "Invalid" 7477 "Invalid" 7476 "Invalid" 7475 "Invalid" 7474 "Invalid" 7473 "Invalid" 7472 "Invalid" 7471 "Invalid" 7470 "Invalid" 7469 "Invalid" 7468 "Invalid" 7467 "Invalid" 7466 "Invalid" 7465 "Invalid" 7464 "Invalid" 7463 "Invalid" 7462 "Invalid" 7461 "Invalid" 7460 "Invalid" 7459 "Invalid" 7458 "Invalid" 7457 "Invalid" 7456 "Invalid" 7455 "Invalid" 7454 "Invalid" 7453 "Invalid" 7452 "Invalid" 7451 "Invalid" 7450 "Invalid" 7449 "Invalid" 7448 "Invalid" 7447 "Invalid" 7446 "Invalid" 7445 "Invalid" 7444 "Invalid" 7443 "Invalid" 7442 "Invalid" 7441 "Invalid" 7440 "Invalid" 7439 "Invalid" 7438 "Invalid" 7437 "Invalid" 7436 "Invalid" 7435 "Invalid" 7434 "Invalid" 7433 "Invalid" 7432 "Invalid" 7431 "Invalid" 7430 "Invalid" 7429 "Invalid" 7428 "Invalid" 7427 "Invalid" 7426 "Invalid" 7425 "Invalid" 7424 "Invalid" 7423 "Invalid" 7422 "Invalid" 7421 "Invalid" 7420 "Invalid" 7419 "Invalid" 7418 "Invalid" 7417 "Invalid" 7416 "Invalid" 7415 "Invalid" 7414 "Invalid" 7413 "Invalid" 7412 "Invalid" 7411 "Invalid" 7410 "Invalid" 7409 "Invalid" 7408 "Invalid" 7407 "Invalid" 7406 "Invalid" 7405 "Invalid" 7404 "Invalid" 7403 "Invalid" 7402 "Invalid" 7401 "Invalid" 7400 "Invalid" 7399 "Invalid" 7398 "Invalid" 7397 "Invalid" 7396 "Invalid" 7395 "Invalid" 7394 "Invalid" 7393 "Invalid" 7392 "Invalid" 7391 "Invalid" 7390 "Invalid" 7389 "Invalid" 7388 "Invalid" 7387 "Invalid" 7386 "Invalid" 7385 "Invalid" 7384 "Invalid" 7383 "Invalid" 7382 "Invalid" 7381 "Invalid" 7380 "Invalid" 7379 "Invalid" 7378 "Invalid" 7377 "Invalid" 7376 "Invalid" 7375 "Invalid" 7374 "Invalid" 7373 "Invalid" 7372 "Invalid" 7371 "Invalid" 7370 "Invalid" 7369 "Invalid" 7368 "Invalid" 7367 "Invalid" 7366 "Invalid" 7365 "Invalid" 7364 "Invalid" 7363 "Invalid" 7362 "Invalid" 7361 "Invalid" 7360 "Invalid" 7359 "Invalid" 7358 "Invalid" 7357 "Invalid" 7356 "Invalid" 7355 "Invalid" 7354 "Invalid" 7353 "Invalid" 7352 "Invalid" 7351 "Invalid" 7350 "Invalid" 7349 "Invalid" 7348 "Invalid" 7347 "Invalid" 7346 "Invalid" 7345 "Invalid" 7344 "Invalid" 7343 "Invalid" 7342 "Invalid" 7341 "Invalid" 7340 "Invalid" 7339 "Invalid" 7338 "Invalid" 7337 "Invalid" 7336 "Invalid" 7335 "Invalid" 7334 "Invalid" 7333 "Invalid" 7332 "Invalid" 7331 "Invalid" 7330 "Invalid" 7329 "Invalid" 7328 "Invalid" 7327 "Invalid" 7326 "Invalid" 7325 "Invalid" 7324 "Invalid" 7323 "Invalid" 7322 "Invalid" 7321 "Invalid" 7320 "Invalid" 7319 "Invalid" 7318 "Invalid" 7317 "Invalid" 7316 "Invalid" 7315 "Invalid" 7314 "Invalid" 7313 "Invalid" 7312 "Invalid" 7311 "Invalid" 7310 "Invalid" 7309 "Invalid" 7308 "Invalid" 7307 "Invalid" 7306 "Invalid" 7305 "Invalid" 7304 "Invalid" 7303 "Invalid" 7302 "Invalid" 7301 "Invalid" 7300 "Invalid" 7299 "Invalid" 7298 "Invalid" 7297 "Invalid" 7296 "Invalid" 7295 "Invalid" 7294 "Invalid" 7293 "Invalid" 7292 "Invalid" 7291 "Invalid" 7290 "Invalid" 7289 "Invalid" 7288 "Invalid" 7287 "Invalid" 7286 "Invalid" 7285 "Invalid" 7284 "Invalid" 7283 "Invalid" 7282 "Invalid" 7281 "Invalid" 7280 "Invalid" 7279 "Invalid" 7278 "Invalid" 7277 "Invalid" 7276 "Invalid" 7275 "Invalid" 7274 "Invalid" 7273 "Invalid" 7272 "Invalid" 7271 "Invalid" 7270 "Invalid" 7269 "Invalid" 7268 "Invalid" 7267 "Invalid" 7266 "Invalid" 7265 "Invalid" 7264 "Invalid" 7263 "Invalid" 7262 "Invalid" 7261 "Invalid" 7260 "Invalid" 7259 "Invalid" 7258 "Invalid" 7257 "Invalid" 7256 "Invalid" 7255 "Invalid" 7254 "Invalid" 7253 "Invalid" 7252 "Invalid" 7251 "Invalid" 7250 "Invalid" 7249 "Invalid" 7248 "Invalid" 7247 "Invalid" 7246 "Invalid" 7245 "Invalid" 7244 "Invalid" 7243 "Invalid" 7242 "Invalid" 7241 "Invalid" 7240 "Invalid" 7239 "Invalid" 7238 "Invalid" 7237 "Invalid" 7236 "Invalid" 7235 "Invalid" 7234 "Invalid" 7233 "Invalid" 7232 "Invalid" 7231 "Invalid" 7230 "Invalid" 7229 "Invalid" 7228 "Invalid" 7227 "Invalid" 7226 "Invalid" 7225 "Invalid" 7224 "Invalid" 7223 "Invalid" 7222 "Invalid" 7221 "Invalid" 7220 "Invalid" 7219 "Invalid" 7218 "Invalid" 7217 "Invalid" 7216 "Invalid" 7215 "Invalid" 7214 "Invalid" 7213 "Invalid" 7212 "Invalid" 7211 "Invalid" 7210 "Invalid" 7209 "Invalid" 7208 "Invalid" 7207 "Invalid" 7206 "Invalid" 7205 "Invalid" 7204 "Invalid" 7203 "Invalid" 7202 "Invalid" 7201 "Invalid" 7200 "Invalid" 7199 "Invalid" 7198 "Invalid" 7197 "Invalid" 7196 "Invalid" 7195 "Invalid" 7194 "Invalid" 7193 "Invalid" 7192 "Invalid" 7191 "Invalid" 7190 "Invalid" 7189 "Invalid" 7188 "Invalid" 7187 "Invalid" 7186 "Invalid" 7185 "Invalid" 7184 "Invalid" 7183 "Invalid" 7182 "Invalid" 7181 "Invalid" 7180 "Invalid" 7179 "Invalid" 7178 "Invalid" 7177 "Invalid" 7176 "Invalid" 7175 "Invalid" 7174 "Invalid" 7173 "Invalid" 7172 "Invalid" 7171 "Invalid" 7170 "Invalid" 7169 "Invalid" 7168 "Invalid" 7167 "Invalid" 7166 "Invalid" 7165 "Invalid" 7164 "Invalid" 7163 "Invalid" 7162 "Invalid" 7161 "Invalid" 7160 "Invalid" 7159 "Invalid" 7158 "Invalid" 7157 "Invalid" 7156 "Invalid" 7155 "Invalid" 7154 "Invalid" 7153 "Invalid" 7152 "Invalid" 7151 "Invalid" 7150 "Invalid" 7149 "Invalid" 7148 "Invalid" 7147 "Invalid" 7146 "Invalid" 7145 "Invalid" 7144 "Invalid" 7143 "Invalid" 7142 "Invalid" 7141 "Invalid" 7140 "Invalid" 7139 "Invalid" 7138 "Invalid" 7137 "Invalid" 7136 "Invalid" 7135 "Invalid" 7134 "Invalid" 7133 "Invalid" 7132 "Invalid" 7131 "Invalid" 7130 "Invalid" 7129 "Invalid" 7128 "Invalid" 7127 "Invalid" 7126 "Invalid" 7125 "Invalid" 7124 "Invalid" 7123 "Invalid" 7122 "Invalid" 7121 "Invalid" 7120 "Invalid" 7119 "Invalid" 7118 "Invalid" 7117 "Invalid" 7116 "Invalid" 7115 "Invalid" 7114 "Invalid" 7113 "Invalid" 7112 "Invalid" 7111 "Invalid" 7110 "Invalid" 7109 "Invalid" 7108 "Invalid" 7107 "Invalid" 7106 "Invalid" 7105 "Invalid" 7104 "Invalid" 7103 "Invalid" 7102 "Invalid" 7101 "Invalid" 7100 "Invalid" 7099 "Invalid" 7098 "Invalid" 7097 "Invalid" 7096 "Invalid" 7095 "Invalid" 7094 "Invalid" 7093 "Invalid" 7092 "Invalid" 7091 "Invalid" 7090 "Invalid" 7089 "Invalid" 7088 "Invalid" 7087 "Invalid" 7086 "Invalid" 7085 "Invalid" 7084 "Invalid" 7083 "Invalid" 7082 "Invalid" 7081 "Invalid" 7080 "Invalid" 7079 "Invalid" 7078 "Invalid" 7077 "Invalid" 7076 "Invalid" 7075 "Invalid" 7074 "Invalid" 7073 "Invalid" 7072 "Invalid" 7071 "Invalid" 7070 "Invalid" 7069 "Invalid" 7068 "Invalid" 7067 "Invalid" 7066 "Invalid" 7065 "Invalid" 7064 "Invalid" 7063 "Invalid" 7062 "Invalid" 7061 "Invalid" 7060 "Invalid" 7059 "Invalid" 7058 "Invalid" 7057 "Invalid" 7056 "Invalid" 7055 "Invalid" 7054 "Invalid" 7053 "Invalid" 7052 "Invalid" 7051 "Invalid" 7050 "Invalid" 7049 "Invalid" 7048 "Invalid" 7047 "Invalid" 7046 "Invalid" 7045 "Invalid" 7044 "Invalid" 7043 "Invalid" 7042 "Invalid" 7041 "Invalid" 7040 "Invalid" 7039 "Invalid" 7038 "Invalid" 7037 "Invalid" 7036 "Invalid" 7035 "Invalid" 7034 "Invalid" 7033 "Invalid" 7032 "Invalid" 7031 "Invalid" 7030 "Invalid" 7029 "Invalid" 7028 "Invalid" 7027 "Invalid" 7026 "Invalid" 7025 "Invalid" 7024 "Invalid" 7023 "Invalid" 7022 "Invalid" 7021 "Invalid" 7020 "Invalid" 7019 "Invalid" 7018 "Invalid" 7017 "Invalid" 7016 "Invalid" 7015 "Invalid" 7014 "Invalid" 7013 "Invalid" 7012 "Invalid" 7011 "Invalid" 7010 "Invalid" 7009 "Invalid" 7008 "Invalid" 7007 "Invalid" 7006 "Invalid" 7005 "Invalid" 7004 "Invalid" 7003 "Invalid" 7002 "Invalid" 7001 "Invalid" 7000 "Invalid" 6999 "Invalid" 6998 "Invalid" 6997 "Invalid" 6996 "Invalid" 6995 "Invalid" 6994 "Invalid" 6993 "Invalid" 6992 "Invalid" 6991 "Invalid" 6990 "Invalid" 6989 "Invalid" 6988 "Invalid" 6987 "Invalid" 6986 "Invalid" 6985 "Invalid" 6984 "Invalid" 6983 "Invalid" 6982 "Invalid" 6981 "Invalid" 6980 "Invalid" 6979 "Invalid" 6978 "Invalid" 6977 "Invalid" 6976 "Invalid" 6975 "Invalid" 6974 "Invalid" 6973 "Invalid" 6972 "Invalid" 6971 "Invalid" 6970 "Invalid" 6969 "Invalid" 6968 "Invalid" 6967 "Invalid" 6966 "Invalid" 6965 "Invalid" 6964 "Invalid" 6963 "Invalid" 6962 "Invalid" 6961 "Invalid" 6960 "Invalid" 6959 "Invalid" 6958 "Invalid" 6957 "Invalid" 6956 "Invalid" 6955 "Invalid" 6954 "Invalid" 6953 "Invalid" 6952 "Invalid" 6951 "Invalid" 6950 "Invalid" 6949 "Invalid" 6948 "Invalid" 6947 "Invalid" 6946 "Invalid" 6945 "Invalid" 6944 "Invalid" 6943 "Invalid" 6942 "Invalid" 6941 "Invalid" 6940 "Invalid" 6939 "Invalid" 6938 "Invalid" 6937 "Invalid" 6936 "Invalid" 6935 "Invalid" 6934 "Invalid" 6933 "Invalid" 6932 "Invalid" 6931 "Invalid" 6930 "Invalid" 6929 "Invalid" 6928 "Invalid" 6927 "Invalid" 6926 "Invalid" 6925 "Invalid" 6924 "Invalid" 6923 "Invalid" 6922 "Invalid" 6921 "Invalid" 6920 "Invalid" 6919 "Invalid" 6918 "Invalid" 6917 "Invalid" 6916 "Invalid" 6915 "Invalid" 6914 "Invalid" 6913 "Invalid" 6912 "Invalid" 6911 "Invalid" 6910 "Invalid" 6909 "Invalid" 6908 "Invalid" 6907 "Invalid" 6906 "Invalid" 6905 "Invalid" 6904 "Invalid" 6903 "Invalid" 6902 "Invalid" 6901 "Invalid" 6900 "Invalid" 6899 "Invalid" 6898 "Invalid" 6897 "Invalid" 6896 "Invalid" 6895 "Invalid" 6894 "Invalid" 6893 "Invalid" 6892 "Invalid" 6891 "Invalid" 6890 "Invalid" 6889 "Invalid" 6888 "Invalid" 6887 "Invalid" 6886 "Invalid" 6885 "Invalid" 6884 "Invalid" 6883 "Invalid" 6882 "Invalid" 6881 "Invalid" 6880 "Invalid" 6879 "Invalid" 6878 "Invalid" 6877 "Invalid" 6876 "Invalid" 6875 "Invalid" 6874 "Invalid" 6873 "Invalid" 6872 "Invalid" 6871 "Invalid" 6870 "Invalid" 6869 "Invalid" 6868 "Invalid" 6867 "Invalid" 6866 "Invalid" 6865 "Invalid" 6864 "Invalid" 6863 "Invalid" 6862 "Invalid" 6861 "Invalid" 6860 "Invalid" 6859 "Invalid" 6858 "Invalid" 6857 "Invalid" 6856 "Invalid" 6855 "Invalid" 6854 "Invalid" 6853 "Invalid" 6852 "Invalid" 6851 "Invalid" 6850 "Invalid" 6849 "Invalid" 6848 "Invalid" 6847 "Invalid" 6846 "Invalid" 6845 "Invalid" 6844 "Invalid" 6843 "Invalid" 6842 "Invalid" 6841 "Invalid" 6840 "Invalid" 6839 "Invalid" 6838 "Invalid" 6837 "Invalid" 6836 "Invalid" 6835 "Invalid" 6834 "Invalid" 6833 "Invalid" 6832 "Invalid" 6831 "Invalid" 6830 "Invalid" 6829 "Invalid" 6828 "Invalid" 6827 "Invalid" 6826 "Invalid" 6825 "Invalid" 6824 "Invalid" 6823 "Invalid" 6822 "Invalid" 6821 "Invalid" 6820 "Invalid" 6819 "Invalid" 6818 "Invalid" 6817 "Invalid" 6816 "Invalid" 6815 "Invalid" 6814 "Invalid" 6813 "Invalid" 6812 "Invalid" 6811 "Invalid" 6810 "Invalid" 6809 "Invalid" 6808 "Invalid" 6807 "Invalid" 6806 "Invalid" 6805 "Invalid" 6804 "Invalid" 6803 "Invalid" 6802 "Invalid" 6801 "Invalid" 6800 "Invalid" 6799 "Invalid" 6798 "Invalid" 6797 "Invalid" 6796 "Invalid" 6795 "Invalid" 6794 "Invalid" 6793 "Invalid" 6792 "Invalid" 6791 "Invalid" 6790 "Invalid" 6789 "Invalid" 6788 "Invalid" 6787 "Invalid" 6786 "Invalid" 6785 "Invalid" 6784 "Invalid" 6783 "Invalid" 6782 "Invalid" 6781 "Invalid" 6780 "Invalid" 6779 "Invalid" 6778 "Invalid" 6777 "Invalid" 6776 "Invalid" 6775 "Invalid" 6774 "Invalid" 6773 "Invalid" 6772 "Invalid" 6771 "Invalid" 6770 "Invalid" 6769 "Invalid" 6768 "Invalid" 6767 "Invalid" 6766 "Invalid" 6765 "Invalid" 6764 "Invalid" 6763 "Invalid" 6762 "Invalid" 6761 "Invalid" 6760 "Invalid" 6759 "Invalid" 6758 "Invalid" 6757 "Invalid" 6756 "Invalid" 6755 "Invalid" 6754 "Invalid" 6753 "Invalid" 6752 "Invalid" 6751 "Invalid" 6750 "Invalid" 6749 "Invalid" 6748 "Invalid" 6747 "Invalid" 6746 "Invalid" 6745 "Invalid" 6744 "Invalid" 6743 "Invalid" 6742 "Invalid" 6741 "Invalid" 6740 "Invalid" 6739 "Invalid" 6738 "Invalid" 6737 "Invalid" 6736 "Invalid" 6735 "Invalid" 6734 "Invalid" 6733 "Invalid" 6732 "Invalid" 6731 "Invalid" 6730 "Invalid" 6729 "Invalid" 6728 "Invalid" 6727 "Invalid" 6726 "Invalid" 6725 "Invalid" 6724 "Invalid" 6723 "Invalid" 6722 "Invalid" 6721 "Invalid" 6720 "Invalid" 6719 "Invalid" 6718 "Invalid" 6717 "Invalid" 6716 "Invalid" 6715 "Invalid" 6714 "Invalid" 6713 "Invalid" 6712 "Invalid" 6711 "Invalid" 6710 "Invalid" 6709 "Invalid" 6708 "Invalid" 6707 "Invalid" 6706 "Invalid" 6705 "Invalid" 6704 "Invalid" 6703 "Invalid" 6702 "Invalid" 6701 "Invalid" 6700 "Invalid" 6699 "Invalid" 6698 "Invalid" 6697 "Invalid" 6696 "Invalid" 6695 "Invalid" 6694 "Invalid" 6693 "Invalid" 6692 "Invalid" 6691 "Invalid" 6690 "Invalid" 6689 "Invalid" 6688 "Invalid" 6687 "Invalid" 6686 "Invalid" 6685 "Invalid" 6684 "Invalid" 6683 "Invalid" 6682 "Invalid" 6681 "Invalid" 6680 "Invalid" 6679 "Invalid" 6678 "Invalid" 6677 "Invalid" 6676 "Invalid" 6675 "Invalid" 6674 "Invalid" 6673 "Invalid" 6672 "Invalid" 6671 "Invalid" 6670 "Invalid" 6669 "Invalid" 6668 "Invalid" 6667 "Invalid" 6666 "Invalid" 6665 "Invalid" 6664 "Invalid" 6663 "Invalid" 6662 "Invalid" 6661 "Invalid" 6660 "Invalid" 6659 "Invalid" 6658 "Invalid" 6657 "Invalid" 6656 "Invalid" 6655 "Invalid" 6654 "Invalid" 6653 "Invalid" 6652 "Invalid" 6651 "Invalid" 6650 "Invalid" 6649 "Invalid" 6648 "Invalid" 6647 "Invalid" 6646 "Invalid" 6645 "Invalid" 6644 "Invalid" 6643 "Invalid" 6642 "Invalid" 6641 "Invalid" 6640 "Invalid" 6639 "Invalid" 6638 "Invalid" 6637 "Invalid" 6636 "Invalid" 6635 "Invalid" 6634 "Invalid" 6633 "Invalid" 6632 "Invalid" 6631 "Invalid" 6630 "Invalid" 6629 "Invalid" 6628 "Invalid" 6627 "Invalid" 6626 "Invalid" 6625 "Invalid" 6624 "Invalid" 6623 "Invalid" 6622 "Invalid" 6621 "Invalid" 6620 "Invalid" 6619 "Invalid" 6618 "Invalid" 6617 "Invalid" 6616 "Invalid" 6615 "Invalid" 6614 "Invalid" 6613 "Invalid" 6612 "Invalid" 6611 "Invalid" 6610 "Invalid" 6609 "Invalid" 6608 "Invalid" 6607 "Invalid" 6606 "Invalid" 6605 "Invalid" 6604 "Invalid" 6603 "Invalid" 6602 "Invalid" 6601 "Invalid" 6600 "Invalid" 6599 "Invalid" 6598 "Invalid" 6597 "Invalid" 6596 "Invalid" 6595 "Invalid" 6594 "Invalid" 6593 "Invalid" 6592 "Invalid" 6591 "Invalid" 6590 "Invalid" 6589 "Invalid" 6588 "Invalid" 6587 "Invalid" 6586 "Invalid" 6585 "Invalid" 6584 "Invalid" 6583 "Invalid" 6582 "Invalid" 6581 "Invalid" 6580 "Invalid" 6579 "Invalid" 6578 "Invalid" 6577 "Invalid" 6576 "Invalid" 6575 "Invalid" 6574 "Invalid" 6573 "Invalid" 6572 "Invalid" 6571 "Invalid" 6570 "Invalid" 6569 "Invalid" 6568 "Invalid" 6567 "Invalid" 6566 "Invalid" 6565 "Invalid" 6564 "Invalid" 6563 "Invalid" 6562 "Invalid" 6561 "Invalid" 6560 "Invalid" 6559 "Invalid" 6558 "Invalid" 6557 "Invalid" 6556 "Invalid" 6555 "Invalid" 6554 "Invalid" 6553 "Invalid" 6552 "Invalid" 6551 "Invalid" 6550 "Invalid" 6549 "Invalid" 6548 "Invalid" 6547 "Invalid" 6546 "Invalid" 6545 "Invalid" 6544 "Invalid" 6543 "Invalid" 6542 "Invalid" 6541 "Invalid" 6540 "Invalid" 6539 "Invalid" 6538 "Invalid" 6537 "Invalid" 6536 "Invalid" 6535 "Invalid" 6534 "Invalid" 6533 "Invalid" 6532 "Invalid" 6531 "Invalid" 6530 "Invalid" 6529 "Invalid" 6528 "Invalid" 6527 "Invalid" 6526 "Invalid" 6525 "Invalid" 6524 "Invalid" 6523 "Invalid" 6522 "Invalid" 6521 "Invalid" 6520 "Invalid" 6519 "Invalid" 6518 "Invalid" 6517 "Invalid" 6516 "Invalid" 6515 "Invalid" 6514 "Invalid" 6513 "Invalid" 6512 "Invalid" 6511 "Invalid" 6510 "Invalid" 6509 "Invalid" 6508 "Invalid" 6507 "Invalid" 6506 "Invalid" 6505 "Invalid" 6504 "Invalid" 6503 "Invalid" 6502 "Invalid" 6501 "Invalid" 6500 "Invalid" 6499 "Invalid" 6498 "Invalid" 6497 "Invalid" 6496 "Invalid" 6495 "Invalid" 6494 "Invalid" 6493 "Invalid" 6492 "Invalid" 6491 "Invalid" 6490 "Invalid" 6489 "Invalid" 6488 "Invalid" 6487 "Invalid" 6486 "Invalid" 6485 "Invalid" 6484 "Invalid" 6483 "Invalid" 6482 "Invalid" 6481 "Invalid" 6480 "Invalid" 6479 "Invalid" 6478 "Invalid" 6477 "Invalid" 6476 "Invalid" 6475 "Invalid" 6474 "Invalid" 6473 "Invalid" 6472 "Invalid" 6471 "Invalid" 6470 "Invalid" 6469 "Invalid" 6468 "Invalid" 6467 "Invalid" 6466 "Invalid" 6465 "Invalid" 6464 "Invalid" 6463 "Invalid" 6462 "Invalid" 6461 "Invalid" 6460 "Invalid" 6459 "Invalid" 6458 "Invalid" 6457 "Invalid" 6456 "Invalid" 6455 "Invalid" 6454 "Invalid" 6453 "Invalid" 6452 "Invalid" 6451 "Invalid" 6450 "Invalid" 6449 "Invalid" 6448 "Invalid" 6447 "Invalid" 6446 "Invalid" 6445 "Invalid" 6444 "Invalid" 6443 "Invalid" 6442 "Invalid" 6441 "Invalid" 6440 "Invalid" 6439 "Invalid" 6438 "Invalid" 6437 "Invalid" 6436 "Invalid" 6435 "Invalid" 6434 "Invalid" 6433 "Invalid" 6432 "Invalid" 6431 "Invalid" 6430 "Invalid" 6429 "Invalid" 6428 "Invalid" 6427 "Invalid" 6426 "Invalid" 6425 "Invalid" 6424 "Invalid" 6423 "Invalid" 6422 "Invalid" 6421 "Invalid" 6420 "Invalid" 6419 "Invalid" 6418 "Invalid" 6417 "Invalid" 6416 "Invalid" 6415 "Invalid" 6414 "Invalid" 6413 "Invalid" 6412 "Invalid" 6411 "Invalid" 6410 "Invalid" 6409 "Invalid" 6408 "Invalid" 6407 "Invalid" 6406 "Invalid" 6405 "Invalid" 6404 "Invalid" 6403 "Invalid" 6402 "Invalid" 6401 "Invalid" 6400 "Invalid" 6399 "Invalid" 6398 "Invalid" 6397 "Invalid" 6396 "Invalid" 6395 "Invalid" 6394 "Invalid" 6393 "Invalid" 6392 "Invalid" 6391 "Invalid" 6390 "Invalid" 6389 "Invalid" 6388 "Invalid" 6387 "Invalid" 6386 "Invalid" 6385 "Invalid" 6384 "Invalid" 6383 "Invalid" 6382 "Invalid" 6381 "Invalid" 6380 "Invalid" 6379 "Invalid" 6378 "Invalid" 6377 "Invalid" 6376 "Invalid" 6375 "Invalid" 6374 "Invalid" 6373 "Invalid" 6372 "Invalid" 6371 "Invalid" 6370 "Invalid" 6369 "Invalid" 6368 "Invalid" 6367 "Invalid" 6366 "Invalid" 6365 "Invalid" 6364 "Invalid" 6363 "Invalid" 6362 "Invalid" 6361 "Invalid" 6360 "Invalid" 6359 "Invalid" 6358 "Invalid" 6357 "Invalid" 6356 "Invalid" 6355 "Invalid" 6354 "Invalid" 6353 "Invalid" 6352 "Invalid" 6351 "Invalid" 6350 "Invalid" 6349 "Invalid" 6348 "Invalid" 6347 "Invalid" 6346 "Invalid" 6345 "Invalid" 6344 "Invalid" 6343 "Invalid" 6342 "Invalid" 6341 "Invalid" 6340 "Invalid" 6339 "Invalid" 6338 "Invalid" 6337 "Invalid" 6336 "Invalid" 6335 "Invalid" 6334 "Invalid" 6333 "Invalid" 6332 "Invalid" 6331 "Invalid" 6330 "Invalid" 6329 "Invalid" 6328 "Invalid" 6327 "Invalid" 6326 "Invalid" 6325 "Invalid" 6324 "Invalid" 6323 "Invalid" 6322 "Invalid" 6321 "Invalid" 6320 "Invalid" 6319 "Invalid" 6318 "Invalid" 6317 "Invalid" 6316 "Invalid" 6315 "Invalid" 6314 "Invalid" 6313 "Invalid" 6312 "Invalid" 6311 "Invalid" 6310 "Invalid" 6309 "Invalid" 6308 "Invalid" 6307 "Invalid" 6306 "Invalid" 6305 "Invalid" 6304 "Invalid" 6303 "Invalid" 6302 "Invalid" 6301 "Invalid" 6300 "Invalid" 6299 "Invalid" 6298 "Invalid" 6297 "Invalid" 6296 "Invalid" 6295 "Invalid" 6294 "Invalid" 6293 "Invalid" 6292 "Invalid" 6291 "Invalid" 6290 "Invalid" 6289 "Invalid" 6288 "Invalid" 6287 "Invalid" 6286 "Invalid" 6285 "Invalid" 6284 "Invalid" 6283 "Invalid" 6282 "Invalid" 6281 "Invalid" 6280 "Invalid" 6279 "Invalid" 6278 "Invalid" 6277 "Invalid" 6276 "Invalid" 6275 "Invalid" 6274 "Invalid" 6273 "Invalid" 6272 "Invalid" 6271 "Invalid" 6270 "Invalid" 6269 "Invalid" 6268 "Invalid" 6267 "Invalid" 6266 "Invalid" 6265 "Invalid" 6264 "Invalid" 6263 "Invalid" 6262 "Invalid" 6261 "Invalid" 6260 "Invalid" 6259 "Invalid" 6258 "Invalid" 6257 "Invalid" 6256 "Invalid" 6255 "Invalid" 6254 "Invalid" 6253 "Invalid" 6252 "Invalid" 6251 "Invalid" 6250 "Invalid" 6249 "Invalid" 6248 "Invalid" 6247 "Invalid" 6246 "Invalid" 6245 "Invalid" 6244 "Invalid" 6243 "Invalid" 6242 "Invalid" 6241 "Invalid" 6240 "Invalid" 6239 "Invalid" 6238 "Invalid" 6237 "Invalid" 6236 "Invalid" 6235 "Invalid" 6234 "Invalid" 6233 "Invalid" 6232 "Invalid" 6231 "Invalid" 6230 "Invalid" 6229 "Invalid" 6228 "Invalid" 6227 "Invalid" 6226 "Invalid" 6225 "Invalid" 6224 "Invalid" 6223 "Invalid" 6222 "Invalid" 6221 "Invalid" 6220 "Invalid" 6219 "Invalid" 6218 "Invalid" 6217 "Invalid" 6216 "Invalid" 6215 "Invalid" 6214 "Invalid" 6213 "Invalid" 6212 "Invalid" 6211 "Invalid" 6210 "Invalid" 6209 "Invalid" 6208 "Invalid" 6207 "Invalid" 6206 "Invalid" 6205 "Invalid" 6204 "Invalid" 6203 "Invalid" 6202 "Invalid" 6201 "Invalid" 6200 "Invalid" 6199 "Invalid" 6198 "Invalid" 6197 "Invalid" 6196 "Invalid" 6195 "Invalid" 6194 "Invalid" 6193 "Invalid" 6192 "Invalid" 6191 "Invalid" 6190 "Invalid" 6189 "Invalid" 6188 "Invalid" 6187 "Invalid" 6186 "Invalid" 6185 "Invalid" 6184 "Invalid" 6183 "Invalid" 6182 "Invalid" 6181 "Invalid" 6180 "Invalid" 6179 "Invalid" 6178 "Invalid" 6177 "Invalid" 6176 "Invalid" 6175 "Invalid" 6174 "Invalid" 6173 "Invalid" 6172 "Invalid" 6171 "Invalid" 6170 "Invalid" 6169 "Invalid" 6168 "Invalid" 6167 "Invalid" 6166 "Invalid" 6165 "Invalid" 6164 "Invalid" 6163 "Invalid" 6162 "Invalid" 6161 "Invalid" 6160 "Invalid" 6159 "Invalid" 6158 "Invalid" 6157 "Invalid" 6156 "Invalid" 6155 "Invalid" 6154 "Invalid" 6153 "Invalid" 6152 "Invalid" 6151 "Invalid" 6150 "Invalid" 6149 "Invalid" 6148 "Invalid" 6147 "Invalid" 6146 "Invalid" 6145 "Invalid" 6144 "Invalid" 6143 "Invalid" 6142 "Invalid" 6141 "Invalid" 6140 "Invalid" 6139 "Invalid" 6138 "Invalid" 6137 "Invalid" 6136 "Invalid" 6135 "Invalid" 6134 "Invalid" 6133 "Invalid" 6132 "Invalid" 6131 "Invalid" 6130 "Invalid" 6129 "Invalid" 6128 "Invalid" 6127 "Invalid" 6126 "Invalid" 6125 "Invalid" 6124 "Invalid" 6123 "Invalid" 6122 "Invalid" 6121 "Invalid" 6120 "Invalid" 6119 "Invalid" 6118 "Invalid" 6117 "Invalid" 6116 "Invalid" 6115 "Invalid" 6114 "Invalid" 6113 "Invalid" 6112 "Invalid" 6111 "Invalid" 6110 "Invalid" 6109 "Invalid" 6108 "Invalid" 6107 "Invalid" 6106 "Invalid" 6105 "Invalid" 6104 "Invalid" 6103 "Invalid" 6102 "Invalid" 6101 "Invalid" 6100 "Invalid" 6099 "Invalid" 6098 "Invalid" 6097 "Invalid" 6096 "Invalid" 6095 "Invalid" 6094 "Invalid" 6093 "Invalid" 6092 "Invalid" 6091 "Invalid" 6090 "Invalid" 6089 "Invalid" 6088 "Invalid" 6087 "Invalid" 6086 "Invalid" 6085 "Invalid" 6084 "Invalid" 6083 "Invalid" 6082 "Invalid" 6081 "Invalid" 6080 "Invalid" 6079 "Invalid" 6078 "Invalid" 6077 "Invalid" 6076 "Invalid" 6075 "Invalid" 6074 "Invalid" 6073 "Invalid" 6072 "Invalid" 6071 "Invalid" 6070 "Invalid" 6069 "Invalid" 6068 "Invalid" 6067 "Invalid" 6066 "Invalid" 6065 "Invalid" 6064 "Invalid" 6063 "Invalid" 6062 "Invalid" 6061 "Invalid" 6060 "Invalid" 6059 "Invalid" 6058 "Invalid" 6057 "Invalid" 6056 "Invalid" 6055 "Invalid" 6054 "Invalid" 6053 "Invalid" 6052 "Invalid" 6051 "Invalid" 6050 "Invalid" 6049 "Invalid" 6048 "Invalid" 6047 "Invalid" 6046 "Invalid" 6045 "Invalid" 6044 "Invalid" 6043 "Invalid" 6042 "Invalid" 6041 "Invalid" 6040 "Invalid" 6039 "Invalid" 6038 "Invalid" 6037 "Invalid" 6036 "Invalid" 6035 "Invalid" 6034 "Invalid" 6033 "Invalid" 6032 "Invalid" 6031 "Invalid" 6030 "Invalid" 6029 "Invalid" 6028 "Invalid" 6027 "Invalid" 6026 "Invalid" 6025 "Invalid" 6024 "Invalid" 6023 "Invalid" 6022 "Invalid" 6021 "Invalid" 6020 "Invalid" 6019 "Invalid" 6018 "Invalid" 6017 "Invalid" 6016 "Invalid" 6015 "Invalid" 6014 "Invalid" 6013 "Invalid" 6012 "Invalid" 6011 "Invalid" 6010 "Invalid" 6009 "Invalid" 6008 "Invalid" 6007 "Invalid" 6006 "Invalid" 6005 "Invalid" 6004 "Invalid" 6003 "Invalid" 6002 "Invalid" 6001 "Invalid" 6000 "Invalid" 5999 "Invalid" 5998 "Invalid" 5997 "Invalid" 5996 "Invalid" 5995 "Invalid" 5994 "Invalid" 5993 "Invalid" 5992 "Invalid" 5991 "Invalid" 5990 "Invalid" 5989 "Invalid" 5988 "Invalid" 5987 "Invalid" 5986 "Invalid" 5985 "Invalid" 5984 "Invalid" 5983 "Invalid" 5982 "Invalid" 5981 "Invalid" 5980 "Invalid" 5979 "Invalid" 5978 "Invalid" 5977 "Invalid" 5976 "Invalid" 5975 "Invalid" 5974 "Invalid" 5973 "Invalid" 5972 "Invalid" 5971 "Invalid" 5970 "Invalid" 5969 "Invalid" 5968 "Invalid" 5967 "Invalid" 5966 "Invalid" 5965 "Invalid" 5964 "Invalid" 5963 "Invalid" 5962 "Invalid" 5961 "Invalid" 5960 "Invalid" 5959 "Invalid" 5958 "Invalid" 5957 "Invalid" 5956 "Invalid" 5955 "Invalid" 5954 "Invalid" 5953 "Invalid" 5952 "Invalid" 5951 "Invalid" 5950 "Invalid" 5949 "Invalid" 5948 "Invalid" 5947 "Invalid" 5946 "Invalid" 5945 "Invalid" 5944 "Invalid" 5943 "Invalid" 5942 "Invalid" 5941 "Invalid" 5940 "Invalid" 5939 "Invalid" 5938 "Invalid" 5937 "Invalid" 5936 "Invalid" 5935 "Invalid" 5934 "Invalid" 5933 "Invalid" 5932 "Invalid" 5931 "Invalid" 5930 "Invalid" 5929 "Invalid" 5928 "Invalid" 5927 "Invalid" 5926 "Invalid" 5925 "Invalid" 5924 "Invalid" 5923 "Invalid" 5922 "Invalid" 5921 "Invalid" 5920 "Invalid" 5919 "Invalid" 5918 "Invalid" 5917 "Invalid" 5916 "Invalid" 5915 "Invalid" 5914 "Invalid" 5913 "Invalid" 5912 "Invalid" 5911 "Invalid" 5910 "Invalid" 5909 "Invalid" 5908 "Invalid" 5907 "Invalid" 5906 "Invalid" 5905 "Invalid" 5904 "Invalid" 5903 "Invalid" 5902 "Invalid" 5901 "Invalid" 5900 "Invalid" 5899 "Invalid" 5898 "Invalid" 5897 "Invalid" 5896 "Invalid" 5895 "Invalid" 5894 "Invalid" 5893 "Invalid" 5892 "Invalid" 5891 "Invalid" 5890 "Invalid" 5889 "Invalid" 5888 "Invalid" 5887 "Invalid" 5886 "Invalid" 5885 "Invalid" 5884 "Invalid" 5883 "Invalid" 5882 "Invalid" 5881 "Invalid" 5880 "Invalid" 5879 "Invalid" 5878 "Invalid" 5877 "Invalid" 5876 "Invalid" 5875 "Invalid" 5874 "Invalid" 5873 "Invalid" 5872 "Invalid" 5871 "Invalid" 5870 "Invalid" 5869 "Invalid" 5868 "Invalid" 5867 "Invalid" 5866 "Invalid" 5865 "Invalid" 5864 "Invalid" 5863 "Invalid" 5862 "Invalid" 5861 "Invalid" 5860 "Invalid" 5859 "Invalid" 5858 "Invalid" 5857 "Invalid" 5856 "Invalid" 5855 "Invalid" 5854 "Invalid" 5853 "Invalid" 5852 "Invalid" 5851 "Invalid" 5850 "Invalid" 5849 "Invalid" 5848 "Invalid" 5847 "Invalid" 5846 "Invalid" 5845 "Invalid" 5844 "Invalid" 5843 "Invalid" 5842 "Invalid" 5841 "Invalid" 5840 "Invalid" 5839 "Invalid" 5838 "Invalid" 5837 "Invalid" 5836 "Invalid" 5835 "Invalid" 5834 "Invalid" 5833 "Invalid" 5832 "Invalid" 5831 "Invalid" 5830 "Invalid" 5829 "Invalid" 5828 "Invalid" 5827 "Invalid" 5826 "Invalid" 5825 "Invalid" 5824 "Invalid" 5823 "Invalid" 5822 "Invalid" 5821 "Invalid" 5820 "Invalid" 5819 "Invalid" 5818 "Invalid" 5817 "Invalid" 5816 "Invalid" 5815 "Invalid" 5814 "Invalid" 5813 "Invalid" 5812 "Invalid" 5811 "Invalid" 5810 "Invalid" 5809 "Invalid" 5808 "Invalid" 5807 "Invalid" 5806 "Invalid" 5805 "Invalid" 5804 "Invalid" 5803 "Invalid" 5802 "Invalid" 5801 "Invalid" 5800 "Invalid" 5799 "Invalid" 5798 "Invalid" 5797 "Invalid" 5796 "Invalid" 5795 "Invalid" 5794 "Invalid" 5793 "Invalid" 5792 "Invalid" 5791 "Invalid" 5790 "Invalid" 5789 "Invalid" 5788 "Invalid" 5787 "Invalid" 5786 "Invalid" 5785 "Invalid" 5784 "Invalid" 5783 "Invalid" 5782 "Invalid" 5781 "Invalid" 5780 "Invalid" 5779 "Invalid" 5778 "Invalid" 5777 "Invalid" 5776 "Invalid" 5775 "Invalid" 5774 "Invalid" 5773 "Invalid" 5772 "Invalid" 5771 "Invalid" 5770 "Invalid" 5769 "Invalid" 5768 "Invalid" 5767 "Invalid" 5766 "Invalid" 5765 "Invalid" 5764 "Invalid" 5763 "Invalid" 5762 "Invalid" 5761 "Invalid" 5760 "Invalid" 5759 "Invalid" 5758 "Invalid" 5757 "Invalid" 5756 "Invalid" 5755 "Invalid" 5754 "Invalid" 5753 "Invalid" 5752 "Invalid" 5751 "Invalid" 5750 "Invalid" 5749 "Invalid" 5748 "Invalid" 5747 "Invalid" 5746 "Invalid" 5745 "Invalid" 5744 "Invalid" 5743 "Invalid" 5742 "Invalid" 5741 "Invalid" 5740 "Invalid" 5739 "Invalid" 5738 "Invalid" 5737 "Invalid" 5736 "Invalid" 5735 "Invalid" 5734 "Invalid" 5733 "Invalid" 5732 "Invalid" 5731 "Invalid" 5730 "Invalid" 5729 "Invalid" 5728 "Invalid" 5727 "Invalid" 5726 "Invalid" 5725 "Invalid" 5724 "Invalid" 5723 "Invalid" 5722 "Invalid" 5721 "Invalid" 5720 "Invalid" 5719 "Invalid" 5718 "Invalid" 5717 "Invalid" 5716 "Invalid" 5715 "Invalid" 5714 "Invalid" 5713 "Invalid" 5712 "Invalid" 5711 "Invalid" 5710 "Invalid" 5709 "Invalid" 5708 "Invalid" 5707 "Invalid" 5706 "Invalid" 5705 "Invalid" 5704 "Invalid" 5703 "Invalid" 5702 "Invalid" 5701 "Invalid" 5700 "Invalid" 5699 "Invalid" 5698 "Invalid" 5697 "Invalid" 5696 "Invalid" 5695 "Invalid" 5694 "Invalid" 5693 "Invalid" 5692 "Invalid" 5691 "Invalid" 5690 "Invalid" 5689 "Invalid" 5688 "Invalid" 5687 "Invalid" 5686 "Invalid" 5685 "Invalid" 5684 "Invalid" 5683 "Invalid" 5682 "Invalid" 5681 "Invalid" 5680 "Invalid" 5679 "Invalid" 5678 "Invalid" 5677 "Invalid" 5676 "Invalid" 5675 "Invalid" 5674 "Invalid" 5673 "Invalid" 5672 "Invalid" 5671 "Invalid" 5670 "Invalid" 5669 "Invalid" 5668 "Invalid" 5667 "Invalid" 5666 "Invalid" 5665 "Invalid" 5664 "Invalid" 5663 "Invalid" 5662 "Invalid" 5661 "Invalid" 5660 "Invalid" 5659 "Invalid" 5658 "Invalid" 5657 "Invalid" 5656 "Invalid" 5655 "Invalid" 5654 "Invalid" 5653 "Invalid" 5652 "Invalid" 5651 "Invalid" 5650 "Invalid" 5649 "Invalid" 5648 "Invalid" 5647 "Invalid" 5646 "Invalid" 5645 "Invalid" 5644 "Invalid" 5643 "Invalid" 5642 "Invalid" 5641 "Invalid" 5640 "Invalid" 5639 "Invalid" 5638 "Invalid" 5637 "Invalid" 5636 "Invalid" 5635 "Invalid" 5634 "Invalid" 5633 "Invalid" 5632 "Invalid" 5631 "Invalid" 5630 "Invalid" 5629 "Invalid" 5628 "Invalid" 5627 "Invalid" 5626 "Invalid" 5625 "Invalid" 5624 "Invalid" 5623 "Invalid" 5622 "Invalid" 5621 "Invalid" 5620 "Invalid" 5619 "Invalid" 5618 "Invalid" 5617 "Invalid" 5616 "Invalid" 5615 "Invalid" 5614 "Invalid" 5613 "Invalid" 5612 "Invalid" 5611 "Invalid" 5610 "Invalid" 5609 "Invalid" 5608 "Invalid" 5607 "Invalid" 5606 "Invalid" 5605 "Invalid" 5604 "Invalid" 5603 "Invalid" 5602 "Invalid" 5601 "Invalid" 5600 "Invalid" 5599 "Invalid" 5598 "Invalid" 5597 "Invalid" 5596 "Invalid" 5595 "Invalid" 5594 "Invalid" 5593 "Invalid" 5592 "Invalid" 5591 "Invalid" 5590 "Invalid" 5589 "Invalid" 5588 "Invalid" 5587 "Invalid" 5586 "Invalid" 5585 "Invalid" 5584 "Invalid" 5583 "Invalid" 5582 "Invalid" 5581 "Invalid" 5580 "Invalid" 5579 "Invalid" 5578 "Invalid" 5577 "Invalid" 5576 "Invalid" 5575 "Invalid" 5574 "Invalid" 5573 "Invalid" 5572 "Invalid" 5571 "Invalid" 5570 "Invalid" 5569 "Invalid" 5568 "Invalid" 5567 "Invalid" 5566 "Invalid" 5565 "Invalid" 5564 "Invalid" 5563 "Invalid" 5562 "Invalid" 5561 "Invalid" 5560 "Invalid" 5559 "Invalid" 5558 "Invalid" 5557 "Invalid" 5556 "Invalid" 5555 "Invalid" 5554 "Invalid" 5553 "Invalid" 5552 "Invalid" 5551 "Invalid" 5550 "Invalid" 5549 "Invalid" 5548 "Invalid" 5547 "Invalid" 5546 "Invalid" 5545 "Invalid" 5544 "Invalid" 5543 "Invalid" 5542 "Invalid" 5541 "Invalid" 5540 "Invalid" 5539 "Invalid" 5538 "Invalid" 5537 "Invalid" 5536 "Invalid" 5535 "Invalid" 5534 "Invalid" 5533 "Invalid" 5532 "Invalid" 5531 "Invalid" 5530 "Invalid" 5529 "Invalid" 5528 "Invalid" 5527 "Invalid" 5526 "Invalid" 5525 "Invalid" 5524 "Invalid" 5523 "Invalid" 5522 "Invalid" 5521 "Invalid" 5520 "Invalid" 5519 "Invalid" 5518 "Invalid" 5517 "Invalid" 5516 "Invalid" 5515 "Invalid" 5514 "Invalid" 5513 "Invalid" 5512 "Invalid" 5511 "Invalid" 5510 "Invalid" 5509 "Invalid" 5508 "Invalid" 5507 "Invalid" 5506 "Invalid" 5505 "Invalid" 5504 "Invalid" 5503 "Invalid" 5502 "Invalid" 5501 "Invalid" 5500 "Invalid" 5499 "Invalid" 5498 "Invalid" 5497 "Invalid" 5496 "Invalid" 5495 "Invalid" 5494 "Invalid" 5493 "Invalid" 5492 "Invalid" 5491 "Invalid" 5490 "Invalid" 5489 "Invalid" 5488 "Invalid" 5487 "Invalid" 5486 "Invalid" 5485 "Invalid" 5484 "Invalid" 5483 "Invalid" 5482 "Invalid" 5481 "Invalid" 5480 "Invalid" 5479 "Invalid" 5478 "Invalid" 5477 "Invalid" 5476 "Invalid" 5475 "Invalid" 5474 "Invalid" 5473 "Invalid" 5472 "Invalid" 5471 "Invalid" 5470 "Invalid" 5469 "Invalid" 5468 "Invalid" 5467 "Invalid" 5466 "Invalid" 5465 "Invalid" 5464 "Invalid" 5463 "Invalid" 5462 "Invalid" 5461 "Invalid" 5460 "Invalid" 5459 "Invalid" 5458 "Invalid" 5457 "Invalid" 5456 "Invalid" 5455 "Invalid" 5454 "Invalid" 5453 "Invalid" 5452 "Invalid" 5451 "Invalid" 5450 "Invalid" 5449 "Invalid" 5448 "Invalid" 5447 "Invalid" 5446 "Invalid" 5445 "Invalid" 5444 "Invalid" 5443 "Invalid" 5442 "Invalid" 5441 "Invalid" 5440 "Invalid" 5439 "Invalid" 5438 "Invalid" 5437 "Invalid" 5436 "Invalid" 5435 "Invalid" 5434 "Invalid" 5433 "Invalid" 5432 "Invalid" 5431 "Invalid" 5430 "Invalid" 5429 "Invalid" 5428 "Invalid" 5427 "Invalid" 5426 "Invalid" 5425 "Invalid" 5424 "Invalid" 5423 "Invalid" 5422 "Invalid" 5421 "Invalid" 5420 "Invalid" 5419 "Invalid" 5418 "Invalid" 5417 "Invalid" 5416 "Invalid" 5415 "Invalid" 5414 "Invalid" 5413 "Invalid" 5412 "Invalid" 5411 "Invalid" 5410 "Invalid" 5409 "Invalid" 5408 "Invalid" 5407 "Invalid" 5406 "Invalid" 5405 "Invalid" 5404 "Invalid" 5403 "Invalid" 5402 "Invalid" 5401 "Invalid" 5400 "Invalid" 5399 "Invalid" 5398 "Invalid" 5397 "Invalid" 5396 "Invalid" 5395 "Invalid" 5394 "Invalid" 5393 "Invalid" 5392 "Invalid" 5391 "Invalid" 5390 "Invalid" 5389 "Invalid" 5388 "Invalid" 5387 "Invalid" 5386 "Invalid" 5385 "Invalid" 5384 "Invalid" 5383 "Invalid" 5382 "Invalid" 5381 "Invalid" 5380 "Invalid" 5379 "Invalid" 5378 "Invalid" 5377 "Invalid" 5376 "Invalid" 5375 "Invalid" 5374 "Invalid" 5373 "Invalid" 5372 "Invalid" 5371 "Invalid" 5370 "Invalid" 5369 "Invalid" 5368 "Invalid" 5367 "Invalid" 5366 "Invalid" 5365 "Invalid" 5364 "Invalid" 5363 "Invalid" 5362 "Invalid" 5361 "Invalid" 5360 "Invalid" 5359 "Invalid" 5358 "Invalid" 5357 "Invalid" 5356 "Invalid" 5355 "Invalid" 5354 "Invalid" 5353 "Invalid" 5352 "Invalid" 5351 "Invalid" 5350 "Invalid" 5349 "Invalid" 5348 "Invalid" 5347 "Invalid" 5346 "Invalid" 5345 "Invalid" 5344 "Invalid" 5343 "Invalid" 5342 "Invalid" 5341 "Invalid" 5340 "Invalid" 5339 "Invalid" 5338 "Invalid" 5337 "Invalid" 5336 "Invalid" 5335 "Invalid" 5334 "Invalid" 5333 "Invalid" 5332 "Invalid" 5331 "Invalid" 5330 "Invalid" 5329 "Invalid" 5328 "Invalid" 5327 "Invalid" 5326 "Invalid" 5325 "Invalid" 5324 "Invalid" 5323 "Invalid" 5322 "Invalid" 5321 "Invalid" 5320 "Invalid" 5319 "Invalid" 5318 "Invalid" 5317 "Invalid" 5316 "Invalid" 5315 "Invalid" 5314 "Invalid" 5313 "Invalid" 5312 "Invalid" 5311 "Invalid" 5310 "Invalid" 5309 "Invalid" 5308 "Invalid" 5307 "Invalid" 5306 "Invalid" 5305 "Invalid" 5304 "Invalid" 5303 "Invalid" 5302 "Invalid" 5301 "Invalid" 5300 "Invalid" 5299 "Invalid" 5298 "Invalid" 5297 "Invalid" 5296 "Invalid" 5295 "Invalid" 5294 "Invalid" 5293 "Invalid" 5292 "Invalid" 5291 "Invalid" 5290 "Invalid" 5289 "Invalid" 5288 "Invalid" 5287 "Invalid" 5286 "Invalid" 5285 "Invalid" 5284 "Invalid" 5283 "Invalid" 5282 "Invalid" 5281 "Invalid" 5280 "Invalid" 5279 "Invalid" 5278 "Invalid" 5277 "Invalid" 5276 "Invalid" 5275 "Invalid" 5274 "Invalid" 5273 "Invalid" 5272 "Invalid" 5271 "Invalid" 5270 "Invalid" 5269 "Invalid" 5268 "Invalid" 5267 "Invalid" 5266 "Invalid" 5265 "Invalid" 5264 "Invalid" 5263 "Invalid" 5262 "Invalid" 5261 "Invalid" 5260 "Invalid" 5259 "Invalid" 5258 "Invalid" 5257 "Invalid" 5256 "Invalid" 5255 "Invalid" 5254 "Invalid" 5253 "Invalid" 5252 "Invalid" 5251 "Invalid" 5250 "Invalid" 5249 "Invalid" 5248 "Invalid" 5247 "Invalid" 5246 "Invalid" 5245 "Invalid" 5244 "Invalid" 5243 "Invalid" 5242 "Invalid" 5241 "Invalid" 5240 "Invalid" 5239 "Invalid" 5238 "Invalid" 5237 "Invalid" 5236 "Invalid" 5235 "Invalid" 5234 "Invalid" 5233 "Invalid" 5232 "Invalid" 5231 "Invalid" 5230 "Invalid" 5229 "Invalid" 5228 "Invalid" 5227 "Invalid" 5226 "Invalid" 5225 "Invalid" 5224 "Invalid" 5223 "Invalid" 5222 "Invalid" 5221 "Invalid" 5220 "Invalid" 5219 "Invalid" 5218 "Invalid" 5217 "Invalid" 5216 "Invalid" 5215 "Invalid" 5214 "Invalid" 5213 "Invalid" 5212 "Invalid" 5211 "Invalid" 5210 "Invalid" 5209 "Invalid" 5208 "Invalid" 5207 "Invalid" 5206 "Invalid" 5205 "Invalid" 5204 "Invalid" 5203 "Invalid" 5202 "Invalid" 5201 "Invalid" 5200 "Invalid" 5199 "Invalid" 5198 "Invalid" 5197 "Invalid" 5196 "Invalid" 5195 "Invalid" 5194 "Invalid" 5193 "Invalid" 5192 "Invalid" 5191 "Invalid" 5190 "Invalid" 5189 "Invalid" 5188 "Invalid" 5187 "Invalid" 5186 "Invalid" 5185 "Invalid" 5184 "Invalid" 5183 "Invalid" 5182 "Invalid" 5181 "Invalid" 5180 "Invalid" 5179 "Invalid" 5178 "Invalid" 5177 "Invalid" 5176 "Invalid" 5175 "Invalid" 5174 "Invalid" 5173 "Invalid" 5172 "Invalid" 5171 "Invalid" 5170 "Invalid" 5169 "Invalid" 5168 "Invalid" 5167 "Invalid" 5166 "Invalid" 5165 "Invalid" 5164 "Invalid" 5163 "Invalid" 5162 "Invalid" 5161 "Invalid" 5160 "Invalid" 5159 "Invalid" 5158 "Invalid" 5157 "Invalid" 5156 "Invalid" 5155 "Invalid" 5154 "Invalid" 5153 "Invalid" 5152 "Invalid" 5151 "Invalid" 5150 "Invalid" 5149 "Invalid" 5148 "Invalid" 5147 "Invalid" 5146 "Invalid" 5145 "Invalid" 5144 "Invalid" 5143 "Invalid" 5142 "Invalid" 5141 "Invalid" 5140 "Invalid" 5139 "Invalid" 5138 "Invalid" 5137 "Invalid" 5136 "Invalid" 5135 "Invalid" 5134 "Invalid" 5133 "Invalid" 5132 "Invalid" 5131 "Invalid" 5130 "Invalid" 5129 "Invalid" 5128 "Invalid" 5127 "Invalid" 5126 "Invalid" 5125 "Invalid" 5124 "Invalid" 5123 "Invalid" 5122 "Invalid" 5121 "Invalid" 5120 "Invalid" 5119 "Invalid" 5118 "Invalid" 5117 "Invalid" 5116 "Invalid" 5115 "Invalid" 5114 "Invalid" 5113 "Invalid" 5112 "Invalid" 5111 "Invalid" 5110 "Invalid" 5109 "Invalid" 5108 "Invalid" 5107 "Invalid" 5106 "Invalid" 5105 "Invalid" 5104 "Invalid" 5103 "Invalid" 5102 "Invalid" 5101 "Invalid" 5100 "Invalid" 5099 "Invalid" 5098 "Invalid" 5097 "Invalid" 5096 "Invalid" 5095 "Invalid" 5094 "Invalid" 5093 "Invalid" 5092 "Invalid" 5091 "Invalid" 5090 "Invalid" 5089 "Invalid" 5088 "Invalid" 5087 "Invalid" 5086 "Invalid" 5085 "Invalid" 5084 "Invalid" 5083 "Invalid" 5082 "Invalid" 5081 "Invalid" 5080 "Invalid" 5079 "Invalid" 5078 "Invalid" 5077 "Invalid" 5076 "Invalid" 5075 "Invalid" 5074 "Invalid" 5073 "Invalid" 5072 "Invalid" 5071 "Invalid" 5070 "Invalid" 5069 "Invalid" 5068 "Invalid" 5067 "Invalid" 5066 "Invalid" 5065 "Invalid" 5064 "Invalid" 5063 "Invalid" 5062 "Invalid" 5061 "Invalid" 5060 "Invalid" 5059 "Invalid" 5058 "Invalid" 5057 "Invalid" 5056 "Invalid" 5055 "Invalid" 5054 "Invalid" 5053 "Invalid" 5052 "Invalid" 5051 "Invalid" 5050 "Invalid" 5049 "Invalid" 5048 "Invalid" 5047 "Invalid" 5046 "Invalid" 5045 "Invalid" 5044 "Invalid" 5043 "Invalid" 5042 "Invalid" 5041 "Invalid" 5040 "Invalid" 5039 "Invalid" 5038 "Invalid" 5037 "Invalid" 5036 "Invalid" 5035 "Invalid" 5034 "Invalid" 5033 "Invalid" 5032 "Invalid" 5031 "Invalid" 5030 "Invalid" 5029 "Invalid" 5028 "Invalid" 5027 "Invalid" 5026 "Invalid" 5025 "Invalid" 5024 "Invalid" 5023 "Invalid" 5022 "Invalid" 5021 "Invalid" 5020 "Invalid" 5019 "Invalid" 5018 "Invalid" 5017 "Invalid" 5016 "Invalid" 5015 "Invalid" 5014 "Invalid" 5013 "Invalid" 5012 "Invalid" 5011 "Invalid" 5010 "Invalid" 5009 "Invalid" 5008 "Invalid" 5007 "Invalid" 5006 "Invalid" 5005 "Invalid" 5004 "Invalid" 5003 "Invalid" 5002 "Invalid" 5001 "Invalid" ;
VAL_ 529 BCU_BattCpLowWarn 1 "Warning" 0 "No Warning" ;
VAL_ 536 BCU_BattOverTmp 1 "Fault" 0 "Normal" ;
VAL_ 196 SAS_SteerAg 65535 "Invalid" ;
VAL_ 196 SAS_SteerAgVld 1 "Invalidity" 0 "Validity" ;
VAL_ 48 ACU_DrvrBkl_Sts 1 "Driver Buckle Lock" 0 "Driver Buckle Unlock" ;
VAL_ 48 ACU_PassBkl_Sts 1 "Passenger Buckle Lock(buckle unlock, no passenger； buckle lock, have or no passenger)" 0 "Passenger Buckle Unlock(buckle unlock, have passenger)" ;
VAL_ 48 ACU_ReDrvrBkl_Sts 1 "Rear Driver Buckle Lock" 0 "Rear Driver Buckle Unlock" ;
VAL_ 48 ACU_RePassBkl_Sts 1 "Rear Pass Buckle Lock" 0 "Rear Pass Buckle Unlock" ;
VAL_ 48 ACU_ReCtrBkl_Sts 1 "Rear Center Buckle Lock" 0 "Rear Center Buckle Unlock" ;
VAL_ 48 ACU_SWL_Ind 3 "Not used" 2 "Warning Lamp flash(Before EOL)" 1 "Warning Lamp off" 0 "Warning Lamp on" ;
VAL_ 576 FRM_PEBS_AEBReq 1 "Demand" 0 "No demand" ;
VAL_ 576 FRM_ACCMod 7 "Failure mode" 6 "Reserved" 5 "Brake-Only mode" 4 "Override" 3 "Active-Control mode" 2 "Stand-By mode" 1 "Passive mode" 0 "OFF mode" ;
VAL_ 576 FRM_TiGapSet 3 "TimeGap_3" 2 "TimeGap_2" 1 "TimeGap_1" 0 "No display" ;
VAL_ 576 FRM_TextInform 7 "MRR blindness" 6 "ACC is switched off" 5 "ACC is switched on" 4 "ACC&PEBS in error mode" 3 "Active" 2 "ACC is cancelled" 1 "Unable to active ACC" 0 "No display" ;
VAL_ 576 FRM_FCWSetFb 1 "On" 0 "Off" ;
VAL_ 576 FRM_AEBSetFb 1 "On" 0 "Off" ;
VAL_ 576 FRM_PedestrianProtcSwchFb 1 "On" 0 "Off" ;
VAL_ 576 FRM_DxTarObj 3 "Distance_3/3 bar" 2 "Distance_2/2 bar" 1 "Distance_1/1 bar" 0 "No display" ;
VAL_ 576 FRM_ObjVld 1 "Target object detected" 0 "No object" ;
VAL_ 576 FRM_AEB_Flt 1 "Fail" 0 "No fail" ;
VAL_ 576 FRM_FCW_LatentWarn 1 "Warning" 0 "No warning" ;
VAL_ 576 FRM_FCW_Flt 1 "Fail" 0 "No fail" ;
VAL_ 576 FRM_FCW_PreWarn 1 "Warning" 0 "No warning" ;
VAL_ 576 FRM_TakeOverReq 1 "Valid TakeOver request" 0 "No TakeOver request" ;
VAL_ 576 FRM_TJATextInform 3 "TJA is Active" 2 "TJA is cancelled" 1 "Unable to active TJA" 0 "No display" ;
VAL_ 576 FRM_TJAMod 7 "Reserved" 6 "Reserved" 5 "Reserved" 4 "Failure" 3 "Active mode" 2 "Stand-By mode" 1 "Passive mode" 0 "OFF mode" ;
VAL_ 585 MPC_LeVislzn 3 "Warning" 2 "Intervention" 1 "Line tracking" 0 "No display" ;
VAL_ 585 MPC_RiVislzn 3 "Warning" 2 "Intervention" 1 "Line tracking" 0 "No display" ;
VAL_ 585 MPC_HBASts 7 "Reserved" 6 "Reserved" 5 "Camera blocked" 4 "Fault" 3 "Active" 2 "Passive" 1 "Off" 0 "No information" ;
VAL_ 585 MPC_LaneAsistTyp 7 "Reserved" 6 "Reserved" 5 "Reserved" 4 "TJA/ICA" 3 "LKA" 2 "LDW" 1 "Not selected" 0 "No information" ;
VAL_ 585 MPC_LDW_Sts 7 "Reserved" 6 "Reserved" 5 "Camera blocked" 4 "Fault" 3 "Active" 2 "Standby" 1 "Off" 0 "No information" ;
VAL_ 585 MPC_LKA_Sts 7 "Reserved" 6 "Reserved" 5 "Camera blocked" 4 "Fault" 3 "Active" 2 "Standby" 1 "Off" 0 "No information" ;
VAL_ 585 MPC_ADAS_Snvty 3 "HighSensitivity" 2 "NormalSensitivity" 1 "LowSensitivity" 0 "No information" ;
VAL_ 585 MPC_TakeoverReq 1 "Active" 0 "Inactive" ;
VAL_ 585 MPC_WarnAud 1 "Active" 0 "Inactive" ;
VAL_ 340 APA_RLCDst 15 "Invalid" 14 "Invalid" 13 "Invalid" 12 "Invalid" 11 "Invalid" 10 "Invalid" 9 "Invalid" 8 "Invalid" 7 "Invalid" 6 "Invalid" 5 "Invalid" 4 "Invalid" 3 "Invalid" 2 "Dst range of RLC is from 30cm to 60cm" 1 "Dst of RLC is less than 30cm" 0 "No Obstcl Detected" ;
VAL_ 340 APA_RLMDst 15 "Reserved" 14 "Reserved" 13 "Reserved" 12 "Reserved" 11 "Reserved" 10 "Reserved" 9 "Reserved" 8 "Reserved" 7 "Reserved" 6 "Reserved" 5 "Reserved" 4 "Reserved" 3 "Dst range of RLM is from 80cm to 150cm" 2 "Dst range of RLM is from 30cm to 80cm" 1 "Dst of RLM is less than 30cm" 0 "No Obstcl Detected" ;
VAL_ 340 APA_RRCDst 15 "Invalid" 14 "Invalid" 13 "Invalid" 12 "Invalid" 11 "Invalid" 10 "Invalid" 9 "Invalid" 8 "Invalid" 7 "Invalid" 6 "Invalid" 5 "Invalid" 4 "Invalid" 3 "Invalid" 2 "Dst range of RRC is from 30cm to 60cm" 1 "Dst of RRC is less than 30cm" 0 "No Obstcl Detected" ;
VAL_ 340 APA_RRMDst 15 "Reserved" 14 "Reserved" 13 "Reserved" 12 "Reserved" 11 "Reserved" 10 "Reserved" 9 "Reserved" 8 "Reserved" 7 "Reserved" 6 "Reserved" 5 "Reserved" 4 "Reserved" 3 "Dst range of RRM is from 80cm to 150cm" 2 "Dst range of RRM is from 30cm to 80cm" 1 "Dst of RRM is less than 30cm" 0 "No Obstcl Detected" ;
VAL_ 340 APA_FLCDst 15 "Invalid" 14 "Invalid" 13 "Invalid" 12 "Invalid" 11 "Invalid" 10 "Invalid" 9 "Invalid" 8 "Invalid" 7 "Invalid" 6 "Invalid" 5 "Invalid" 4 "Invalid" 3 "Invalid" 2 "Dst range of FLC is from 30cm to 60cm" 1 "Dst of FLC is less than 30cm" 0 "No Obstcl Detected" ;
VAL_ 340 APA_FLMDst 15 "Reserved" 14 "Reserved" 13 "Reserved" 12 "Reserved" 11 "Reserved" 10 "Reserved" 9 "Reserved" 8 "Reserved" 7 "Reserved" 6 "Reserved" 5 "Reserved" 4 "Reserved" 3 "Dst range of FLM is from 80cm to 100cm" 2 "Dst range of FLM is from 30cm to 80cm" 1 "Dst of FLM is less than 30cm" 0 "No Obstcl Detected" ;
VAL_ 340 APA_FRCDst 15 "Invalid" 14 "Invalid" 13 "Invalid" 12 "Invalid" 11 "Invalid" 10 "Invalid" 9 "Invalid" 8 "Invalid" 7 "Invalid" 6 "Invalid" 5 "Invalid" 4 "Invalid" 3 "Invalid" 2 "Dst range of FRC is from 30cm to60cm" 1 "Dst of FRC is less than 30cm" 0 "No Obstcl Detected" ;
VAL_ 340 APA_FRMDst 15 "Reserved" 14 "Reserved" 13 "Reserved" 12 "Reserved" 11 "Reserved" 10 "Reserved" 9 "Reserved" 8 "Reserved" 7 "Reserved" 6 "Reserved" 5 "Reserved" 4 "Reserved" 3 "Dst range of FRM is from 80cm to 100cm" 2 "Dst range of FRM is from 30cm to 80cm" 1 "Dst of FRM is less than 30cm" 0 "No Obstcl Detected" ;
VAL_ 340 APA_RLSnsrDst 7 "Invalid" 6 "Invalid" 5 "Invalid" 4 "Invalid" 3 "Invalid" 2 "Dst range of RLS is from 30cm to 60cm" 1 "Dst of RLS is less than 30cm" 0 "No Obstcl Detected" ;
VAL_ 340 APA_RRSnsrDst 7 "Invalid" 6 "Invalid" 5 "Invalid" 4 "Invalid" 3 "Invalid" 2 "Dst range of RRS is from 30cm to 60cm" 1 "Dst of RRS is less than 30cm" 0 "No Obstcl Detected" ;
VAL_ 340 APA_FLSnsrDst 7 "Invalid" 6 "Invalid" 5 "Invalid" 4 "Invalid" 3 "Invalid" 2 "Dst range of FLS is from 30cm to 60cm" 1 "Dst of FLS is less than 30cm" 0 "No Obstcl Detected" ;
VAL_ 340 APA_FRSnsrDst 7 "Invalid" 6 "Invalid" 5 "Invalid" 4 "Invalid" 3 "Invalid" 2 "Dst range of FRS is from 30cm to 60cm" 1 "Dst of FRS is less than 30cm" 0 "No Obstcl Detected" ;
VAL_ 340 APA_FrntNearestDst 255 "Invalid" 254 "Invalid" 253 "Invalid" 252 "Invalid" 251 "Invalid" ;
VAL_ 340 APA_ReNearestDst 255 "Invalid" 254 "Invalid" 253 "Invalid" 252 "Invalid" 251 "Invalid" ;
VAL_ 653 APA_SysFltFlg 3 "System Failure" 2 "Rear Failure" 1 "Front Failure" 0 "No Failure" ;
VAL_ 653 APA_WarnIdn 3 "Error Warning(1500Hz)" 2 "Rear Corner(750Hz)" 1 "Front Corner(940Hz)" 0 "No Waring" ;
VAL_ 653 APA_WarnTyp 15 "Reserved" 14 "Reserved" 13 "Reserved" 12 "Reserved" 11 "Reserved" 10 "Reserved" 9 "Reserved" 8 "Reserved" 7 "系统无错误提示（鸣叫0.5s）（预留）" 6 "错误3s报警（长鸣3s）" 5 "长鸣区前后同时报警（前角报警0.5s，后角报警0.5s）" 4 "间歇音3报警（预留）" 3 "间歇音2报警（报警75ms，不报警425ms）" 2 "间歇音1报警（报警75ms，不报警175ms）" 1 "长鸣区报警" 0 "不报警" ;
VAL_ 653 APA_RecoverINTIndcn 7 "Reserved" 6 "Reserved" 5 "Reserved" 4 "Reserved" 3 "ReqRecover_Release Brake" 2 "ReqRecover_FoundObstclTrajectory" 1 "ReqRecover_Dead Man Swch Rels" 0 "No Request" ;
VAL_ 653 APA_QuitIndcn 31 "Reserved" 30 "Reserved" 29 "Reserved" 28 "Reserved" 27 "Reserved" 26 "Reserved" 25 "Reserved" 24 "Reserved" 23 "Reserved" 22 "Reserved" 21 "Reserved" 20 "Reserved" 19 "Req_Quit_Steering Wheel Hands On" 18 "Req_Quit_Gear Interrupt" 17 "Req_Quit_Vehicle Block" 16 "Req_Quit_EPB_Apply" 15 "Req_Quit_Driver_Door" 14 "Req_Quit_Seat belt unbuckle" 13 "Req_Quit_No object in front" 12 "Req_Quit_Space limit" 11 "Req_Quit_Trajectory" 10 "Req_Quit_ACC" 9 "Req_Quit_External ECU actvie" 8 "Req_Quit_Gear Intervention" 7 "Req_Quit_Gas pedal" 6 "Req_Quit_Recover_Int_Tims_Overflow" 5 "Req_Quit_Move times overflow" 4 "Req_Quit_Timing overflow" 3 "Req_Quit_Speed high" 2 "Req_Quit_APA_Failure" 1 "Req_Quit_External ECU failure" 0 "No Request (invalid_for_GW)" ;
VAL_ 653 APA_FctIndcn 7 "Reserved" 6 "Reserved" 5 "Reserved" 4 "cPOC Active" 3 "pPOC Active" 2 "cPSC Active" 1 "pPSC Active" 0 "No Active" ;
VAL_ 653 APA_St 7 "Reserved" 6 "Terminate" 5 "Failure" 4 "Completed" 3 "Guidance Active" 2 "Searching" 1 "Standby Enabled" 0 "Off" ;
VAL_ 653 APA_PrkSlotSt 3 "Slot_Right & Left" 2 "Slot_Right" 1 "Slot_Left" 0 "No Slot" ;
VAL_ 653 APA_SeltSide 3 "Invalid" 2 "Right" 1 "Left" 0 "None" ;
VAL_ 653 APA_PrkNotice 31 "Reserved" 30 "Reserved" 29 "Reserved" 28 "Reserved" 27 "Reserved" 26 "Reserved" 25 "Reserved" 24 "Reserved" 23 "Req_Gear R and Brake" 22 "Req_Press Brake Pedal" 21 "Req_Repress Dead Man Switch" 20 "Req_Buckle Seat Belt" 19 "Req_Close Door" 18 "Req_Release Brake" 17 "Req_Slow_Down" 16 "Req_Drive_Bw" 15 "Req_Gear_D" 14 "Req_Gear_R" 13 "pPSC&cPSC request" 12 "cPSC request only" 11 "pPSC request only" 10 "Req_Process bar" 9 "Req_Function off" 8 "Req_Function Select" 7 "Req_Stop" 6 "Req_Drive_Fw" 5 "Req_SearchingProcess" 4 "Req_Confirm_Switch" 3 "Req_Gear_P" 2 "Req_Turn_lever" 1 "Req_Forward_Again" 0 "No Request" ;
VAL_ 653 APA_Mod 7 "Reserved" 6 "Reserved" 5 "System Failure" 4 "Rear Active" 3 "Front Active" 2 "Front Rear Active" 1 "Standby" 0 "Off" ;
VAL_ 653 APA_PAS_BtnPrs 1 "Off" 0 "On" ;
VAL_ 653 APA_PrkgPerc 127 "Invalid" 126 "Invalid" 125 "Invalid" 124 "Invalid" 123 "Invalid" 122 "Invalid" 121 "Invalid" 120 "Invalid" 119 "Invalid" 118 "Invalid" 117 "Invalid" 116 "Invalid" 115 "Invalid" 114 "Invalid" 113 "Invalid" 112 "Invalid" 111 "Invalid" 110 "Invalid" 109 "Invalid" 108 "Invalid" 107 "Invalid" 106 "Invalid" 105 "Invalid" 104 "Invalid" 103 "Invalid" 102 "Invalid" 101 "Invalid" ;
VAL_ 653 RMR_L_RCTA_WarnReq 3 "Reserved" 2 "Warning level 2" 1 "Warning level 1" 0 "No warning" ;
VAL_ 653 RMR_R_RCTA_WarnReq 3 "Reserved" 2 "Warning level 2" 1 "Warning level 1" 0 "No warning" ;
VAL_ 653 RMR_RSDS_BliSts 1 "Blindness" 0 "No Blindness" ;
VAL_ 653 RMR_RCTAResp 1 "RCTA ON" 0 "RCTA OFF" ;
VAL_ 653 RMR_LCAResp 1 "LCA ON" 0 "LCA OFF" ;
VAL_ 653 RMR_DOWResp 1 "ON" 0 "OFF" ;
VAL_ 653 RMR_RSDS_LCA_RCTA_ErrSts 1 "Error" 0 "No Error" ;
VAL_ 653 RMR_RSDS_DOW_ErrSts 3 "Reserved" 2 "Function Limited" 1 "Error" 0 "No Error" ;
VAL_ 653 RMR_L_DOW_WarnReq 7 "Reserved" 6 "Reserved" 5 "Reserved" 4 "Warning level 2 Both L" 3 "Warning level 2 RL" 2 "Warning level 2 FL" 1 "Warning level 1" 0 "No warning" ;
VAL_ 653 RMR_R_DOW_WarnReq 7 "Reserved" 6 "Reserved" 5 "Reserved" 4 "Warning level 2 Both R" 3 "Warning level 2 RR" 2 "Warning level 2 FR" 1 "Warning level 1" 0 "No warning" ;
VAL_ 653 RMR_L_BSD_LCA_WarnReq 3 "Reserved" 2 "Warning level 2" 1 "Warning level 1" 0 "No warning" ;
VAL_ 653 RMR_R_BSD_LCA_WarnReq 3 "Reserved" 2 "Warning level 2" 1 "Warning level 1" 0 "No warning" ;
VAL_ 407 Clim_FootModStsDisp 1 "On" 0 "Off" ;
VAL_ 407 Clim_FaceModStsDisp 1 "On" 0 "Off" ;
VAL_ 407 Clim_BlwrFlowDisp 15 "Reserved" 14 "Reserved" 13 "Reserved" 12 "Reserved" 11 "Reserved" 10 "Reserved" 9 "Reserved" 8 "Level 8" 7 "Level 7" 6 "Level 6" 5 "Level 5" 4 "Level 4" 3 "Level 3" 2 "Level 2" 1 "Level 1" 0 "Level 0" ;
VAL_ 407 Clim_PM25Disp 1001 "Invalid" ;
VAL_ 407 Clim_DrvrTmpDisp 255 "Reserved" 254 "Reserved" 253 "Reserved" 252 "Reserved" 251 "Reserved" 250 "Reserved" 249 "Reserved" 248 "Reserved" 247 "Reserved" 246 "Reserved" 245 "Reserved" 244 "Reserved" 243 "Reserved" 242 "Reserved" 241 "Reserved" 240 "Reserved" 239 "Reserved" 238 "Reserved" 237 "Reserved" 236 "Reserved" 235 "Reserved" 234 "Reserved" 233 "Reserved" 232 "Reserved" 231 "Reserved" 230 "Reserved" 229 "Reserved" 228 "Reserved" 227 "Reserved" 226 "Reserved" 225 "Reserved" 224 "Reserved" 223 "Reserved" 222 "Reserved" 221 "Reserved" 220 "Reserved" 219 "Reserved" 218 "Reserved" 217 "Reserved" 216 "Reserved" 215 "Reserved" 214 "Reserved" 213 "Reserved" 212 "Reserved" 211 "Reserved" 210 "Reserved" 209 "Reserved" 208 "Reserved" 207 "Reserved" 206 "Reserved" 205 "Reserved" 204 "Reserved" 203 "Reserved" 202 "Reserved" 201 "Reserved" 200 "Reserved" 199 "Reserved" 198 "Reserved" 197 "Reserved" 196 "Reserved" 195 "Reserved" 194 "Reserved" 193 "Reserved" 192 "Reserved" 191 "Reserved" 190 "Reserved" 189 "Reserved" 188 "Reserved" 187 "Reserved" 186 "Reserved" 185 "Reserved" 184 "Reserved" 183 "Reserved" 182 "Reserved" 181 "Reserved" 180 "Reserved" 179 "Reserved" 178 "Reserved" 177 "Reserved" 176 "Reserved" 175 "Reserved" 174 "Reserved" 173 "Reserved" 172 "Reserved" 171 "Reserved" 170 "Reserved" 169 "Reserved" 168 "Reserved" 167 "Reserved" 166 "Reserved" 165 "Reserved" 164 "Reserved" 163 "Reserved" 162 "Reserved" 161 "Reserved" 160 "Reserved" 159 "Reserved" 158 "Reserved" 157 "Reserved" 156 "Reserved" 155 "Reserved" 154 "Reserved" 153 "Reserved" 152 "Reserved" 151 "Reserved" 150 "Reserved" 149 "Reserved" 148 "Reserved" 147 "Reserved" 146 "Reserved" 145 "Reserved" 144 "Reserved" 143 "Reserved" 142 "Reserved" 141 "Reserved" 140 "Reserved" 139 "Reserved" 138 "Reserved" 137 "Reserved" 136 "Reserved" 135 "Reserved" 134 "Reserved" 133 "Reserved" 132 "Reserved" 131 "Reserved" 130 "Reserved" 129 "Reserved" 128 "Reserved" 127 "Reserved" 126 "Reserved" 125 "Reserved" 124 "Reserved" 123 "Reserved" 122 "Reserved" 121 "Reserved" 120 "Reserved" 119 "Reserved" 118 "Reserved" 117 "Reserved" 116 "Reserved" 115 "Reserved" 114 "Reserved" 113 "Reserved" 112 "Reserved" 111 "Reserved" 110 "Reserved" 109 "Reserved" 108 "Reserved" 107 "Reserved" 106 "Reserved" 105 "Reserved" 104 "Reserved" 103 "Reserved" 102 "Reserved" 101 "Reserved" 100 "Reserved" 99 "Reserved" 98 "Reserved" 97 "Reserved" 96 "Reserved" 95 "Reserved" 94 "Reserved" 93 "Reserved" 92 "Reserved" 91 "Reserved" 90 "Reserved" 89 "Reserved" 88 "Reserved" 87 "Reserved" 86 "Reserved" 85 "Reserved" 84 "Reserved" 83 "Reserved" 82 "Reserved" 81 "Reserved" 80 "Reserved" 79 "Reserved" 78 "Reserved" 77 "Reserved" 76 "Reserved" 75 "Reserved" 74 "Reserved" 73 "Reserved" 72 "Reserved" 71 "Reserved" 70 "Reserved" 69 "Reserved" 68 "Reserved" 67 "Reserved" 66 "Reserved" 65 "Reserved" 64 "Reserved" 63 "Reserved" 62 "Reserved" 61 "Reserved" 60 "Reserved" 59 "Reserved" 58 "Reserved" 57 "Reserved" 56 "Reserved" 55 "Reserved" 54 "Reserved" 53 "Reserved" 52 "Reserved" 51 "Reserved" 50 "Reserved" 49 "Reserved" 48 "Reserved" 47 "Reserved" 46 "Reserved" 45 "Reserved" 44 "Reserved" 43 "Reserved" 42 "Reserved" 41 "Reserved" 40 "Reserved" 39 "Reserved" 38 "Reserved" 37 "Reserved" 36 "Reserved" 35 "Reserved" 34 "Reserved" 33 "Reserved" 32 "Reserved" 31 "Reserved" 30 "Reserved" 29 "Reserved" 28 "Reserved" 27 "Reserved" 26 "Reserved" 25 "Reserved" 24 "Reserved" 23 "Reserved" 22 "Reserved" 21 "Reserved" 20 "Reserved" 19 "Reserved" 18 "Reserved" 17 "Reserved" 16 "HI" 15 "30℃" 14 "29℃" 13 "28℃" 12 "27℃" 11 "26℃" 10 "25℃" 9 "24℃" 8 "23℃" 7 "22℃" 6 "21℃" 5 "20℃" 4 "19℃" 3 "18℃" 2 "17℃" 1 "16℃" 0 "LO" ;
VAL_ 407 Clim_PassTmpDisp 255 "Reserved" 254 "Reserved" 253 "Reserved" 252 "Reserved" 251 "Reserved" 250 "Reserved" 249 "Reserved" 248 "Reserved" 247 "Reserved" 246 "Reserved" 245 "Reserved" 244 "Reserved" 243 "Reserved" 242 "Reserved" 241 "Reserved" 240 "Reserved" 239 "Reserved" 238 "Reserved" 237 "Reserved" 236 "Reserved" 235 "Reserved" 234 "Reserved" 233 "Reserved" 232 "Reserved" 231 "Reserved" 230 "Reserved" 229 "Reserved" 228 "Reserved" 227 "Reserved" 226 "Reserved" 225 "Reserved" 224 "Reserved" 223 "Reserved" 222 "Reserved" 221 "Reserved" 220 "Reserved" 219 "Reserved" 218 "Reserved" 217 "Reserved" 216 "Reserved" 215 "Reserved" 214 "Reserved" 213 "Reserved" 212 "Reserved" 211 "Reserved" 210 "Reserved" 209 "Reserved" 208 "Reserved" 207 "Reserved" 206 "Reserved" 205 "Reserved" 204 "Reserved" 203 "Reserved" 202 "Reserved" 201 "Reserved" 200 "Reserved" 199 "Reserved" 198 "Reserved" 197 "Reserved" 196 "Reserved" 195 "Reserved" 194 "Reserved" 193 "Reserved" 192 "Reserved" 191 "Reserved" 190 "Reserved" 189 "Reserved" 188 "Reserved" 187 "Reserved" 186 "Reserved" 185 "Reserved" 184 "Reserved" 183 "Reserved" 182 "Reserved" 181 "Reserved" 180 "Reserved" 179 "Reserved" 178 "Reserved" 177 "Reserved" 176 "Reserved" 175 "Reserved" 174 "Reserved" 173 "Reserved" 172 "Reserved" 171 "Reserved" 170 "Reserved" 169 "Reserved" 168 "Reserved" 167 "Reserved" 166 "Reserved" 165 "Reserved" 164 "Reserved" 163 "Reserved" 162 "Reserved" 161 "Reserved" 160 "Reserved" 159 "Reserved" 158 "Reserved" 157 "Reserved" 156 "Reserved" 155 "Reserved" 154 "Reserved" 153 "Reserved" 152 "Reserved" 151 "Reserved" 150 "Reserved" 149 "Reserved" 148 "Reserved" 147 "Reserved" 146 "Reserved" 145 "Reserved" 144 "Reserved" 143 "Reserved" 142 "Reserved" 141 "Reserved" 140 "Reserved" 139 "Reserved" 138 "Reserved" 137 "Reserved" 136 "Reserved" 135 "Reserved" 134 "Reserved" 133 "Reserved" 132 "Reserved" 131 "Reserved" 130 "Reserved" 129 "Reserved" 128 "Reserved" 127 "Reserved" 126 "Reserved" 125 "Reserved" 124 "Reserved" 123 "Reserved" 122 "Reserved" 121 "Reserved" 120 "Reserved" 119 "Reserved" 118 "Reserved" 117 "Reserved" 116 "Reserved" 115 "Reserved" 114 "Reserved" 113 "Reserved" 112 "Reserved" 111 "Reserved" 110 "Reserved" 109 "Reserved" 108 "Reserved" 107 "Reserved" 106 "Reserved" 105 "Reserved" 104 "Reserved" 103 "Reserved" 102 "Reserved" 101 "Reserved" 100 "Reserved" 99 "Reserved" 98 "Reserved" 97 "Reserved" 96 "Reserved" 95 "Reserved" 94 "Reserved" 93 "Reserved" 92 "Reserved" 91 "Reserved" 90 "Reserved" 89 "Reserved" 88 "Reserved" 87 "Reserved" 86 "Reserved" 85 "Reserved" 84 "Reserved" 83 "Reserved" 82 "Reserved" 81 "Reserved" 80 "Reserved" 79 "Reserved" 78 "Reserved" 77 "Reserved" 76 "Reserved" 75 "Reserved" 74 "Reserved" 73 "Reserved" 72 "Reserved" 71 "Reserved" 70 "Reserved" 69 "Reserved" 68 "Reserved" 67 "Reserved" 66 "Reserved" 65 "Reserved" 64 "Reserved" 63 "Reserved" 62 "Reserved" 61 "Reserved" 60 "Reserved" 59 "Reserved" 58 "Reserved" 57 "Reserved" 56 "Reserved" 55 "Reserved" 54 "Reserved" 53 "Reserved" 52 "Reserved" 51 "Reserved" 50 "Reserved" 49 "Reserved" 48 "Reserved" 47 "Reserved" 46 "Reserved" 45 "Reserved" 44 "Reserved" 43 "Reserved" 42 "Reserved" 41 "Reserved" 40 "Reserved" 39 "Reserved" 38 "Reserved" 37 "Reserved" 36 "Reserved" 35 "Reserved" 34 "Reserved" 33 "Reserved" 32 "Reserved" 31 "Reserved" 30 "Reserved" 29 "Reserved" 28 "Reserved" 27 "Reserved" 26 "Reserved" 25 "Reserved" 24 "Reserved" 23 "Reserved" 22 "Reserved" 21 "Reserved" 20 "Reserved" 19 "Reserved" 18 "Reserved" 17 "Reserved" 16 "HI" 15 "30℃" 14 "29℃" 13 "28℃" 12 "27℃" 11 "26℃" 10 "25℃" 9 "24℃" 8 "23℃" 7 "22℃" 6 "21℃" 5 "20℃" 4 "19℃" 3 "18℃" 2 "17℃" 1 "16℃" 0 "LO" ;
VAL_ 407 Clim_ClimSwchStsDisp 1 "On" 0 "Off" ;
VAL_ 407 Clim_ACStsDisp 1 "On" 0 "Off" ;
VAL_ 407 Clim_FrntDefrostingStsDisp 1 "On" 0 "Off" ;
VAL_ 407 Clim_ReDefrostingStsDisp 1 "On" 0 "Off" ;
VAL_ 407 Clim_AUTOModStsDisp 1 "On" 0 "Off" ;
VAL_ 407 Clim_Int_ExtCirculnStsDisp 1 "Manual external circulation" 0 "Manual internal  circulation" ;
VAL_ 407 Clim_BlwGlassModStsDisp 1 "On" 0 "Off" ;
VAL_ 407 Clim_DUALSwchDisp 1 "On" 0 "Off" ;
VAL_ 654 Clim_AnionGenSwchSts 1 "On" 0 "Off" ;
VAL_ 654 VSG_AlrmSts 3 "Not used" 2 "Reserved" 1 "Off" 0 "On" ;
VAL_ 654 PBD_RearDoorStatus 7 "Reserved" 6 "Reserved" 5 "Reserved" 4 "Reserved" 3 "Opening" 2 "Opened" 1 "Closing" 0 "Closed" ;
VAL_ 654 PBD_RearDoorStsVld 1 "Invalidity" 0 "Validity" ;
VAL_ 654 LS_Brightness_IR 255 "Invalid" ;
VAL_ 654 LS_Brightnes_FW 1023 "Invalid" ;
VAL_ 654 RS_Error 1 "Error" 0 "Normal" ;
VAL_ 654 LS_Error 1 "Error" 0 "Normal" ;
VAL_ 654 iBCM_BrkLiSts 1 "On" 0 "Off" ;
VAL_ 654 SR_SrPosition 7 "Uninitialized" 6 "Fully open" 5 "Partially slide" 4 "Antipinch in partially slide" 3 "Fully close" 2 "Antipinch in vent" 1 "Vent area" 0 "Tilt up" ;
VAL_ 654 FLW_FLDoorWindowsPosition 15 "Reserved" 14 "Reserved" 13 "Reserved" 12 "Reserved" 11 "Reserved" 10 "Reserved" 9 "Reserved" 8 "Fully open" 7 "Between large mid-opening and fully open" 6 "Large mid-opening position" 5 "Between slight opening and large mid-opening" 4 "Slight opening" 3 "Between short drop position and slight opening" 2 "Short drop position" 1 "Between closed and short drop position" 0 "Closed" ;
VAL_ 654 FRW_FRDoorWindowsPosition 15 "Reserved" 14 "Reserved" 13 "Reserved" 12 "Reserved" 11 "Reserved" 10 "Reserved" 9 "Reserved" 8 "Fully open" 7 "Between large mid-opening and fully open" 6 "Large mid-opening position" 5 "Between slight opening and large mid-opening" 4 "Slight opening" 3 "Between short drop position and slight opening" 2 "Short drop position" 1 "Between closed and short drop position" 0 "Closed" ;
VAL_ 654 RLW_RLDoorWindowsPosition 15 "Reserved" 14 "Reserved" 13 "Reserved" 12 "Reserved" 11 "Reserved" 10 "Reserved" 9 "Reserved" 8 "Fully open" 7 "Between large mid-opening and fully open" 6 "Large mid-opening position" 5 "Between slight opening and large mid-opening" 4 "Slight opening" 3 "Between short drop position and slight opening" 2 "Short drop position" 1 "Between closed and short drop position" 0 "Closed" ;
VAL_ 654 RRW_RRDoorWindowsPosition 15 "Reserved" 14 "Reserved" 13 "Reserved" 12 "Reserved" 11 "Reserved" 10 "Reserved" 9 "Reserved" 8 "Fully open" 7 "Between large mid-opening and fully open" 6 "Large mid-opening position" 5 "Between slight opening and large mid-opening" 4 "Slight opening" 3 "Between short drop position and slight opening" 2 "Short drop position" 1 "Between closed and short drop position" 0 "Closed" ;
VAL_ 914 DSM_DrvrSeatHeatgStsFb 7 "Reserved" 6 "Reserved" 5 "Reserved" 4 "Error" 3 "Level 3" 2 "Level 2" 1 "Level 1" 0 "Off" ;
VAL_ 914 DSM_PassSeatHeatgStsFb 7 "Reserved" 6 "Reserved" 5 "Reserved" 4 "Error" 3 "Level 3" 2 "Level 2" 1 "Level 1" 0 "Off" ;
VAL_ 914 DSM_SeatPosnMemReq 1 "Request" 0 "No Request" ;
VAL_ 914 DSM_SeatVertAdjMotCurPosn 127 "Invalid" ;
VAL_ 914 DSM_SeatHznAdjMotCurPosn 127 "Invalid" ;
VAL_ 914 DSM_SeatTltgtAdjMotCurPosn 127 "Invalid" ;
VAL_ 914 DSM_SeatVertAdjtStsFb 7 "Reserved" 6 "Reserved" 5 "Reserved" 4 "Manual Intervention" 3 "Error" 2 "Reach Target Position" 1 "Action" 0 "No Action" ;
VAL_ 914 DSM_SeatHznAdjStsFb 7 "Reserved" 6 "Reserved" 5 "Reserved" 4 "Manual Intervention" 3 "Error" 2 "Reach Target Position" 1 "Action" 0 "No Action" ;
VAL_ 914 DSM_SeatTltgtAdjStsFb 7 "Reserved" 6 "Reserved" 5 "Reserved" 4 "Manual Intervention" 3 "Error" 2 "Reach Target Position" 1 "Action" 0 "No Action" ;
